VERSION ""

NS_ :

BS_:

BU_: RRSRR_FO LRSRR_FO CIPM_FO _DOFIMU2_FO _DOFIMU1_FO DMS_FO AMM_FO EOCM2B_IMX6_FO EOCM2B_K2_FO EOCM2B_K1_FO EOCM2A_IMX6_FO EOCM2A_K2_FO EOCM2A_K1_FO NVS_FO Dummy_FO TestTool_FO LRR_FO RFSRR_FO LFSRR_FO RSRR_FO VIS_FO EOCM_F_FO VIS2_FO
VAL_TABLE_ vt_BooleanValues 1 "true" 0 "false" ;
VAL_TABLE_ FrntVsnInPthVehBrkNwSt 10 "Active" 5 "Inactive" ;
VAL_TABLE_ FrntVsnClostPedBrkNwSt 10 "Active" 5 "Inactive" ;
VAL_TABLE_ DrvrMonSysEngSt 7 "Unused and Reserved 1" 6 "Recovering" 5 "Tracking" 4 "Searching" 3 "Video test port only" 2 "Idle" 1 "Invalid state" 0 "Does not exist or DME" ;
VAL_TABLE_ DrvrMonEngUnrecvrFltCod 7 "Unused and Reserved 3" 6 "Unused and Reserved 2" 5 "Unused and Reserved 1" 4 "Vehicle power supply Errors" 3 "Problem with LED illuminators" 2 "Vehicle input signals Errors" 1 "Problem with imager" 0 "Ok" ;
VAL_TABLE_ DrvrMonEngRecvrFltCod 3 "Engine is unable to find a face" 2 "Input Images too dark" 1 "Input images too bright" 0 "Ok" ;
VAL_TABLE_ DrvrMntrSysVTP 1 "Video test port active" 0 "Video test port inactive" ;
VAL_TABLE_ DrvrAttnStatCnfdc 3 "High" 2 "Medium" 1 "Low" 0 "Lowest" ;
VAL_TABLE_ DrvrAttnStat 7 "Invalid" 6 "Driver is exhibiting sleep" 5 "Driver is exhibiting microsleep" 4 "Attention is Center Console" 3 "Attention is Drivers Lap" 2 "Attention is Off Road" 1 "Attention is On Road" 0 "Unknown" ;
VAL_TABLE_ PPSMd 7 "GNSS and RTX and DR and MM" 6 "DR ONLY" 5 "GNSS and RTX and DR" 4 "GNSS and SBAS and DR" 3 "GNSS and DR" 2 "GNSS and  RTX" 1 "GNSS and SBAS" 0 "GNSS Standalone" ;
VAL_TABLE_ AdvDrvAstMpPrfShrtAcur 3 "Accuracy Is Unknown" 2 "Lowest Accuracy" 1 "Medium Accuracy" 0 "Highest Accuracy" ;
VAL_TABLE_ AdvDrAstMpStbRtOfWay 3 "Not Applicable" 2 "Unknown" 1 "Sub Path Has Right Of Way Over Path" 0 "Path Has Right Of Way Over Sub Path" ;
VAL_TABLE_ AdvDrAstMpStbPrtCalRut 3 "Not Applicable" 2 "Unknown" 1 "Path From This Point On Is Part Of Calculated Route" 0 "Path From This Point On Is Not Part Of Calculated Route" ;
VAL_TABLE_ AdvDrAstMpStbMsgTyp 7 "Unused and Reserved 2" 6 "Metadata" 5 "Profile Long" 4 "Profile Short" 3 "Stub" 2 "Segment" 1 "Position" 0 "Unused and Reserved 1" ;
VAL_TABLE_ AdvDrAstMpStbFmOfWay 15 "Not Applicable" 14 "Pedestrian Zone" 13 "Entrance To Or Exit To Service" 12 "Entrance To Or Exit Of A Car Park" 11 "Service Road Or Frontage Road" 10 "Slip Road per Ramp" 9 "Slip Road per Ramp On A Freeway Or Controlled Access Road" 8 "Parallel Road" 7 "Unused and Reserved 2" 6 "Unused and Reserved 1" 5 "Traffic Square per Special Traffic Figure" 4 "Roundabout Circle" 3 "Single Carriageway" 2 "Multiple Carriageway Or Multiply Digitized Road" 1 "Freeway Or Controlled Access Road That Is Not A Slip Road Or Ramp" 0 "Unknown" ;
VAL_TABLE_ AdvDrAstMpStbCmplxInsct 3 "Not Applicable" 2 "Unknown" 1 "Stub Is Part Of Complex Intersection" 0 "Stub Is Not Part Of Complex Intersection" ;
VAL_TABLE_ AdvDrAstMpSegTunl 3 "Not Applicable" 2 "Unknown" 1 "Segment Is Part Of Tunnel" 0 "Segment Is Not A Part Of Tunnel" ;
VAL_TABLE_ AdvDrAstMpSegPrtCalRut 3 "Not Applicable" 2 "Unknown" 1 "Segment Is Part Of Calculated Route" 0 "Segment Is Not Part Of Calculated Route" ;
VAL_TABLE_ AdvDrAstMpSegMsgTyp 7 "Unused and Reserved 2" 6 "Metadata" 5 "Profile Long" 4 "Profile Short" 3 "Stub" 2 "Segment" 1 "Position" 0 "Unused and Reserved 1" ;
VAL_TABLE_ AdvDrAstMpSegFrmOfWay 15 "Not Applicable" 14 "Pedestrian Zone" 13 "Entrance To Or Exit To Service" 12 "Entrance To Or Exit Of A Car Park" 11 "Service Road Or Frontage Road" 10 "Slip Road per Ramp" 9 "Slip Road per Ramp On A Freeway Or Controlled Access Road" 8 "Parallel Road" 7 "Unused and Reserved 2" 6 "Unused and Reserved 1" 5 "Traffic Square per Special Traffic Figure" 4 "Roundabout Circle" 3 "Single Carriageway" 2 "Multiple Carriageway Or Multiply Digitized Road" 1 "Freeway Or Controlled Access Road That Is Not A Slip Road or Ramp" 0 "Unknown" ;
VAL_TABLE_ AdvDrAstMpSegEffSdLmtTp 7 "Not Applicable" 6 "Explicit Snow" 5 "Explicit Rain" 4 "Explicit Time Of Day" 3 "Explicit By Day" 2 "Explicit By Night" 1 "Explicit On Traffic Sign" 0 "Implicit" ;
VAL_TABLE_ AdvDrAstMpSegDivdRd 3 "Not Applicable" 2 "Unknown" 1 "Segment Is Part Of Divided Road" 0 "Segment Is Not Part Of Divided Road" ;
VAL_TABLE_ AdvDrAstMpSegCmplxInsct 3 "Not Applicable" 2 "Unknown" 1 "Segment Is Part Of Complex Intersection" 0 "Segment Is Not Part Of Complex Intersection" ;
VAL_TABLE_ AdvDrAstMpSegBrdg 3 "Not Applicable" 2 "Unknown" 1 "Segment Is Part Of Bridge" 0 "Segment Not Part Of Bridge" ;
VAL_TABLE_ AdvDrAstMpSegBldUpAra 3 "Not Applicable" 2 "Unknown" 1 "Segment Is Part Of Built Up Area" 0 "Segment Is Not Part Of Built Up Area" ;
VAL_TABLE_ AdvDrAstMpMtdtSpdUnt 1 "Miles Per Hour" 0 "Kilometers Per Hour" ;
VAL_TABLE_ AdvDrAstMpMtdtDrvSd 1 "Driving Side Right" 0 "Driving Side Left" ;
VAL_TABLE_ WSMR_WiFiAssnReq 3 "Unexpected Undefined Connection Behavior" 2 "Wi Fi association failed with available credentials" 1 "Failed to receive Wi Fi credentials after 255 attempts" 0 "SSID and Passphrase Request" ;
VAL_TABLE_ StrgColCommsFlt 2 "Disabled Communications DTC" 1 "No Communications Fault" 0 "Communications Fault" ;
VAL_TABLE_ CPMAPINFO4 1 "Hardware Or Software Error" 0 "No Hardware Or Software Error" ;
VAL_TABLE_ AdvDrvAstMpPrfShrt2Acur 3 "Accuracy Is Unknown" 2 "Lowest Accuracy" 1 "Medium Accuracy" 0 "Highest Accuracy" ;
VAL_TABLE_ InterLghtStat 1 "Interior Lights On" 0 "Interior Light Off" ;
VAL_TABLE_ VehLnStatConf 2 "High Confidence" 1 "Low Confidence" 0 "No Confidence" 3 "Very High Confidence" ;
VAL_TABLE_ VehLnStat 3 "Lane Change To Right" 2 "Lane Change To Left" 1 "Staying in Lane" 0 "Unknown" ;
VAL_TABLE_ HrznPrvdRstRq 1 "Reset Not Required" 0 "Reset Required" ;
VAL_TABLE_ ExptNxtTrnstnDirConf 3 "Very High Confidence" 2 "High Confidence" 1 "Low Confidence" 0 "No Confidence" ;
VAL_TABLE_ ExptNxtTrnstnDir 7 "Reserved4" 6 "Reserved3" 5 "Reserved2" 4 "Reserved1" 3 "Traversing Middle Transition" 2 "Traversing Next Transition Right" 1 "Traversing Next Transition Left" 0 "Unknown" ;
VAL_TABLE_ ADASISMsgTypRetrans 7 "GM System Specific" 6 "Meta Data" 5 "Profile Long" 4 "Profile Short" 3 "Stub" 2 "Segment" 1 "Position" 0 "Checksum" ;
VAL_TABLE_ NVSysStat 7 "Needs Headlights" 6 "Temporarily Unavailable" 5 "Not Dark" 4 "Needs Service" 3 "Active" 2 "Inactive" 1 "Initializing" 0 "Unknown" ;
VAL_TABLE_ NVSysPedWrnIndReq 3 "Unused & Reserved" 2 "Pedestrian Alert" 1 "Pedestrian Detected" 0 "None" ;
VAL_TABLE_ NVSysPedDetCstReq 2 "On" 1 "Off" 0 "No Value" ;
VAL_TABLE_ NVSysPedDetCsCrStVal 2 "On" 1 "Off" 0 "No Value" ;
VAL_TABLE_ FwVsnCinCoutPotT9Rev 2 "Right" 1 "Left" 0 "None" ;
VAL_TABLE_ FwVsnCinCoutPotT8Rev 2 "Right" 1 "Left" 0 "None" ;
VAL_TABLE_ FwVsnCinCoutPotT7Rev 2 "Right" 1 "Left" 0 "None" ;
VAL_TABLE_ FwVsnCinCoutPotT6Rev 2 "Right" 1 "Left" 0 "None" ;
VAL_TABLE_ FwVsnCinCoutPotT5Rev 2 "Right" 1 "Left" 0 "None" ;
VAL_TABLE_ FwVsnCinCoutPotT4Rev 2 "Right" 1 "Left" 0 "None" ;
VAL_TABLE_ FwVsnCinCoutPotT3Rev 2 "Right" 1 "Left" 0 "None" ;
VAL_TABLE_ FwVsnCinCoutPotT2Rev 2 "Right" 1 "Left" 0 "None" ;
VAL_TABLE_ FwVsnCinCoutPotT1Rev 2 "Right" 1 "Left" 0 "None" ;
VAL_TABLE_ FwVsnCinCoutPotT12Rev 2 "Right" 1 "Left" 0 "None" ;
VAL_TABLE_ FwVsnCinCoutPotT11Rev 2 "Right" 1 "Left" 0 "None" ;
VAL_TABLE_ FwVsnCinCoutPotT10Rev 2 "Right" 1 "Left" 0 "None" ;
VAL_TABLE_ GFHBObjDirTrk8 1 "Ahead Traffic" 0 "Incoming Traffic" ;
VAL_TABLE_ GFHBObjDirTrk7 1 "Ahead Traffic" 0 "Incoming Traffic" ;
VAL_TABLE_ GFHBObjDirTrk6 1 "Ahead Traffic" 0 "Incoming Traffic" ;
VAL_TABLE_ GFHBObjDirTrk5 1 "Ahead Traffic" 0 "Incoming Traffic" ;
VAL_TABLE_ GFHBObjDirTrk4 1 "Ahead Traffic" 0 "Incoming Traffic" ;
VAL_TABLE_ GFHBObjDirTrk3 1 "Ahead Traffic" 0 "Incoming Traffic" ;
VAL_TABLE_ GFHBObjDirTrk2 1 "Ahead Traffic" 0 "Incoming Traffic" ;
VAL_TABLE_ GFHBObjDirTrk1 1 "Ahead Traffic" 0 "Incoming Traffic" ;
VAL_TABLE_ GFHBFwVsnRelLaneTrk8 3 "Left Lane" 2 "Right Lane" 1 "Host Lane" 0 "Unknown" ;
VAL_TABLE_ GFHBFwVsnRelLaneTrk7 3 "Left Lane" 2 "Right Lane" 1 "Host Lane" 0 "Unknown" ;
VAL_TABLE_ GFHBFwVsnRelLaneTrk6 3 "Left Lane" 2 "Right Lane" 1 "Host Lane" 0 "Unknown" ;
VAL_TABLE_ GFHBFwVsnRelLaneTrk5 3 "Left Lane" 2 "Right Lane" 1 "Host Lane" 0 "Unknown" ;
VAL_TABLE_ GFHBFwVsnRelLaneTrk4 3 "Left Lane" 2 "Right Lane" 1 "Host Lane" 0 "Unknown" ;
VAL_TABLE_ GFHBFwVsnRelLaneTrk3 3 "Left Lane" 2 "Right Lane" 1 "Host Lane" 0 "Unknown" ;
VAL_TABLE_ GFHBFwVsnRelLaneTrk2 3 "Left Lane" 2 "Right Lane" 1 "Host Lane" 0 "Unknown" ;
VAL_TABLE_ GFHBFwVsnRelLaneTrk1 3 "Left Lane" 2 "Right Lane" 1 "Host Lane" 0 "Unknown" ;
VAL_TABLE_ GFHBFwVsnMesStatTrk8 3 "Measured this cycle" 2 "Latent track not detected this cycle" 1 "New Object" 0 "No Object" ;
VAL_TABLE_ GFHBFwVsnMesStatTrk7 3 "Measured this cycle" 2 "Latent track not detected this cycle" 1 "New Object" 0 "No Object" ;
VAL_TABLE_ GFHBFwVsnMesStatTrk6 3 "Measured this cycle" 2 "Latent track not detected this cycle" 1 "New Object" 0 "No Object" ;
VAL_TABLE_ GFHBFwVsnMesStatTrk5 3 "Measured this cycle" 2 "Latent track not detected this cycle" 1 "New Object" 0 "No Object" ;
VAL_TABLE_ GFHBFwVsnMesStatTrk4 3 "Measured this cycle" 2 "Latent track not detected this cycle" 1 "New Object" 0 "No Object" ;
VAL_TABLE_ GFHBFwVsnMesStatTrk3 3 "Measured this cycle" 2 "Latent track not detected this cycle" 1 "New Object" 0 "No Object" ;
VAL_TABLE_ GFHBFwVsnMesStatTrk2 3 "Measured this cycle" 2 "Latent track not detected this cycle" 1 "New Object" 0 "No Object" ;
VAL_TABLE_ GFHBFwVsnMesStatTrk1 3 "Measured this cycle" 2 "Latent track not detected this cycle" 1 "New Object" 0 "No Object" ;
VAL_TABLE_ GFHBFwVsnCnfdncTrk8 3 "Confident" 2 "Speculative" 1 "Highly Speculative" 0 "Invalid" ;
VAL_TABLE_ GFHBFwVsnCnfdncTrk7 3 "Confident" 2 "Speculative" 1 "Highly Speculative" 0 "Invalid" ;
VAL_TABLE_ GFHBFwVsnCnfdncTrk6 3 "Confident" 2 "Speculative" 1 "Highly Speculative" 0 "Invalid" ;
VAL_TABLE_ GFHBFwVsnCnfdncTrk5 3 "Confident" 2 "Speculative" 1 "Highly Speculative" 0 "Invalid" ;
VAL_TABLE_ GFHBFwVsnCnfdncTrk4 3 "Confident" 2 "Speculative" 1 "Highly Speculative" 0 "Invalid" ;
VAL_TABLE_ GFHBFwVsnCnfdncTrk3 3 "Confident" 2 "Speculative" 1 "Highly Speculative" 0 "Invalid" ;
VAL_TABLE_ GFHBFwVsnCnfdncTrk2 3 "Confident" 2 "Speculative" 1 "Highly Speculative" 0 "Invalid" ;
VAL_TABLE_ GFHBFwVsnCnfdncTrk1 0 "Invalid" 3 "Confident" 2 "Speculative" 1 "Highly Speculative" ;
VAL_TABLE_ GFHBFVsnObjTypTrkRev8 12 "Cluster Object" 11 "Child Close to Danger Zone" 10 "Pedestrian Moving Out of Danger Zone" 9 "Pedestrian Moving Into Danger Zone" 8 "Pedestrian Standing Outside Danger Zone" 7 "No Object Present" 6 "Fixed Roadside Object" 5 "Fixed Overhead Object" 4 "Pedestrian" 3 "Motorcycle/ Bicycle" 2 "Large Vehicle (Semi)" 1 "4 Wheel Vehicle (Car)" 0 "Unknown" ;
VAL_TABLE_ GFHBFVsnObjTypTrkRev7 12 "Cluster Object" 11 "Child Close to Danger Zone" 10 "Pedestrian Moving Out of Danger Zone" 9 "Pedestrian Moving Into Danger Zone" 8 "Pedestrian Standing Outside Danger Zone" 7 "No Object Present" 6 "Fixed Roadside Object" 5 "Fixed Overhead Object" 4 "Pedestrian" 3 "Motorcycle/ Bicycle" 2 "Large Vehicle (Semi)" 1 "4 Wheel Vehicle (Car)" 0 "Unknown" ;
VAL_TABLE_ GFHBFVsnObjTypTrkRev6 12 "Cluster Object" 11 "Child Close to Danger Zone" 10 "Pedestrian Moving Out of Danger Zone" 9 "Pedestrian Moving Into Danger Zone" 8 "Pedestrian Standing Outside Danger Zone" 7 "No Object Present" 6 "Fixed Roadside Object" 5 "Fixed Overhead Object" 4 "Pedestrian" 3 "Motorcycle/ Bicycle" 2 "Large Vehicle (Semi)" 1 "4 Wheel Vehicle (Car)" 0 "Unknown" ;
VAL_TABLE_ GFHBFVsnObjTypTrkRev5 12 "Cluster Object" 11 "Child Close to Danger Zone" 10 "Pedestrian Moving Out of Danger Zone" 9 "Pedestrian Moving Into Danger Zone" 8 "Pedestrian Standing Outside Danger Zone" 7 "No Object Present" 6 "Fixed Roadside Object" 5 "Fixed Overhead Object" 4 "Pedestrian" 3 "Motorcycle/ Bicycle" 2 "Large Vehicle (Semi)" 1 "4 Wheel Vehicle (Car)" 0 "Unknown" ;
VAL_TABLE_ GFHBFVsnObjTypTrkRev4 12 "Cluster Object" 11 "Child Close to Danger Zone" 10 "Pedestrian Moving Out of Danger Zone" 9 "Pedestrian Moving Into Danger Zone" 8 "Pedestrian Standing Outside Danger Zone" 7 "No Object Present" 6 "Fixed Roadside Object" 5 "Fixed Overhead Object" 4 "Pedestrian" 3 "Motorcycle/ Bicycle" 2 "Large Vehicle (Semi)" 1 "4 Wheel Vehicle (Car)" 0 "Unknown" ;
VAL_TABLE_ GFHBFVsnObjTypTrkRev3 12 "Cluster Object" 11 "Child Close to Danger Zone" 10 "Pedestrian Moving Out of Danger Zone" 9 "Pedestrian Moving Into Danger Zone" 8 "Pedestrian Standing Outside Danger Zone" 7 "No Object Present" 6 "Fixed Roadside Object" 5 "Fixed Overhead Object" 4 "Pedestrian" 3 "Motorcycle/ Bicycle" 2 "Large Vehicle (Semi)" 1 "4 Wheel Vehicle (Car)" 0 "Unknown" ;
VAL_TABLE_ GFHBFVsnObjTypTrkRev2 12 "Cluster Object" 11 "Child Close to Danger Zone" 10 "Pedestrian Moving Out of Danger Zone" 9 "Pedestrian Moving Into Danger Zone" 8 "Pedestrian Standing Outside Danger Zone" 7 "No Object Present" 6 "Fixed Roadside Object" 5 "Fixed Overhead Object" 4 "Pedestrian" 3 "Motorcycle/ Bicycle" 2 "Large Vehicle (Semi)" 1 "4 Wheel Vehicle (Car)" 0 "Unknown" ;
VAL_TABLE_ GFHBFVsnObjTypTrkRev1 12 "Cluster Object" 11 "Child Close to Danger Zone" 10 "Pedestrian Moving Out of Danger Zone" 9 "Pedestrian Moving Into Danger Zone" 8 "Pedestrian Standing Outside Danger Zone" 7 "No Object Present" 6 "Fixed Roadside Object" 5 "Fixed Overhead Object" 4 "Pedestrian" 3 "Motorcycle/ Bicycle" 2 "Large Vehicle (Semi)" 1 "4 Wheel Vehicle (Car" 0 "Unknown" ;
VAL_TABLE_ CRL_Cnfdnc 7 "Reserved4" 6 "Reserved3" 5 "Reserved2" 4 "Reserved1" 3 "Best" 2 "Marking Present" 1 "Weak Marking" 0 "No Lane" ;
VAL_TABLE_ CLL_Cnfdnc 7 "Reserved4" 6 "Reserved3" 5 "Reserved2" 4 "Reserved1" 3 "Best" 2 "Marking Present" 1 "Weak Marking" 0 "No Lane" ;
VAL_TABLE_ VBBrkCtrlSt 4 "Release Control" 3 "Hold Vehicle" 2 "Apply Brake" 1 "Decrease Torque" 0 "No Action" ;
VAL_TABLE_ ObstacleType 6 "NO_OBJECT" 5 "OBJ_GUARDRAIL" 4 "OBJ_TUNNEL " 3 "OBJ_TRAFFIC_SIGN" 2 "OBJ_VEHICLE" 1 "OBJ_BRIDGE " 0 "OBJ_UNKNOWN" ;
VAL_TABLE_ VpathMode 2 "Mid Hi Speed" 1 "Low Speed" 0 "Disabled" ;
VAL_TABLE_ LaneChngStatus 2 "Lane Change Right" 1 "Lane Change Left" 0 "Idle" ;
VAL_TABLE_ TravelDirection 3 "Other (excessive side slip)" 2 "reverse / stopped in rvrs gear" 1 "Forward / stopped in frwd gear" 0 "Unknown" ;
VAL_TABLE_ TrueOrFalse 1 "true" 0 "false" ;
VAL_TABLE_ ModeCommand 5 "Sensing with Reduced Power" 4 "Undefined" 3 "Radio Silent" 2 "Sensing" 1 "Not Sensing" 0 "Undefined" ;
VAL_TABLE_ LaneSnsLLnPosValid 1 "Invalid" 0 "Valid" ;
VAL_TABLE_ LnSnsRLnPosValid 1 "Invalid" 0 "Valid" ;
VAL_TABLE_ Elevation 3 "Low " 2 "mid (reserved)" 1 "high " 0 "Unknown" ;
VAL_TABLE_ ModeCommandFdbk 5 "Sensing with reduced power" 4 "Undefined" 3 "Radio Silent" 2 "Sensing" 1 "Not Sensing" 0 "Undefined" ;
VAL_TABLE_ relativeLane 3 "Left Lane" 2 "Right Lane" 1 "Host Lane" 0 "Unknown" ;
VAL_TABLE_ RoadTypeInfo 5 "Constiction Zone Exit" 4 "Construction Zone Entry" 3 "Highway" 2 "Secondary Road" 1 "City" 0 "Unknown" ;
VAL_TABLE_ ObjectLossInfo 2 "elevation conditions" 1 "tight curve" 0 "not lost" ;
VAL_TABLE_ MeasurementStatus 3 "Measured this cycle" 2 "Latent track not detctd this cyc" 1 "New Object" 0 "No Object" ;
VAL_TABLE_ ObjectType 7 "no object present" 6 "fixed roadside object" 5 "fixed overhead object" 4 "pedestrian" 3 "motocycle  / bicycle" 2 "Large vehicle (semi)" 1 "4 Wheel Vehicle (car, small trk)" 0 "Unknown" ;
VAL_TABLE_ Confidence 3 "confident" 2 "speculative" 1 "highly speculative" 0 "invalid" ;
VAL_TABLE_ DynamicProp 4 "Moving in opposite direction" 3 "Moving in same direction as host" 2 "Has moved but currently stopped" 1 "Has never moved" 0 "Unknown" ;
VAL_TABLE_ DrvWndPosSt 6 "Fully Opened" 5 "Open More Than C" 4 "Position C" 3 "Position B" 2 "Position A" 1 "Open Less Than A" 0 "Fully Closed" ;
VAL_TABLE_ VehMovSta 4 "Invalid" 3 "Reverse" 2 "Forward" 1 "Neutral" 0 "Parked" ;
VAL_TABLE_ OtsdAmbtLtLvlStat 2 "Day" 1 "Night" 0 "Unknown" ;
VAL_TABLE_ RtTrnLmpAtv 2 "On with telltale" 1 "On without telltale" 0 "Off" ;
VAL_TABLE_ LftTrnLmpAtv 2 "On with telltale" 1 "On without telltale" 0 "Off" ;
VAL_TABLE_ HdlmpBmSelectStat 2 "High Beams" 1 "Low Beams" 0 "Unknown" ;
VAL_TABLE_ DTCI_DTCFaultType 3 "Type C" 2 "Type B" 1 "Type A" 0 "Not Supported" ;
VAL_TABLE_ TrnsShftLvrPos 13 "Forward Range J" 12 "Forward Range I" 15 "Lever Position Unknown" 11 "Forward Range H" 10 "Forward Range G" 9 "Forward Range F" 8 "Forward Range E" 7 "Forward Range D" 6 "Forward Range C" 5 "Forward Range B" 4 "Forward Range A" 3 "Neutral Range" 2 "Reverse Range" 1 "Park Range" 0 "Between Ranges" ;
VAL_TABLE_ SysPwrMd 3 "Crank Request" 2 "Run" 1 "Accessory" 0 "Off" ;
VAL_TABLE_ ValidityStates 1 "Invalid" 0 "Valid" ;

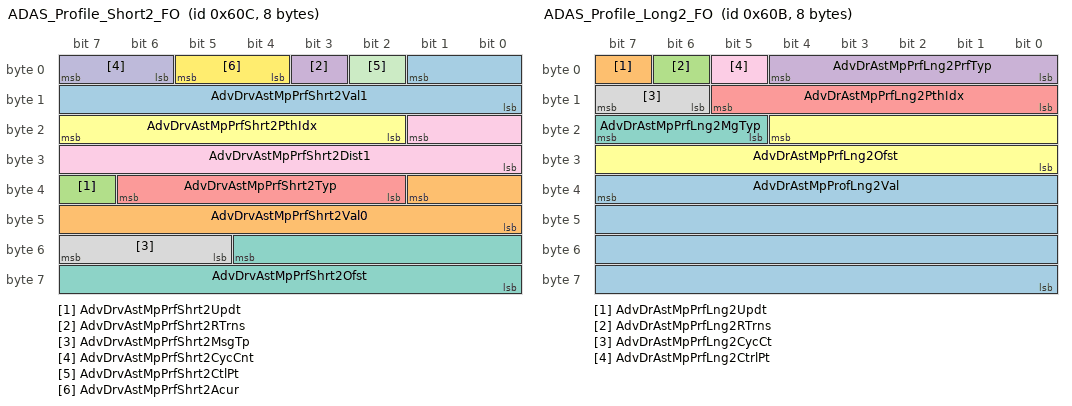
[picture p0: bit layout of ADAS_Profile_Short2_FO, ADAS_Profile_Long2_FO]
BO_ 1548 ADAS_Profile_Short2_FO: 8 AMM_FO
 SG_ AdvDrvAstMpPrfShrt2Val1 : 1|10@0+ (1,0) [0|1023] ""  EOCM2A_IMX6_FO,EOCM2A_K2_FO,EOCM2A_K1_FO,EOCM2B_IMX6_FO,EOCM2B_K2_FO,EOCM2B_K1_FO
 SG_ AdvDrvAstMpPrfShrt2Val0 : 33|10@0+ (1,0) [0|1023] ""  EOCM2A_IMX6_FO,EOCM2A_K2_FO,EOCM2A_K1_FO,EOCM2B_IMX6_FO,EOCM2B_K2_FO,EOCM2B_K1_FO
 SG_ AdvDrvAstMpPrfShrt2Updt : 39|1@0+ (1,0) [0|1] ""  EOCM2A_IMX6_FO,EOCM2A_K2_FO,EOCM2A_K1_FO,EOCM2B_IMX6_FO,EOCM2B_K2_FO,EOCM2B_K1_FO
 SG_ AdvDrvAstMpPrfShrt2RTrns : 3|1@0+ (1,0) [0|1] ""  EOCM2A_IMX6_FO,EOCM2A_K2_FO,EOCM2A_K1_FO,EOCM2B_IMX6_FO,EOCM2B_K2_FO,EOCM2B_K1_FO
 SG_ AdvDrvAstMpPrfShrt2Typ : 38|5@0+ (1,0) [0|31] ""  EOCM2A_IMX6_FO,EOCM2A_K2_FO,EOCM2A_K1_FO,EOCM2B_IMX6_FO,EOCM2B_K2_FO,EOCM2B_K1_FO
 SG_ AdvDrvAstMpPrfShrt2PthIdx : 23|6@0+ (1,0) [0|63] ""  EOCM2A_IMX6_FO,EOCM2A_K2_FO,EOCM2A_K1_FO,EOCM2B_IMX6_FO,EOCM2B_K2_FO,EOCM2B_K1_FO
 SG_ AdvDrvAstMpPrfShrt2Ofst : 52|13@0+ (1,0) [0|8191] "m"  EOCM2A_IMX6_FO,EOCM2A_K2_FO,EOCM2A_K1_FO,EOCM2B_IMX6_FO,EOCM2B_K2_FO,EOCM2B_K1_FO
 SG_ AdvDrvAstMpPrfShrt2MsgTp : 55|3@0+ (1,0) [0|7] ""  EOCM2A_IMX6_FO,EOCM2A_K2_FO,EOCM2A_K1_FO,EOCM2B_IMX6_FO,EOCM2B_K2_FO,EOCM2B_K1_FO
 SG_ AdvDrvAstMpPrfShrt2Dist1 : 17|10@0+ (1,0) [0|1023] "m"  EOCM2A_IMX6_FO,EOCM2A_K2_FO,EOCM2A_K1_FO,EOCM2B_IMX6_FO,EOCM2B_K2_FO,EOCM2B_K1_FO
 SG_ AdvDrvAstMpPrfShrt2CycCnt : 7|2@0+ (1,0) [0|3] ""  EOCM2A_IMX6_FO,EOCM2A_K2_FO,EOCM2A_K1_FO,EOCM2B_IMX6_FO,EOCM2B_K2_FO,EOCM2B_K1_FO
 SG_ AdvDrvAstMpPrfShrt2CtlPt : 2|1@0+ (1,0) [0|1] ""  EOCM2A_IMX6_FO,EOCM2A_K2_FO,EOCM2A_K1_FO,EOCM2B_IMX6_FO,EOCM2B_K2_FO,EOCM2B_K1_FO
 SG_ AdvDrvAstMpPrfShrt2Acur : 5|2@0+ (1,0) [0|3] ""  EOCM2A_IMX6_FO,EOCM2A_K2_FO,EOCM2A_K1_FO,EOCM2B_IMX6_FO,EOCM2B_K2_FO,EOCM2B_K1_FO

BO_ 1547 ADAS_Profile_Long2_FO: 8 AMM_FO
 SG_ AdvDrAstMpProfLng2Val : 39|32@0+ (1,0) [0|4294967295] ""  EOCM2A_IMX6_FO,EOCM2A_K2_FO,EOCM2A_K1_FO,EOCM2B_IMX6_FO,EOCM2B_K2_FO,EOCM2B_K1_FO
 SG_ AdvDrAstMpPrfLng2Updt : 7|1@0+ (1,0) [0|1] ""  EOCM2A_IMX6_FO,EOCM2A_K2_FO,EOCM2A_K1_FO,EOCM2B_IMX6_FO,EOCM2B_K2_FO,EOCM2B_K1_FO
 SG_ AdvDrAstMpPrfLng2RTrns : 6|1@0+ (1,0) [0|1] ""  EOCM2A_IMX6_FO,EOCM2A_K2_FO,EOCM2A_K1_FO,EOCM2B_IMX6_FO,EOCM2B_K2_FO,EOCM2B_K1_FO
 SG_ AdvDrAstMpPrfLng2PrfTyp : 4|5@0+ (1,0) [0|31] ""  EOCM2A_IMX6_FO,EOCM2A_K2_FO,EOCM2A_K1_FO,EOCM2B_IMX6_FO,EOCM2B_K2_FO,EOCM2B_K1_FO
 SG_ AdvDrAstMpPrfLng2PthIdx : 13|6@0+ (1,0) [0|63] ""  EOCM2A_IMX6_FO,EOCM2A_K2_FO,EOCM2A_K1_FO,EOCM2B_IMX6_FO,EOCM2B_K2_FO,EOCM2B_K1_FO
 SG_ AdvDrAstMpPrfLng2Ofst : 20|13@0+ (1,0) [0|8191] "m"  EOCM2A_IMX6_FO,EOCM2A_K2_FO,EOCM2A_K1_FO,EOCM2B_IMX6_FO,EOCM2B_K2_FO,EOCM2B_K1_FO
 SG_ AdvDrAstMpPrfLng2MgTyp : 23|3@0+ (1,0) [0|7] ""  EOCM2A_IMX6_FO,EOCM2A_K2_FO,EOCM2A_K1_FO,EOCM2B_IMX6_FO,EOCM2B_K2_FO,EOCM2B_K1_FO
 SG_ AdvDrAstMpPrfLng2CycCt : 15|2@0+ (1,0) [0|3] ""  EOCM2A_IMX6_FO,EOCM2A_K2_FO,EOCM2A_K1_FO,EOCM2B_IMX6_FO,EOCM2B_K2_FO,EOCM2B_K1_FO
 SG_ AdvDrAstMpPrfLng2CtrlPt : 5|1@0+ (1,0) [0|1] ""  EOCM2A_IMX6_FO,EOCM2A_K2_FO,EOCM2A_K1_FO,EOCM2B_IMX6_FO,EOCM2B_K2_FO,EOCM2B_K1_FO

BO_ 1630 USDT_Resp_From_EOCM2B_K2_FO: 8 EOCM2B_K2_FO
 SG_ DgnInf : 7|64@0+ (1,0) [0|1.84467440737096E+019] ""  TestTool_FO

BO_ 1374 UUDT_Resp_From_EOCM2B_K2_FO: 8 EOCM2B_K2_FO
 SG_ DgnInf : 7|64@0+ (1,0) [0|1.84467440737096E+019] ""  TestTool_FO

BO_ 606 USDT_Req_to_EOCM2B_K2_FO: 8 TestTool_FO
 SG_ DgnInf : 7|64@0+ (1,0) [0|1.84467440737096E+019] ""  EOCM2B_K2_FO

BO_ 328 Vehicle_Info_FO: 5 EOCM2A_K1_FO
 SG_ StrWhAngGrd : 27|12@0- (1,0) [-2048|2047] "deg/sec"  DMS_FO
 SG_ TrnsShftLvrPos : 31|4@0+ (1,0) [0|15] ""  DMS_FO
 SG_ StrWhAng_148 : 15|16@0- (0.0625,0) [-2048|2047.9375] "deg"  DMS_FO
 SG_ TrnsShftLvrPosV : 3|1@0+ (1,0) [0|1] ""  DMS_FO
 SG_ StrWhAngV_148 : 4|1@0+ (1,0) [0|1] ""  DMS_FO
 SG_ StrWhAngMsk_148 : 5|1@0+ (1,0) [0|1] ""  DMS_FO
 SG_ StrWhAngGrdV : 6|1@0+ (1,0) [0|1] ""  DMS_FO
 SG_ StrWhAngGrdMsk : 7|1@0+ (1,0) [0|1] ""  DMS_FO

BO_ 1930 DTC_Triggered_78A_FO: 7 LRSRR_FO
 SG_ DTCI_CodeSupported_78A : 40|1@0+ (1,0) [0|1] ""  TestTool_FO
 SG_ DTCI_CurrentStatus_78A : 41|1@0+ (1,0) [0|1] ""  TestTool_FO
 SG_ DTCI_DTCFailType_78A : 39|8@0+ (1,0) [0|255] ""  TestTool_FO
 SG_ DTCI_DTCFaultType_78A : 55|8@0+ (1,0) [0|255] ""  TestTool_FO
 SG_ DTCI_DTCNumber_78A : 23|16@0+ (1,0) [0|65535] ""  TestTool_FO
 SG_ DTCI_DTCSource_78A : 15|8@0+ (1,0) [0|255] ""  TestTool_FO
 SG_ DTCI_DTCTriggered_78A : 0|1@0+ (1,0) [0|1] ""  TestTool_FO
 SG_ DTCI_HistStat_78A : 44|1@0+ (1,0) [0|1] ""  TestTool_FO
 SG_ DTCI_TstFldCdClrdStat_78A : 43|1@0+ (1,0) [0|1] ""  TestTool_FO
 SG_ DTCI_TstFldPwrUpSt_78A : 46|1@0+ (1,0) [0|1] ""  TestTool_FO
 SG_ DTCI_TstNPsdCdClrdSt_78A : 42|1@0+ (1,0) [0|1] ""  TestTool_FO
 SG_ DTCI_TstNPsdPwrUpSt_78A : 45|1@0+ (1,0) [0|1] ""  TestTool_FO
 SG_ DTCIUnused1_78A : 7|1@0+ (1,0) [0|1] ""  TestTool_FO
 SG_ DTCIUnused2_78A : 6|1@0+ (1,0) [0|1] ""  TestTool_FO
 SG_ DTCIUnused3_78A : 5|1@0+ (1,0) [0|1] ""  TestTool_FO
 SG_ DTCIUnused4_78A : 4|1@0+ (1,0) [0|1] ""  TestTool_FO
 SG_ DTCIUnused5_78A : 3|1@0+ (1,0) [0|1] ""  TestTool_FO
 SG_ DTCIUnused6_78A : 2|1@0+ (1,0) [0|1] ""  TestTool_FO
 SG_ DTCIUnused7_78A : 1|1@0+ (1,0) [0|1] ""  TestTool_FO
 SG_ DTCI_WrnIndRqdSt_78A : 47|1@0+ (1,0) [0|1] ""  TestTool_FO

BO_ 1624 USDT_Resp_From_LRSRR: 8 LRSRR_FO
 SG_ DgnInf : 7|64@0+ (1,0) [0|1.84467440737096E+019] ""  TestTool_FO

BO_ 1368 UUDT_Resp_From_LRSRR: 8 LRSRR_FO
 SG_ DgnInf : 7|64@0+ (1,0) [0|1.84467440737096E+019] ""  TestTool_FO

BO_ 600 USDT_Req_to_LRSRR: 8 TestTool_FO
 SG_ DgnInf : 7|64@0+ (1,0) [0|1.84467440737096E+019] ""  LRSRR_FO

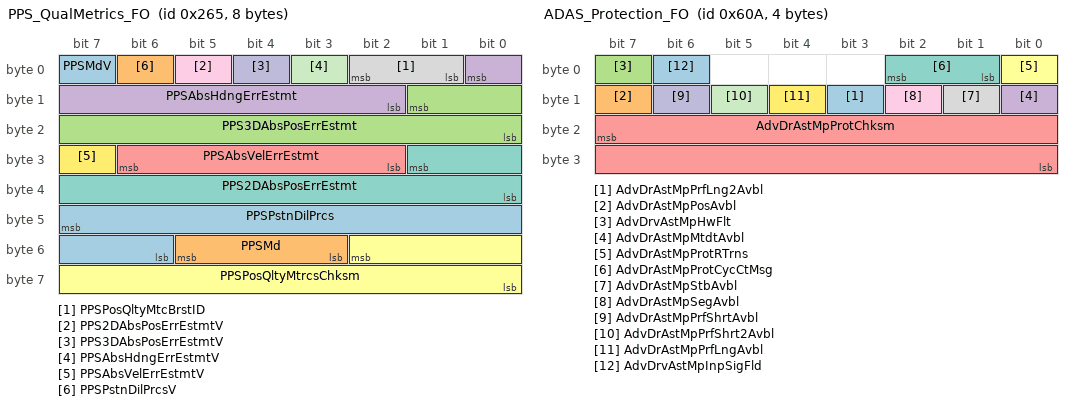
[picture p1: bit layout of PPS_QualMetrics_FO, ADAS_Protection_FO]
BO_ 613 PPS_QualMetrics_FO: 8 EOCM2A_K1_FO
 SG_ PPSPstnDilPrcs : 47|10@0+ (0.1,0) [0|102.3] ""  EOCM2B_IMX6_FO,EOCM2B_K2_FO,EOCM2B_K1_FO,AMM_FO
 SG_ PPSMd : 53|3@0+ (1,0) [0|7] ""  EOCM2B_IMX6_FO,EOCM2B_K2_FO,EOCM2B_K1_FO,AMM_FO
 SG_ PPS3DAbsPosErrEstmt : 9|10@0+ (0.1,0) [0|102.3] ""  EOCM2B_IMX6_FO,EOCM2B_K2_FO,EOCM2B_K1_FO,AMM_FO
 SG_ PPSAbsHdngErrEstmt : 0|7@0+ (0.5,0) [0|63.5] ""  EOCM2B_IMX6_FO,EOCM2B_K2_FO,EOCM2B_K1_FO,AMM_FO
 SG_ PPSAbsVelErrEstmt : 30|5@0+ (1,0) [0|31] ""  EOCM2B_IMX6_FO,EOCM2B_K2_FO,EOCM2B_K1_FO,AMM_FO
 SG_ PPSPosQltyMtrcsChksm : 50|11@0+ (1,0) [0|2047] ""  EOCM2B_IMX6_FO,EOCM2B_K2_FO,EOCM2B_K1_FO,AMM_FO
 SG_ PPS2DAbsPosErrEstmt : 25|10@0+ (0.1,0) [0|102.3] ""  EOCM2B_IMX6_FO,EOCM2B_K2_FO,EOCM2B_K1_FO,AMM_FO
 SG_ PPSPosQltyMtcBrstID : 2|2@0+ (1,0) [0|3] ""  EOCM2B_IMX6_FO,EOCM2B_K2_FO,EOCM2B_K1_FO,AMM_FO
 SG_ PPS2DAbsPosErrEstmtV : 5|1@0+ (1,0) [0|1] ""  EOCM2B_IMX6_FO,EOCM2B_K2_FO,EOCM2B_K1_FO,AMM_FO
 SG_ PPS3DAbsPosErrEstmtV : 4|1@0+ (1,0) [0|1] ""  EOCM2B_IMX6_FO,EOCM2B_K2_FO,EOCM2B_K1_FO,AMM_FO
 SG_ PPSAbsHdngErrEstmtV : 3|1@0+ (1,0) [0|1] ""  EOCM2B_IMX6_FO,EOCM2B_K2_FO,EOCM2B_K1_FO,AMM_FO
 SG_ PPSAbsVelErrEstmtV : 31|1@0+ (1,0) [0|1] ""  EOCM2B_IMX6_FO,EOCM2B_K2_FO,EOCM2B_K1_FO,AMM_FO
 SG_ PPSMdV : 7|1@0+ (1,0) [0|1] ""  EOCM2B_IMX6_FO,EOCM2B_K2_FO,EOCM2B_K1_FO,AMM_FO
 SG_ PPSPstnDilPrcsV : 6|1@0+ (1,0) [0|1] ""  EOCM2B_IMX6_FO,EOCM2B_K2_FO,EOCM2B_K1_FO,AMM_FO

BO_ 612 PPS_Time_FO: 8 EOCM2A_K1_FO
 SG_ PPSTmdayV : 2|1@0+ (1,0) [0|1] ""  EOCM2B_IMX6_FO,EOCM2B_K2_FO,EOCM2B_K1_FO,AMM_FO
 SG_ PPSCldrDayV : 0|1@0+ (1,0) [0|1] ""  EOCM2B_IMX6_FO,EOCM2B_K2_FO,EOCM2B_K1_FO,AMM_FO
 SG_ PPSCldrDay : 8|9@0+ (1,0) [0|511] ""  EOCM2B_IMX6_FO,EOCM2B_K2_FO,EOCM2B_K1_FO,AMM_FO
 SG_ PPSTmBrstID : 52|2@0+ (1,0) [0|3] ""  EOCM2B_IMX6_FO,EOCM2B_K2_FO,EOCM2B_K1_FO,AMM_FO
 SG_ PPSTmday : 31|27@0+ (1,0) [0|134217727] "ms"  EOCM2B_IMX6_FO,EOCM2B_K2_FO,EOCM2B_K1_FO,AMM_FO
 SG_ PPSTmChksm : 50|11@0+ (1,0) [0|2047] ""  EOCM2B_IMX6_FO,EOCM2B_K2_FO,EOCM2B_K1_FO,AMM_FO
 SG_ PPSCldrYrV : 1|1@0+ (1,0) [0|1] ""  EOCM2B_IMX6_FO,EOCM2B_K2_FO,EOCM2B_K1_FO,AMM_FO
 SG_ PPSCldrYr : 15|7@0+ (1,2014) [2014|2141] ""  EOCM2B_IMX6_FO,EOCM2B_K2_FO,EOCM2B_K1_FO,AMM_FO

BO_ 611 PPS_SigAcqTime_FO: 6 EOCM2A_K1_FO
 SG_ PPSSigAqTmBrstID : 38|2@0+ (1,0) [0|3] ""  EOCM2B_IMX6_FO,EOCM2B_K2_FO,EOCM2B_K1_FO,AMM_FO
 SG_ PPSSigAcqTmV : 39|1@0+ (1,0) [0|1] ""  EOCM2B_IMX6_FO,EOCM2B_K2_FO,EOCM2B_K1_FO,AMM_FO
 SG_ PPSSigAcqTm : 7|32@0+ (1,0) [0|4294967295] ""  EOCM2B_IMX6_FO,EOCM2B_K2_FO,EOCM2B_K1_FO,AMM_FO
 SG_ PPSSigAqTmChksm : 34|11@0+ (1,0) [0|2047] ""  EOCM2B_IMX6_FO,EOCM2B_K2_FO,EOCM2B_K1_FO,AMM_FO

BO_ 610 PPS_PosLong_FO: 6 EOCM2A_K1_FO
 SG_ PPSLongBrstID : 39|2@0+ (1,0) [0|3] ""  EOCM2B_IMX6_FO,EOCM2B_K2_FO,EOCM2B_K1_FO,AMM_FO
 SG_ PPSLong : 6|31@0- (1,0) [-1073741824|1073741823] ""  EOCM2B_IMX6_FO,EOCM2B_K2_FO,EOCM2B_K1_FO,AMM_FO
 SG_ PPSLongV : 7|1@0+ (1,0) [0|1] ""  EOCM2B_IMX6_FO,EOCM2B_K2_FO,EOCM2B_K1_FO,AMM_FO
 SG_ PPSLongChksm : 34|11@0+ (1,0) [0|2047] ""  EOCM2B_IMX6_FO,EOCM2B_K2_FO,EOCM2B_K1_FO,AMM_FO

BO_ 609 PPS_PosLat_FO: 6 EOCM2A_K1_FO
 SG_ PPSLatV : 7|1@0+ (1,0) [0|1] ""  EOCM2B_IMX6_FO,EOCM2B_K2_FO,EOCM2B_K1_FO,AMM_FO
 SG_ PPSLatChksm : 34|11@0+ (1,0) [0|2047] ""  EOCM2B_IMX6_FO,EOCM2B_K2_FO,EOCM2B_K1_FO,AMM_FO
 SG_ PPSLatBrstID : 36|2@0+ (1,0) [0|3] ""  EOCM2B_IMX6_FO,EOCM2B_K2_FO,EOCM2B_K1_FO,AMM_FO
 SG_ PPSLat : 5|30@0- (1,0) [-536870912|536870911] ""  EOCM2B_IMX6_FO,EOCM2B_K2_FO,EOCM2B_K1_FO,AMM_FO

BO_ 1160 PassPhrase_3_AMM_FO: 8 EOCM2A_K1_FO
 SG_ WiFiPssPhrsDgts17to24_Mp : 7|64@0+ (1,0) [0|0] ""  EOCM2B_K1_FO,AMM_FO

BO_ 1159 PassPhrase_2_AMM_FO: 8 EOCM2A_K1_FO
 SG_ WiFiPssPhrsDgts9to16_Mp : 7|64@0+ (1,0) [0|0] ""  EOCM2B_K1_FO,AMM_FO

BO_ 1158 PassPhrase_1_AMM_FO: 8 EOCM2A_K1_FO
 SG_ WiFiPssPhrsDgts1to8_Mp : 7|64@0+ (1,0) [0|0] ""  EOCM2B_K1_FO,AMM_FO

BO_ 1546 ADAS_Protection_FO: 4 AMM_FO
 SG_ AdvDrAstMpPrfLng2Avbl : 11|1@0+ (1,0) [0|1] ""  EOCM2A_IMX6_FO,EOCM2A_K2_FO,EOCM2A_K1_FO,EOCM2B_IMX6_FO,EOCM2B_K2_FO,EOCM2B_K1_FO
 SG_ AdvDrAstMpPosAvbl : 15|1@0+ (1,0) [0|1] ""  EOCM2A_IMX6_FO,EOCM2A_K2_FO,EOCM2A_K1_FO,EOCM2B_IMX6_FO,EOCM2B_K2_FO,EOCM2B_K1_FO
 SG_ AdvDrvAstMpHwFlt : 7|1@0+ (1,0) [0|1] ""  EOCM2B_IMX6_FO,EOCM2B_K2_FO,EOCM2B_K1_FO,EOCM2A_IMX6_FO,EOCM2A_K2_FO,EOCM2A_K1_FO
 SG_ AdvDrAstMpMtdtAvbl : 8|1@0+ (1,0) [0|1] ""  EOCM2A_IMX6_FO,EOCM2A_K2_FO,EOCM2A_K1_FO,EOCM2B_IMX6_FO,EOCM2B_K2_FO,EOCM2B_K1_FO
 SG_ AdvDrAstMpProtChksm : 23|16@0+ (1,0) [0|65535] ""  EOCM2A_IMX6_FO,EOCM2A_K2_FO,EOCM2A_K1_FO,EOCM2B_IMX6_FO,EOCM2B_K2_FO,EOCM2B_K1_FO
 SG_ AdvDrAstMpProtRTrns : 0|1@0+ (1,0) [0|1] ""  EOCM2B_IMX6_FO,EOCM2B_K2_FO,EOCM2B_K1_FO,EOCM2A_IMX6_FO,EOCM2A_K2_FO,EOCM2A_K1_FO
 SG_ AdvDrAstMpProtCycCtMsg : 2|2@0+ (1,0) [0|3] ""  EOCM2B_IMX6_FO,EOCM2B_K2_FO,EOCM2B_K1_FO,EOCM2A_IMX6_FO,EOCM2A_K2_FO,EOCM2A_K1_FO
 SG_ AdvDrAstMpStbAvbl : 9|1@0+ (1,0) [0|1] ""  EOCM2A_IMX6_FO,EOCM2A_K2_FO,EOCM2A_K1_FO,EOCM2B_IMX6_FO,EOCM2B_K2_FO,EOCM2B_K1_FO
 SG_ AdvDrAstMpSegAvbl : 10|1@0+ (1,0) [0|1] ""  EOCM2A_IMX6_FO,EOCM2A_K2_FO,EOCM2A_K1_FO,EOCM2B_IMX6_FO,EOCM2B_K2_FO,EOCM2B_K1_FO
 SG_ AdvDrAstMpPrfShrtAvbl : 14|1@0+ (1,0) [0|1] ""  EOCM2A_IMX6_FO,EOCM2A_K2_FO,EOCM2A_K1_FO,EOCM2B_IMX6_FO,EOCM2B_K2_FO,EOCM2B_K1_FO
 SG_ AdvDrAstMpPrfShrt2Avbl : 13|1@0+ (1,0) [0|1] ""  EOCM2A_IMX6_FO,EOCM2A_K2_FO,EOCM2A_K1_FO,EOCM2B_IMX6_FO,EOCM2B_K2_FO,EOCM2B_K1_FO
 SG_ AdvDrAstMpPrfLngAvbl : 12|1@0+ (1,0) [0|1] ""  EOCM2A_IMX6_FO,EOCM2A_K2_FO,EOCM2A_K1_FO,EOCM2B_IMX6_FO,EOCM2B_K2_FO,EOCM2B_K1_FO
 SG_ AdvDrvAstMpInpSigFld : 6|1@0+ (1,0) [0|1] ""  EOCM2B_IMX6_FO,EOCM2B_K2_FO,EOCM2B_K1_FO,EOCM2A_IMX6_FO,EOCM2A_K2_FO,EOCM2A_K1_FO

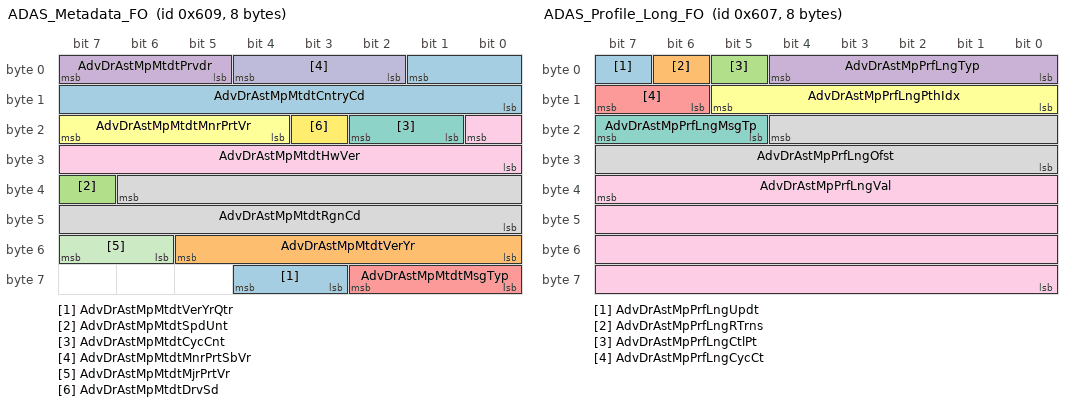
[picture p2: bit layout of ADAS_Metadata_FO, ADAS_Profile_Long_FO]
BO_ 1545 ADAS_Metadata_FO: 8 AMM_FO
 SG_ AdvDrAstMpMtdtVerYrQtr : 60|2@0+ (1,1) [1|4] "Qtr"  EOCM2B_IMX6_FO,EOCM2B_K2_FO,EOCM2B_K1_FO,EOCM2A_IMX6_FO,EOCM2A_K2_FO,EOCM2A_K1_FO
 SG_ AdvDrAstMpMtdtVerYr : 53|6@0+ (1,2000) [2000|2063] "Year"  EOCM2B_IMX6_FO,EOCM2B_K2_FO,EOCM2B_K1_FO,EOCM2A_IMX6_FO,EOCM2A_K2_FO,EOCM2A_K1_FO
 SG_ AdvDrAstMpMtdtSpdUnt : 39|1@0+ (1,0) [0|1] ""  EOCM2B_IMX6_FO,EOCM2B_K2_FO,EOCM2B_K1_FO,EOCM2A_IMX6_FO,EOCM2A_K2_FO,EOCM2A_K1_FO
 SG_ AdvDrAstMpMtdtPrvdr : 7|3@0+ (1,0) [0|7] ""  EOCM2B_IMX6_FO,EOCM2B_K2_FO,EOCM2B_K1_FO,EOCM2A_IMX6_FO,EOCM2A_K2_FO,EOCM2A_K1_FO
 SG_ AdvDrAstMpMtdtMsgTyp : 58|3@0+ (1,0) [0|7] ""  EOCM2B_IMX6_FO,EOCM2B_K2_FO,EOCM2B_K1_FO,EOCM2A_IMX6_FO,EOCM2A_K2_FO,EOCM2A_K1_FO
 SG_ AdvDrAstMpMtdtMnrPrtVr : 23|4@0+ (1,0) [0|15] ""  EOCM2B_IMX6_FO,EOCM2B_K2_FO,EOCM2B_K1_FO,EOCM2A_IMX6_FO,EOCM2A_K2_FO,EOCM2A_K1_FO
 SG_ AdvDrAstMpMtdtCycCnt : 18|2@0+ (1,0) [0|3] ""  EOCM2B_IMX6_FO,EOCM2B_K2_FO,EOCM2B_K1_FO,EOCM2A_IMX6_FO,EOCM2A_K2_FO,EOCM2A_K1_FO
 SG_ AdvDrAstMpMtdtRgnCd : 38|15@0+ (1,0) [0|32767] ""  EOCM2B_IMX6_FO,EOCM2B_K2_FO,EOCM2B_K1_FO,EOCM2A_IMX6_FO,EOCM2A_K2_FO,EOCM2A_K1_FO
 SG_ AdvDrAstMpMtdtHwVer : 16|9@0+ (1,0) [0|511] ""  EOCM2B_IMX6_FO,EOCM2B_K2_FO,EOCM2B_K1_FO,EOCM2A_IMX6_FO,EOCM2A_K2_FO,EOCM2A_K1_FO
 SG_ AdvDrAstMpMtdtMnrPrtSbVr : 4|3@0+ (1,0) [0|7] ""  EOCM2B_IMX6_FO,EOCM2B_K2_FO,EOCM2B_K1_FO,EOCM2A_IMX6_FO,EOCM2A_K2_FO,EOCM2A_K1_FO
 SG_ AdvDrAstMpMtdtMjrPrtVr : 55|2@0+ (1,0) [0|3] ""  EOCM2B_IMX6_FO,EOCM2B_K2_FO,EOCM2B_K1_FO,EOCM2A_IMX6_FO,EOCM2A_K2_FO,EOCM2A_K1_FO
 SG_ AdvDrAstMpMtdtDrvSd : 19|1@0+ (1,0) [0|1] ""  EOCM2B_IMX6_FO,EOCM2B_K2_FO,EOCM2B_K1_FO,EOCM2A_IMX6_FO,EOCM2A_K2_FO,EOCM2A_K1_FO
 SG_ AdvDrAstMpMtdtCntryCd : 1|10@0+ (1,0) [0|1023] ""  EOCM2B_IMX6_FO,EOCM2B_K2_FO,EOCM2B_K1_FO,EOCM2A_IMX6_FO,EOCM2A_K2_FO,EOCM2A_K1_FO

BO_ 1543 ADAS_Profile_Long_FO: 8 AMM_FO
 SG_ AdvDrAstMpPrfLngUpdt : 7|1@0+ (1,0) [0|1] ""  EOCM2B_IMX6_FO,EOCM2B_K2_FO,EOCM2B_K1_FO,EOCM2A_IMX6_FO,EOCM2A_K2_FO,EOCM2A_K1_FO
 SG_ AdvDrAstMpPrfLngRTrns : 6|1@0+ (1,0) [0|1] ""  EOCM2B_IMX6_FO,EOCM2B_K2_FO,EOCM2B_K1_FO,EOCM2A_IMX6_FO,EOCM2A_K2_FO,EOCM2A_K1_FO
 SG_ AdvDrAstMpPrfLngCtlPt : 5|1@0+ (1,0) [0|1] ""  EOCM2B_IMX6_FO,EOCM2B_K2_FO,EOCM2B_K1_FO,EOCM2A_IMX6_FO,EOCM2A_K2_FO,EOCM2A_K1_FO
 SG_ AdvDrAstMpPrfLngTyp : 4|5@0+ (1,0) [0|31] ""  EOCM2B_IMX6_FO,EOCM2B_K2_FO,EOCM2B_K1_FO,EOCM2A_IMX6_FO,EOCM2A_K2_FO,EOCM2A_K1_FO
 SG_ AdvDrAstMpPrfLngCycCt : 15|2@0+ (1,0) [0|3] ""  EOCM2B_IMX6_FO,EOCM2B_K2_FO,EOCM2B_K1_FO,EOCM2A_IMX6_FO,EOCM2A_K2_FO,EOCM2A_K1_FO
 SG_ AdvDrAstMpPrfLngPthIdx : 13|6@0+ (1,0) [0|63] ""  EOCM2B_IMX6_FO,EOCM2B_K2_FO,EOCM2B_K1_FO,EOCM2A_IMX6_FO,EOCM2A_K2_FO,EOCM2A_K1_FO
 SG_ AdvDrAstMpPrfLngMsgTp : 23|3@0+ (1,0) [0|7] ""  EOCM2B_IMX6_FO,EOCM2B_K2_FO,EOCM2B_K1_FO,EOCM2A_IMX6_FO,EOCM2A_K2_FO,EOCM2A_K1_FO
 SG_ AdvDrAstMpPrfLngOfst : 20|13@0+ (1,0) [0|8191] "m"  EOCM2B_IMX6_FO,EOCM2B_K2_FO,EOCM2B_K1_FO,EOCM2A_IMX6_FO,EOCM2A_K2_FO,EOCM2A_K1_FO
 SG_ AdvDrAstMpPrfLngVal : 39|32@0+ (1,0) [0|4294967295] ""  EOCM2B_IMX6_FO,EOCM2B_K2_FO,EOCM2B_K1_FO,EOCM2A_IMX6_FO,EOCM2A_K2_FO,EOCM2A_K1_FO

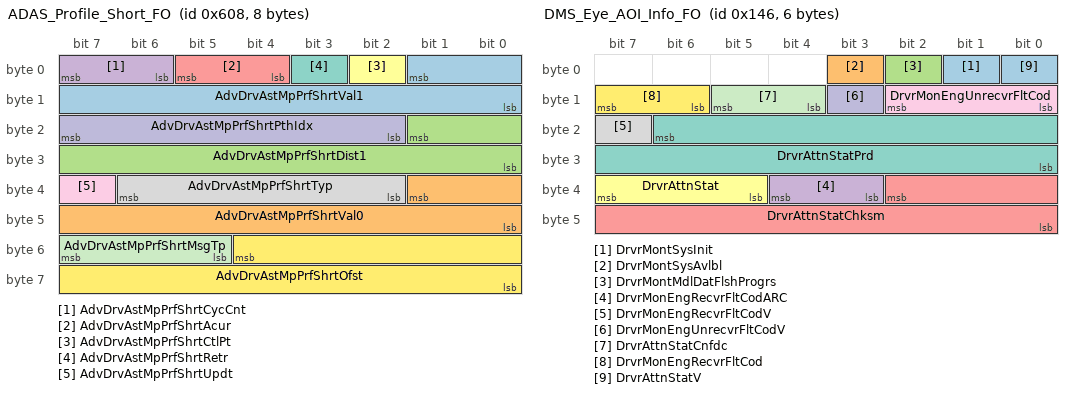
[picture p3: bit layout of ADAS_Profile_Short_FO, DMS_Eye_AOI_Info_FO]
BO_ 1544 ADAS_Profile_Short_FO: 8 AMM_FO
 SG_ AdvDrvAstMpPrfShrtVal1 : 1|10@0+ (1,0) [0|1023] ""  EOCM2B_IMX6_FO,EOCM2B_K2_FO,EOCM2B_K1_FO,EOCM2A_IMX6_FO,EOCM2A_K2_FO,EOCM2A_K1_FO
 SG_ AdvDrvAstMpPrfShrtVal0 : 33|10@0+ (1,0) [0|1023] ""  EOCM2B_IMX6_FO,EOCM2B_K2_FO,EOCM2B_K1_FO,EOCM2A_IMX6_FO,EOCM2A_K2_FO,EOCM2A_K1_FO
 SG_ AdvDrvAstMpPrfShrtDist1 : 17|10@0+ (1,0) [0|1023] "m"  EOCM2B_IMX6_FO,EOCM2B_K2_FO,EOCM2B_K1_FO,EOCM2A_IMX6_FO,EOCM2A_K2_FO,EOCM2A_K1_FO
 SG_ AdvDrvAstMpPrfShrtCycCnt : 7|2@0+ (1,0) [0|3] ""  EOCM2B_IMX6_FO,EOCM2B_K2_FO,EOCM2B_K1_FO,EOCM2A_IMX6_FO,EOCM2A_K2_FO,EOCM2A_K1_FO
 SG_ AdvDrvAstMpPrfShrtAcur : 5|2@0+ (1,0) [0|3] ""  EOCM2B_IMX6_FO,EOCM2B_K2_FO,EOCM2B_K1_FO,EOCM2A_IMX6_FO,EOCM2A_K2_FO,EOCM2A_K1_FO
 SG_ AdvDrvAstMpPrfShrtCtlPt : 2|1@0+ (1,0) [0|1] ""  EOCM2B_IMX6_FO,EOCM2B_K2_FO,EOCM2B_K1_FO,EOCM2A_IMX6_FO,EOCM2A_K2_FO,EOCM2A_K1_FO
 SG_ AdvDrvAstMpPrfShrtRetr : 3|1@0+ (1,0) [0|1] ""  EOCM2B_IMX6_FO,EOCM2B_K2_FO,EOCM2B_K1_FO,EOCM2A_IMX6_FO,EOCM2A_K2_FO,EOCM2A_K1_FO
 SG_ AdvDrvAstMpPrfShrtTyp : 38|5@0+ (1,0) [0|31] ""  EOCM2B_IMX6_FO,EOCM2B_K2_FO,EOCM2B_K1_FO,EOCM2A_IMX6_FO,EOCM2A_K2_FO,EOCM2A_K1_FO
 SG_ AdvDrvAstMpPrfShrtUpdt : 39|1@0+ (1,0) [0|1] ""  EOCM2B_IMX6_FO,EOCM2B_K2_FO,EOCM2B_K1_FO,EOCM2A_IMX6_FO,EOCM2A_K2_FO,EOCM2A_K1_FO
 SG_ AdvDrvAstMpPrfShrtPthIdx : 23|6@0+ (1,0) [0|63] ""  EOCM2B_IMX6_FO,EOCM2B_K2_FO,EOCM2B_K1_FO,EOCM2A_IMX6_FO,EOCM2A_K2_FO,EOCM2A_K1_FO
 SG_ AdvDrvAstMpPrfShrtMsgTp : 55|3@0+ (1,0) [0|7] ""  EOCM2B_IMX6_FO,EOCM2B_K2_FO,EOCM2B_K1_FO,EOCM2A_IMX6_FO,EOCM2A_K2_FO,EOCM2A_K1_FO
 SG_ AdvDrvAstMpPrfShrtOfst : 52|13@0+ (1,0) [0|8191] "m"  EOCM2B_IMX6_FO,EOCM2B_K2_FO,EOCM2B_K1_FO,EOCM2A_IMX6_FO,EOCM2A_K2_FO,EOCM2A_K1_FO

BO_ 1542 ADAS_Stub_FO: 8 AMM_FO
 SG_ AdvDrAstMpStbSubPthIdx : 63|6@0+ (1,0) [0|63] ""  EOCM2B_IMX6_FO,EOCM2B_K2_FO,EOCM2B_K1_FO,EOCM2A_IMX6_FO,EOCM2A_K2_FO,EOCM2A_K1_FO
 SG_ AdvDrAstMpStbUpdt : 55|1@0+ (1,0) [0|1] ""  EOCM2B_IMX6_FO,EOCM2B_K2_FO,EOCM2B_K1_FO,EOCM2A_IMX6_FO,EOCM2A_K2_FO,EOCM2A_K1_FO
 SG_ AdvDrAstMpStbPrtCalRut : 57|2@0+ (1,0) [0|3] ""  EOCM2B_IMX6_FO,EOCM2B_K2_FO,EOCM2B_K1_FO,EOCM2A_IMX6_FO,EOCM2A_K2_FO,EOCM2A_K1_FO
 SG_ AdvDrAstMpStbNmLnDrvDir : 54|3@0+ (1,0) [0|7] ""  EOCM2B_IMX6_FO,EOCM2B_K2_FO,EOCM2B_K1_FO,EOCM2A_IMX6_FO,EOCM2A_K2_FO,EOCM2A_K1_FO
 SG_ AdvDrAstMpStbCycCnt : 51|2@0+ (1,0) [0|3] ""  EOCM2B_IMX6_FO,EOCM2B_K2_FO,EOCM2B_K1_FO,EOCM2A_IMX6_FO,EOCM2A_K2_FO,EOCM2A_K1_FO
 SG_ AdvDrAstMpStbCmplxInsct : 49|2@0+ (1,0) [0|3] ""  EOCM2B_IMX6_FO,EOCM2B_K2_FO,EOCM2B_K1_FO,EOCM2A_IMX6_FO,EOCM2A_K2_FO,EOCM2A_K1_FO
 SG_ AdvDrAstMpStbTrnAngl : 47|8@0+ (1.417,0) [0|361.335] "deg"  EOCM2B_IMX6_FO,EOCM2B_K2_FO,EOCM2B_K1_FO,EOCM2A_IMX6_FO,EOCM2A_K2_FO,EOCM2A_K1_FO
 SG_ AdvDrAstMpStbRtOfWay : 38|2@0+ (1,0) [0|3] ""  EOCM2B_IMX6_FO,EOCM2B_K2_FO,EOCM2B_K1_FO,EOCM2A_IMX6_FO,EOCM2A_K2_FO,EOCM2A_K1_FO
 SG_ AdvDrAstMpStbRelProb : 36|5@0+ (3.333,0) [0|103.323] "%"  EOCM2B_IMX6_FO,EOCM2B_K2_FO,EOCM2B_K1_FO,EOCM2A_IMX6_FO,EOCM2A_K2_FO,EOCM2A_K1_FO
 SG_ AdvDrAstMpStbRetr : 39|1@0+ (1,0) [0|1] ""  EOCM2B_IMX6_FO,EOCM2B_K2_FO,EOCM2B_K1_FO,EOCM2A_IMX6_FO,EOCM2A_K2_FO,EOCM2A_K1_FO
 SG_ AdvDrAstMpStbNmLnOppDir : 31|2@0+ (1,0) [0|3] ""  EOCM2B_IMX6_FO,EOCM2B_K2_FO,EOCM2B_K1_FO,EOCM2A_IMX6_FO,EOCM2A_K2_FO,EOCM2A_K1_FO
 SG_ AdvDrAstMpStbPathIdx : 29|6@0+ (1,0) [0|63] ""  EOCM2B_IMX6_FO,EOCM2B_K2_FO,EOCM2B_K1_FO,EOCM2A_IMX6_FO,EOCM2A_K2_FO,EOCM2A_K1_FO
 SG_ AdvDrAstMpStbLstStbOfst : 23|1@0+ (1,0) [0|1] ""  EOCM2B_IMX6_FO,EOCM2B_K2_FO,EOCM2B_K1_FO,EOCM2A_IMX6_FO,EOCM2A_K2_FO,EOCM2A_K1_FO
 SG_ AdvDrAstMpStbMsgTyp : 22|3@0+ (1,0) [0|7] ""  EOCM2B_IMX6_FO,EOCM2B_K2_FO,EOCM2B_K1_FO,EOCM2A_IMX6_FO,EOCM2A_K2_FO,EOCM2A_K1_FO
 SG_ AdvDrAstMpStbFmOfWay : 19|4@0+ (1,0) [0|15] ""  EOCM2B_IMX6_FO,EOCM2B_K2_FO,EOCM2B_K1_FO,EOCM2A_IMX6_FO,EOCM2A_K2_FO,EOCM2A_K1_FO
 SG_ AdvDrAstMpStbFuncRdCls : 7|3@0+ (1,0) [0|7] ""  EOCM2B_IMX6_FO,EOCM2B_K2_FO,EOCM2B_K1_FO,EOCM2A_IMX6_FO,EOCM2A_K2_FO,EOCM2A_K1_FO
 SG_ AdvDrAstMpStbOfst : 4|13@0+ (1,0) [0|8191] "m"  EOCM2B_IMX6_FO,EOCM2B_K2_FO,EOCM2B_K1_FO,EOCM2A_IMX6_FO,EOCM2A_K2_FO,EOCM2A_K1_FO

BO_ 1541 ADAS_Segment_FO: 8 AMM_FO
 SG_ AdvDrAstMpSegRelProb : 12|5@0+ (3.333,0) [0|103.323] "%"  EOCM2B_IMX6_FO,EOCM2B_K2_FO,EOCM2B_K1_FO,EOCM2A_IMX6_FO,EOCM2A_K2_FO,EOCM2A_K1_FO
 SG_ AdvDrAstMpSegUpdt : 0|1@0+ (1,0) [0|1] ""  EOCM2B_IMX6_FO,EOCM2B_K2_FO,EOCM2B_K1_FO,EOCM2A_IMX6_FO,EOCM2A_K2_FO,EOCM2A_K1_FO
 SG_ AdvDrAstMpSegTunl : 25|2@0+ (1,0) [0|3] ""  EOCM2B_IMX6_FO,EOCM2B_K2_FO,EOCM2B_K1_FO,EOCM2A_IMX6_FO,EOCM2A_K2_FO,EOCM2A_K1_FO
 SG_ AdvDrAstMpSegCycCnt : 39|2@0+ (1,0) [0|3] ""  EOCM2B_IMX6_FO,EOCM2B_K2_FO,EOCM2B_K1_FO,EOCM2A_IMX6_FO,EOCM2A_K2_FO,EOCM2A_K1_FO
 SG_ AdvDrAstMpSegCmplxInsct : 37|2@0+ (1,0) [0|3] ""  EOCM2B_IMX6_FO,EOCM2B_K2_FO,EOCM2B_K1_FO,EOCM2A_IMX6_FO,EOCM2A_K2_FO,EOCM2A_K1_FO
 SG_ AdvDrAstMpSegBldUpAra : 43|2@0+ (1,0) [0|3] ""  EOCM2B_IMX6_FO,EOCM2B_K2_FO,EOCM2B_K1_FO,EOCM2A_IMX6_FO,EOCM2A_K2_FO,EOCM2A_K1_FO
 SG_ AdvDrAstMpSegBrdg : 41|2@0+ (1,0) [0|3] ""  EOCM2B_IMX6_FO,EOCM2B_K2_FO,EOCM2B_K1_FO,EOCM2A_IMX6_FO,EOCM2A_K2_FO,EOCM2A_K1_FO
 SG_ AdvDrAstMpSegRTrns : 1|1@0+ (1,0) [0|1] ""  EOCM2B_IMX6_FO,EOCM2B_K2_FO,EOCM2B_K1_FO,EOCM2A_IMX6_FO,EOCM2A_K2_FO,EOCM2A_K1_FO
 SG_ AdvDrAstMpSegDivdRd : 31|2@0+ (1,0) [0|3] ""  EOCM2B_IMX6_FO,EOCM2B_K2_FO,EOCM2B_K1_FO,EOCM2A_IMX6_FO,EOCM2A_K2_FO,EOCM2A_K1_FO
 SG_ AdvDrAstMpSegPthIdx : 7|6@0+ (1,0) [0|63] ""  EOCM2B_IMX6_FO,EOCM2B_K2_FO,EOCM2B_K1_FO,EOCM2A_IMX6_FO,EOCM2A_K2_FO,EOCM2A_K1_FO
 SG_ AdvDrAstMpSegPrtCalRut : 27|2@0+ (1,0) [0|3] ""  EOCM2B_IMX6_FO,EOCM2B_K2_FO,EOCM2B_K1_FO,EOCM2A_IMX6_FO,EOCM2A_K2_FO,EOCM2A_K1_FO
 SG_ AdvDrAstMpSegNmLnOppDir : 29|2@0+ (1,0) [0|3] ""  EOCM2B_IMX6_FO,EOCM2B_K2_FO,EOCM2B_K1_FO,EOCM2A_IMX6_FO,EOCM2A_K2_FO,EOCM2A_K1_FO
 SG_ AdvDrAstMpSegNmLnDrvDir : 55|3@0+ (1,0) [0|7] ""  EOCM2B_IMX6_FO,EOCM2B_K2_FO,EOCM2B_K1_FO,EOCM2A_IMX6_FO,EOCM2A_K2_FO,EOCM2A_K1_FO
 SG_ AdvDrAstMpSegMsgTyp : 46|3@0+ (1,0) [0|7] ""  EOCM2B_IMX6_FO,EOCM2B_K2_FO,EOCM2B_K1_FO,EOCM2A_IMX6_FO,EOCM2A_K2_FO,EOCM2A_K1_FO
 SG_ AdvDrAstMpSegFunRdCls : 23|3@0+ (1,0) [0|7] ""  EOCM2B_IMX6_FO,EOCM2B_K2_FO,EOCM2B_K1_FO,EOCM2A_IMX6_FO,EOCM2A_K2_FO,EOCM2A_K1_FO
 SG_ AdvDrAstMpSegFrmOfWay : 35|4@0+ (1,0) [0|15] ""  EOCM2B_IMX6_FO,EOCM2B_K2_FO,EOCM2B_K1_FO,EOCM2A_IMX6_FO,EOCM2A_K2_FO,EOCM2A_K1_FO
 SG_ AdvDrAstMpSegEffSpdLmt : 20|5@0+ (1,0) [0|31] ""  EOCM2B_IMX6_FO,EOCM2B_K2_FO,EOCM2B_K1_FO,EOCM2A_IMX6_FO,EOCM2A_K2_FO,EOCM2A_K1_FO
 SG_ AdvDrAstMpSegEffSdLmtTp : 15|3@0+ (1,0) [0|7] ""  EOCM2B_IMX6_FO,EOCM2B_K2_FO,EOCM2B_K1_FO,EOCM2A_IMX6_FO,EOCM2A_K2_FO,EOCM2A_K1_FO
 SG_ AdvDrAstMpSegOffset : 52|13@0+ (1,0) [0|8191] "m"  EOCM2B_IMX6_FO,EOCM2B_K2_FO,EOCM2B_K1_FO,EOCM2A_IMX6_FO,EOCM2A_K2_FO,EOCM2A_K1_FO

BO_ 608 PPS_ElevHdSpd_FO: 8 EOCM2A_K1_FO
 SG_ PPSVel : 31|8@0+ (1,0) [0|255] "km / h"  EOCM2B_IMX6_FO,EOCM2B_K2_FO,EOCM2B_K1_FO,AMM_FO
 SG_ PPSVelV : 3|1@0+ (1,0) [0|1] ""  EOCM2B_IMX6_FO,EOCM2B_K2_FO,EOCM2B_K1_FO,AMM_FO
 SG_ PPSElvHedngSpdBrstID : 5|2@0+ (1,0) [0|3] ""  EOCM2B_IMX6_FO,EOCM2B_K2_FO,EOCM2B_K1_FO,AMM_FO
 SG_ PPSElvHdengSpdChksm : 50|11@0+ (1,0) [0|2047] ""  EOCM2B_IMX6_FO,EOCM2B_K2_FO,EOCM2B_K1_FO,AMM_FO
 SG_ PPSHedngV : 6|1@0+ (1,0) [0|1] ""  EOCM2B_IMX6_FO,EOCM2B_K2_FO,EOCM2B_K1_FO,AMM_FO
 SG_ PPSHedng : 2|19@0+ (0.001,0) [0|524.287] "deg"  EOCM2B_IMX6_FO,EOCM2B_K2_FO,EOCM2B_K1_FO,AMM_FO
 SG_ PPSElvtnV : 7|1@0+ (1,0) [0|1] ""  EOCM2B_IMX6_FO,EOCM2B_K2_FO,EOCM2B_K1_FO,AMM_FO
 SG_ PPSElvtn : 39|21@0+ (1,-100000) [-100000|1997151] "cm"  EOCM2B_IMX6_FO,EOCM2B_K2_FO,EOCM2B_K1_FO,AMM_FO

BO_ 1168 WiFi_Station_AMM_FO: 5 AMM_FO
 SG_ WSMR_WiFiStnMpMACAddr : 15|32@0+ (1,0) [0|4294967295] ""  EOCM2B_K1_FO,EOCM2A_K1_FO
 SG_ WSMR_WiFiAssnReq : 1|2@0+ (1,0) [0|3] ""  EOCM2B_K1_FO,EOCM2A_K1_FO

BO_ 1161 WiFi_AP_Data_AMM_FO: 2 EOCM2A_K1_FO
 SG_ WAPDM_SecurityType : 15|4@0+ (1,0) [0|15] ""  EOCM2B_K1_FO,AMM_FO
 SG_ WAPDM_WiFiEnStat : 0|1@0+ (1,0) [0|1] ""  EOCM2B_K1_FO,AMM_FO
 SG_ WAPDM_EncrptnType : 11|4@0+ (1,0) [0|15] ""  EOCM2B_K1_FO,AMM_FO

BO_ 1157 SSID_AMM_3_FO: 8 EOCM2A_K1_FO
 SG_ WiFiSSIDDgts17to24_Mp : 7|64@0+ (1,0) [0|0] ""  EOCM2B_K1_FO,AMM_FO

BO_ 326 DMS_Eye_AOI_Info_FO: 6 DMS_FO
 SG_ DrvrMontSysInit : 1|1@0+ (1,0) [0|1] ""  EOCM2B_IMX6_FO,EOCM2B_K2_FO,EOCM2B_K1_FO,EOCM2A_IMX6_FO,EOCM2A_K2_FO,EOCM2A_K1_FO
 SG_ DrvrMontSysAvlbl : 3|1@0+ (1,0) [0|1] ""  EOCM2B_IMX6_FO,EOCM2B_K2_FO,EOCM2B_K1_FO,EOCM2A_IMX6_FO,EOCM2A_K2_FO,EOCM2A_K1_FO
 SG_ DrvrMontMdlDatFlshProgrs : 2|1@0+ (1,0) [0|1] ""  EOCM2B_IMX6_FO,EOCM2B_K2_FO,EOCM2B_K1_FO,EOCM2A_IMX6_FO,EOCM2A_K2_FO,EOCM2A_K1_FO
 SG_ DrvrMonEngRecvrFltCodARC : 36|2@0+ (1,0) [0|3] ""  EOCM2B_IMX6_FO,EOCM2B_K2_FO,EOCM2B_K1_FO,EOCM2A_IMX6_FO,EOCM2A_K2_FO,EOCM2A_K1_FO
 SG_ DrvrAttnStatChksm : 34|11@0+ (1,0) [0|2047] ""  EOCM2B_IMX6_FO,EOCM2B_K2_FO,EOCM2B_K1_FO,EOCM2A_IMX6_FO,EOCM2A_K2_FO,EOCM2A_K1_FO
 SG_ DrvrAttnStat : 39|3@0+ (1,0) [0|7] ""  EOCM2B_IMX6_FO,EOCM2B_K2_FO,EOCM2B_K1_FO,EOCM2A_IMX6_FO,EOCM2A_K2_FO,EOCM2A_K1_FO
 SG_ DrvrAttnStatPrd : 22|15@0+ (0.025,0) [0|819.175] ""  EOCM2B_IMX6_FO,EOCM2B_K2_FO,EOCM2B_K1_FO,EOCM2A_IMX6_FO,EOCM2A_K2_FO,EOCM2A_K1_FO
 SG_ DrvrMonEngRecvrFltCodV : 23|1@0+ (1,0) [0|1] ""  EOCM2B_IMX6_FO,EOCM2B_K2_FO,EOCM2B_K1_FO,EOCM2A_IMX6_FO,EOCM2A_K2_FO,EOCM2A_K1_FO
 SG_ DrvrMonEngUnrecvrFltCod : 10|3@0+ (1,0) [0|7] ""  EOCM2B_IMX6_FO,EOCM2B_K2_FO,EOCM2B_K1_FO,EOCM2A_IMX6_FO,EOCM2A_K2_FO,EOCM2A_K1_FO
 SG_ DrvrMonEngUnrecvrFltCodV : 11|1@0+ (1,0) [0|1] ""  EOCM2B_IMX6_FO,EOCM2B_K2_FO,EOCM2B_K1_FO,EOCM2A_IMX6_FO,EOCM2A_K2_FO,EOCM2A_K1_FO
 SG_ DrvrAttnStatCnfdc : 13|2@0+ (1,0) [0|3] ""  EOCM2B_IMX6_FO,EOCM2B_K2_FO,EOCM2B_K1_FO,EOCM2A_IMX6_FO,EOCM2A_K2_FO,EOCM2A_K1_FO
 SG_ DrvrMonEngRecvrFltCod : 15|2@0+ (1,0) [0|3] ""  EOCM2B_IMX6_FO,EOCM2B_K2_FO,EOCM2B_K1_FO,EOCM2A_IMX6_FO,EOCM2A_K2_FO,EOCM2A_K1_FO
 SG_ DrvrAttnStatV : 0|1@0+ (1,0) [0|1] ""  EOCM2B_IMX6_FO,EOCM2B_K2_FO,EOCM2B_K1_FO,EOCM2A_IMX6_FO,EOCM2A_K2_FO,EOCM2A_K1_FO

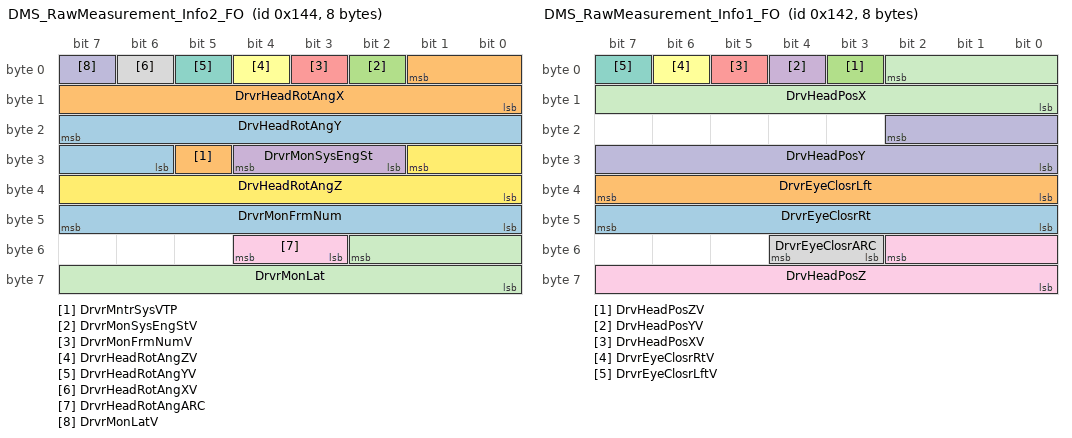
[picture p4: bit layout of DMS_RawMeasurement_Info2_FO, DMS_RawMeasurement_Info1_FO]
BO_ 324 DMS_RawMeasurement_Info2_FO: 8 DMS_FO
 SG_ DrvrMonFrmNum : 47|8@0+ (1,0) [0|255] ""  EOCM2B_IMX6_FO,EOCM2B_K2_FO,EOCM2B_K1_FO,EOCM2A_IMX6_FO,EOCM2A_K2_FO,EOCM2A_K1_FO
 SG_ DrvrMntrSysVTP : 29|1@0+ (1,0) [0|1] ""  EOCM2B_IMX6_FO,EOCM2B_K2_FO,EOCM2B_K1_FO,EOCM2A_IMX6_FO,EOCM2A_K2_FO,EOCM2A_K1_FO
 SG_ DrvrMonSysEngStV : 2|1@0+ (1,0) [0|1] ""  EOCM2B_IMX6_FO,EOCM2B_K2_FO,EOCM2B_K1_FO,EOCM2A_IMX6_FO,EOCM2A_K2_FO,EOCM2A_K1_FO
 SG_ DrvrMonSysEngSt : 28|3@0+ (1,0) [0|7] ""  EOCM2B_IMX6_FO,EOCM2B_K2_FO,EOCM2B_K1_FO,EOCM2A_IMX6_FO,EOCM2A_K2_FO,EOCM2A_K1_FO
 SG_ DrvrMonFrmNumV : 3|1@0+ (1,0) [0|1] ""  EOCM2B_IMX6_FO,EOCM2B_K2_FO,EOCM2B_K1_FO,EOCM2A_IMX6_FO,EOCM2A_K2_FO,EOCM2A_K1_FO
 SG_ DrvrHeadRotAngZV : 4|1@0+ (1,0) [0|1] ""  EOCM2B_IMX6_FO,EOCM2B_K2_FO,EOCM2B_K1_FO,EOCM2A_IMX6_FO,EOCM2A_K2_FO,EOCM2A_K1_FO
 SG_ DrvrHeadRotAngYV : 5|1@0+ (1,0) [0|1] ""  EOCM2B_IMX6_FO,EOCM2B_K2_FO,EOCM2B_K1_FO,EOCM2A_IMX6_FO,EOCM2A_K2_FO,EOCM2A_K1_FO
 SG_ DrvrHeadRotAngXV : 6|1@0+ (1,0) [0|1] ""  EOCM2B_IMX6_FO,EOCM2B_K2_FO,EOCM2B_K1_FO,EOCM2A_IMX6_FO,EOCM2A_K2_FO,EOCM2A_K1_FO
 SG_ DrvrHeadRotAngARC : 52|2@0+ (1,0) [0|3] ""  EOCM2B_IMX6_FO,EOCM2B_K2_FO,EOCM2B_K1_FO,EOCM2A_IMX6_FO,EOCM2A_K2_FO,EOCM2A_K1_FO
 SG_ DrvrMonLatV : 7|1@0+ (1,0) [0|1] ""  EOCM2B_IMX6_FO,EOCM2B_K2_FO,EOCM2B_K1_FO,EOCM2A_IMX6_FO,EOCM2A_K2_FO,EOCM2A_K1_FO
 SG_ DrvrMonLat : 50|11@0+ (0.001,0) [0|2.047] ""  EOCM2B_IMX6_FO,EOCM2B_K2_FO,EOCM2B_K1_FO,EOCM2A_IMX6_FO,EOCM2A_K2_FO,EOCM2A_K1_FO
 SG_ DrvHeadRotAngZ : 25|10@0- (0.00625,0) [-3.2|3.19375] "rad"  EOCM2A_IMX6_FO,EOCM2A_K2_FO,EOCM2A_K1_FO,EOCM2B_IMX6_FO,EOCM2B_K2_FO,EOCM2B_K1_FO
 SG_ DrvHeadRotAngY : 23|10@0- (0.00625,0) [-3.2|3.19375] "rad"  EOCM2A_IMX6_FO,EOCM2A_K2_FO,EOCM2A_K1_FO,EOCM2B_IMX6_FO,EOCM2B_K2_FO,EOCM2B_K1_FO
 SG_ DrvrHeadRotAngX : 1|10@0- (0.00625,0) [-3.2|3.19375] "rad"  EOCM2A_IMX6_FO,EOCM2A_K2_FO,EOCM2A_K1_FO,EOCM2B_IMX6_FO,EOCM2B_K2_FO,EOCM2B_K1_FO

BO_ 322 DMS_RawMeasurement_Info1_FO: 8 DMS_FO
 SG_ DrvrEyeClosrRt : 47|8@0+ (0.005,0) [0|1.275] ""  EOCM2B_IMX6_FO,EOCM2B_K2_FO,EOCM2B_K1_FO,EOCM2A_IMX6_FO,EOCM2A_K2_FO,EOCM2A_K1_FO
 SG_ DrvrEyeClosrLft : 39|8@0+ (0.005,0) [0|1.275] ""  EOCM2B_IMX6_FO,EOCM2B_K2_FO,EOCM2B_K1_FO,EOCM2A_IMX6_FO,EOCM2A_K2_FO,EOCM2A_K1_FO
 SG_ DrvHeadPosZV : 3|1@0+ (1,0) [0|1] ""  EOCM2B_IMX6_FO,EOCM2B_K2_FO,EOCM2B_K1_FO,EOCM2A_IMX6_FO,EOCM2A_K2_FO,EOCM2A_K1_FO
 SG_ DrvHeadPosYV : 4|1@0+ (1,0) [0|1] ""  EOCM2B_IMX6_FO,EOCM2B_K2_FO,EOCM2B_K1_FO,EOCM2A_IMX6_FO,EOCM2A_K2_FO,EOCM2A_K1_FO
 SG_ DrvHeadPosXV : 5|1@0+ (1,0) [0|1] ""  EOCM2B_IMX6_FO,EOCM2B_K2_FO,EOCM2B_K1_FO,EOCM2A_IMX6_FO,EOCM2A_K2_FO,EOCM2A_K1_FO
 SG_ DrvrEyeClosrRtV : 6|1@0+ (1,0) [0|1] ""  EOCM2B_IMX6_FO,EOCM2B_K2_FO,EOCM2B_K1_FO,EOCM2A_IMX6_FO,EOCM2A_K2_FO,EOCM2A_K1_FO
 SG_ DrvrEyeClosrLftV : 7|1@0+ (1,0) [0|1] ""  EOCM2B_IMX6_FO,EOCM2B_K2_FO,EOCM2B_K1_FO,EOCM2A_IMX6_FO,EOCM2A_K2_FO,EOCM2A_K1_FO
 SG_ DrvrEyeClosrARC : 52|2@0+ (1,0) [0|3] ""  EOCM2B_IMX6_FO,EOCM2B_K2_FO,EOCM2B_K1_FO,EOCM2A_IMX6_FO,EOCM2A_K2_FO,EOCM2A_K1_FO
 SG_ DrvHeadPosZ : 50|11@0- (0.005,0) [-5.12|5.115] "m"  EOCM2A_IMX6_FO,EOCM2A_K2_FO,EOCM2A_K1_FO,EOCM2B_IMX6_FO,EOCM2B_K2_FO,EOCM2B_K1_FO
 SG_ DrvHeadPosY : 18|11@0- (0.005,0) [-5.12|5.115] "m"  EOCM2A_IMX6_FO,EOCM2A_K2_FO,EOCM2A_K1_FO,EOCM2B_IMX6_FO,EOCM2B_K2_FO,EOCM2B_K1_FO
 SG_ DrvHeadPosX : 2|11@0- (0.005,0) [-5.12|5.115] "m"  EOCM2A_IMX6_FO,EOCM2A_K2_FO,EOCM2A_K1_FO,EOCM2B_IMX6_FO,EOCM2B_K2_FO,EOCM2B_K1_FO

BO_ 320 Inertial2_Rates_FO: 8 _DOFIMU2_FO
 SG_ MstrTgrSyncInrtl2Rte : 55|5@0+ (1,0) [0|31] ""  EOCM2A_IMX6_FO,EOCM2A_K2_FO,EOCM2A_K1_FO,EOCM2B_IMX6_FO,EOCM2B_K2_FO,EOCM2B_K1_FO
 SG_ Inertial2YawRteV : 5|1@0+ (1,0) [0|1] ""  EOCM2A_IMX6_FO,EOCM2A_K2_FO,EOCM2A_K1_FO,EOCM2B_IMX6_FO,EOCM2B_K2_FO,EOCM2B_K1_FO
 SG_ Inertial2YawRte : 36|13@0- (0.024,0) [-98.304|98.28] "deg/s"  EOCM2A_IMX6_FO,EOCM2A_K2_FO,EOCM2A_K1_FO,EOCM2B_IMX6_FO,EOCM2B_K2_FO,EOCM2B_K1_FO
 SG_ Inertial2RollRteV : 6|1@0+ (1,0) [0|1] ""  EOCM2A_IMX6_FO,EOCM2A_K2_FO,EOCM2A_K1_FO,EOCM2B_IMX6_FO,EOCM2B_K2_FO,EOCM2B_K1_FO
 SG_ Inertial2RollRte : 20|13@0- (0.024,0) [-98.304|98.28] "deg/s"  EOCM2A_IMX6_FO,EOCM2A_K2_FO,EOCM2A_K1_FO,EOCM2B_IMX6_FO,EOCM2B_K2_FO,EOCM2B_K1_FO
 SG_ Inertial2RteChksum : 50|11@0+ (1,0) [0|2047] ""  EOCM2A_IMX6_FO,EOCM2A_K2_FO,EOCM2A_K1_FO,EOCM2B_IMX6_FO,EOCM2B_K2_FO,EOCM2B_K1_FO
 SG_ Inertial2PitchRteV : 7|1@0+ (1,0) [0|1] ""  EOCM2A_IMX6_FO,EOCM2A_K2_FO,EOCM2A_K1_FO,EOCM2B_IMX6_FO,EOCM2B_K2_FO,EOCM2B_K1_FO
 SG_ Inertial2PitchRte : 4|13@0- (0.024,0) [-98.304|98.28] "deg/s"  EOCM2A_IMX6_FO,EOCM2A_K2_FO,EOCM2A_K1_FO,EOCM2B_IMX6_FO,EOCM2B_K2_FO,EOCM2B_K1_FO

BO_ 308 Inertial1_Rates_FO: 8 _DOFIMU1_FO
 SG_ MstrTrgrSyncInrtl1Rte : 55|5@0+ (1,0) [0|31] ""  EOCM2A_IMX6_FO,EOCM2A_K2_FO,EOCM2A_K1_FO,EOCM2B_IMX6_FO,EOCM2B_K2_FO,EOCM2B_K1_FO
 SG_ Inertial1YawRteV : 5|1@0+ (1,0) [0|1] ""  EOCM2A_IMX6_FO,EOCM2A_K2_FO,EOCM2A_K1_FO,EOCM2B_IMX6_FO,EOCM2B_K2_FO,EOCM2B_K1_FO
 SG_ Inertial1YawRte : 36|13@0- (0.024,0) [-98.304|98.28] "deg/s"  EOCM2A_IMX6_FO,EOCM2A_K2_FO,EOCM2A_K1_FO,EOCM2B_IMX6_FO,EOCM2B_K2_FO,EOCM2B_K1_FO
 SG_ Inertial1RollRteV : 6|1@0+ (1,0) [0|1] ""  EOCM2A_IMX6_FO,EOCM2A_K2_FO,EOCM2A_K1_FO,EOCM2B_IMX6_FO,EOCM2B_K2_FO,EOCM2B_K1_FO
 SG_ Inertial1RollRte : 20|13@0- (0.024,0) [-98.304|98.28] "deg/s"  EOCM2A_IMX6_FO,EOCM2A_K2_FO,EOCM2A_K1_FO,EOCM2B_IMX6_FO,EOCM2B_K2_FO,EOCM2B_K1_FO
 SG_ Inertial1RteChksum : 50|11@0+ (1,0) [0|2047] ""  EOCM2A_IMX6_FO,EOCM2A_K2_FO,EOCM2A_K1_FO,EOCM2B_IMX6_FO,EOCM2B_K2_FO,EOCM2B_K1_FO
 SG_ Inertial1PitchRteV : 7|1@0+ (1,0) [0|1] ""  EOCM2A_IMX6_FO,EOCM2A_K2_FO,EOCM2A_K1_FO,EOCM2B_IMX6_FO,EOCM2B_K2_FO,EOCM2B_K1_FO
 SG_ Inertial1PitchRte : 4|13@0- (0.024,0) [-98.304|98.28] "deg/s"  EOCM2A_IMX6_FO,EOCM2A_K2_FO,EOCM2A_K1_FO,EOCM2B_IMX6_FO,EOCM2B_K2_FO,EOCM2B_K1_FO

BO_ 312 Inertial2_Accel2_FO: 8 _DOFIMU2_FO
 SG_ MstrTrigSyncInrtl22 : 55|5@0+ (1,0) [0|31] ""  EOCM2A_IMX6_FO,EOCM2A_K2_FO,EOCM2A_K1_FO,EOCM2B_IMX6_FO,EOCM2B_K2_FO,EOCM2B_K1_FO
 SG_ InrtlSns2AccFrm2Chksm : 50|11@0+ (1,0) [0|2047] ""  EOCM2A_IMX6_FO,EOCM2A_K2_FO,EOCM2A_K1_FO,EOCM2B_IMX6_FO,EOCM2B_K2_FO,EOCM2B_K1_FO
 SG_ InrtlSnsr2YawAccV : 5|1@0+ (1,0) [0|1] ""  EOCM2A_IMX6_FO,EOCM2A_K2_FO,EOCM2A_K1_FO,EOCM2B_IMX6_FO,EOCM2B_K2_FO,EOCM2B_K1_FO
 SG_ InrtlSnsr2YawAcc : 36|13@0- (0.024,0) [-98.304|98.28] "deg/s^2"  EOCM2A_IMX6_FO,EOCM2A_K2_FO,EOCM2A_K1_FO,EOCM2B_IMX6_FO,EOCM2B_K2_FO,EOCM2B_K1_FO
 SG_ InrtlSnsr2RollAccV : 6|1@0+ (1,0) [0|1] ""  EOCM2A_IMX6_FO,EOCM2A_K2_FO,EOCM2A_K1_FO,EOCM2B_IMX6_FO,EOCM2B_K2_FO,EOCM2B_K1_FO
 SG_ InrtlSnsr2RollAcc : 20|13@0- (0.024,0) [-98.304|98.28] "deg/s^2"  EOCM2A_IMX6_FO,EOCM2A_K2_FO,EOCM2A_K1_FO,EOCM2B_IMX6_FO,EOCM2B_K2_FO,EOCM2B_K1_FO
 SG_ InrtlSnsr2PtchAccV : 7|1@0+ (1,0) [0|1] ""  EOCM2A_IMX6_FO,EOCM2A_K2_FO,EOCM2A_K1_FO,EOCM2B_IMX6_FO,EOCM2B_K2_FO,EOCM2B_K1_FO
 SG_ InrtlSnsr2PtchAcc : 4|13@0- (0.024,0) [-98.304|98.28] "deg/s^2"  EOCM2A_IMX6_FO,EOCM2A_K2_FO,EOCM2A_K1_FO,EOCM2B_IMX6_FO,EOCM2B_K2_FO,EOCM2B_K1_FO

BO_ 306 Inertial1_Accel2_FO: 8 _DOFIMU1_FO
 SG_ MstrTrigSyncInrtl12 : 55|5@0+ (1,0) [0|31] ""  EOCM2A_IMX6_FO,EOCM2A_K2_FO,EOCM2A_K1_FO,EOCM2B_IMX6_FO,EOCM2B_K2_FO,EOCM2B_K1_FO
 SG_ InrtlSnsr1AccelFrm2Chksm : 50|11@0+ (1,0) [0|2047] ""  EOCM2A_IMX6_FO,EOCM2A_K2_FO,EOCM2A_K1_FO,EOCM2B_IMX6_FO,EOCM2B_K2_FO,EOCM2B_K1_FO
 SG_ InrtlSnsr1YawAccV : 5|1@0+ (1,0) [0|1] ""  EOCM2A_IMX6_FO,EOCM2A_K2_FO,EOCM2A_K1_FO,EOCM2B_IMX6_FO,EOCM2B_K2_FO,EOCM2B_K1_FO
 SG_ InrtlSnsr1YawAcc : 36|13@0- (0.024,0) [-98.304|98.28] "deg/s^2"  EOCM2A_IMX6_FO,EOCM2A_K2_FO,EOCM2A_K1_FO,EOCM2B_IMX6_FO,EOCM2B_K2_FO,EOCM2B_K1_FO
 SG_ InrtlSnsr1RollAccV : 6|1@0+ (1,0) [0|1] ""  EOCM2A_IMX6_FO,EOCM2A_K2_FO,EOCM2A_K1_FO,EOCM2B_IMX6_FO,EOCM2B_K2_FO,EOCM2B_K1_FO
 SG_ InrtlSnsr1RollAcc : 20|13@0- (0.024,0) [-98.304|98.28] "deg/s^2"  EOCM2A_IMX6_FO,EOCM2A_K2_FO,EOCM2A_K1_FO,EOCM2B_IMX6_FO,EOCM2B_K2_FO,EOCM2B_K1_FO
 SG_ InrtlSnsr1PtchAccV : 7|1@0+ (1,0) [0|1] ""  EOCM2A_IMX6_FO,EOCM2A_K2_FO,EOCM2A_K1_FO,EOCM2B_IMX6_FO,EOCM2B_K2_FO,EOCM2B_K1_FO
 SG_ InrtlSnsr1PtchAcc : 4|13@0- (0.024,0) [-98.304|98.28] "deg/s^2"  EOCM2A_IMX6_FO,EOCM2A_K2_FO,EOCM2A_K1_FO,EOCM2B_IMX6_FO,EOCM2B_K2_FO,EOCM2B_K1_FO

BO_ 310 Inertial2_Accel1_FO: 8 _DOFIMU2_FO
 SG_ MstrTrigSyncInrtl21 : 7|5@0+ (1,0) [0|31] ""  EOCM2A_IMX6_FO,EOCM2A_K2_FO,EOCM2A_K1_FO,EOCM2B_IMX6_FO,EOCM2B_K2_FO,EOCM2B_K1_FO
 SG_ Inertial2VertAccV : 34|1@0+ (1,0) [0|1] ""  EOCM2A_IMX6_FO,EOCM2A_K2_FO,EOCM2A_K1_FO,EOCM2B_IMX6_FO,EOCM2B_K2_FO,EOCM2B_K1_FO
 SG_ Inertial2VertAcc : 33|10@0- (0.0625,0) [-32|31.9375] "m/s^2"  EOCM2A_IMX6_FO,EOCM2A_K2_FO,EOCM2A_K1_FO,EOCM2B_IMX6_FO,EOCM2B_K2_FO,EOCM2B_K1_FO
 SG_ Inertial2LonAccV : 2|1@0+ (1,0) [0|1] ""  EOCM2A_IMX6_FO,EOCM2A_K2_FO,EOCM2A_K1_FO,EOCM2B_IMX6_FO,EOCM2B_K2_FO,EOCM2B_K1_FO
 SG_ Inertial2LonAcc : 1|10@0- (0.0625,0) [-32|31.9375] "m/s^2"  EOCM2A_IMX6_FO,EOCM2A_K2_FO,EOCM2A_K1_FO,EOCM2B_IMX6_FO,EOCM2B_K2_FO,EOCM2B_K1_FO
 SG_ Inertial2LatAccV : 18|1@0+ (1,0) [0|1] ""  EOCM2A_IMX6_FO,EOCM2A_K2_FO,EOCM2A_K1_FO,EOCM2B_IMX6_FO,EOCM2B_K2_FO,EOCM2B_K1_FO
 SG_ Inertial2LatAcc : 17|10@0- (0.0625,0) [-32|31.9375] "m/s^2"  EOCM2A_IMX6_FO,EOCM2A_K2_FO,EOCM2A_K1_FO,EOCM2B_IMX6_FO,EOCM2B_K2_FO,EOCM2B_K1_FO
 SG_ IntlSnsr2AcelFm1Chksm : 50|11@0+ (1,0) [0|2047] ""  EOCM2A_IMX6_FO,EOCM2A_K2_FO,EOCM2A_K1_FO,EOCM2B_IMX6_FO,EOCM2B_K2_FO,EOCM2B_K1_FO

BO_ 304 Inertial1_Accel1_FO: 8 _DOFIMU1_FO
 SG_ MstrTrigSyncInrtl11 : 7|5@0+ (1,0) [0|31] ""  EOCM2A_IMX6_FO,EOCM2A_K2_FO,EOCM2A_K1_FO,EOCM2B_IMX6_FO,EOCM2B_K2_FO,EOCM2B_K1_FO
 SG_ InrtlSnsr1VertAccV : 34|1@0+ (1,0) [0|1] ""  EOCM2A_IMX6_FO,EOCM2A_K2_FO,EOCM2A_K1_FO,EOCM2B_IMX6_FO,EOCM2B_K2_FO,EOCM2B_K1_FO
 SG_ InrtlSnsr1VertAcc : 33|10@0- (0.0625,0) [-32|31.9375] "m/s^2"  EOCM2A_IMX6_FO,EOCM2A_K2_FO,EOCM2A_K1_FO,EOCM2B_IMX6_FO,EOCM2B_K2_FO,EOCM2B_K1_FO
 SG_ InrtlSnsr1LonAccV : 2|1@0+ (1,0) [0|1] ""  EOCM2A_IMX6_FO,EOCM2A_K2_FO,EOCM2A_K1_FO,EOCM2B_IMX6_FO,EOCM2B_K2_FO,EOCM2B_K1_FO
 SG_ InrtlSnsr1LonAcc : 1|10@0- (0.0625,0) [-32|31.9375] "m/s^2"  EOCM2A_IMX6_FO,EOCM2A_K2_FO,EOCM2A_K1_FO,EOCM2B_IMX6_FO,EOCM2B_K2_FO,EOCM2B_K1_FO
 SG_ InrtlSnsr1LatAccV : 18|1@0+ (1,0) [0|1] ""  EOCM2A_IMX6_FO,EOCM2A_K2_FO,EOCM2A_K1_FO,EOCM2B_IMX6_FO,EOCM2B_K2_FO,EOCM2B_K1_FO
 SG_ InrtlSnsr1LatAcc : 17|10@0- (0.0625,0) [-32|31.9375] "m/s^2"  EOCM2A_IMX6_FO,EOCM2A_K2_FO,EOCM2A_K1_FO,EOCM2B_IMX6_FO,EOCM2B_K2_FO,EOCM2B_K1_FO
 SG_ IntlSnsr1AcelFm1Chksm : 50|11@0+ (1,0) [0|2047] ""  EOCM2A_IMX6_FO,EOCM2A_K2_FO,EOCM2A_K1_FO,EOCM2B_IMX6_FO,EOCM2B_K2_FO,EOCM2B_K1_FO

BO_ 356 Map_Pos_Correction_FO: 4 EOCM2A_K1_FO
 SG_ LongErrPstn : 7|8@0- (0.5,0) [-64|63.5] "m"  AMM_FO,EOCM2B_IMX6_FO,EOCM2B_K2_FO,EOCM2B_K1_FO
 SG_ LatErrPstn : 15|8@0- (0.5,0) [-64|63.5] "m"  AMM_FO,EOCM2B_IMX6_FO,EOCM2B_K2_FO,EOCM2B_K1_FO
 SG_ PstnErrChcksm : 18|11@0+ (1,0) [0|2047] ""  AMM_FO,EOCM2B_IMX6_FO,EOCM2B_K2_FO,EOCM2B_K1_FO
 SG_ PstnErrARC : 20|2@0+ (1,0) [0|3] ""  AMM_FO,EOCM2B_IMX6_FO,EOCM2B_K2_FO,EOCM2B_K1_FO

BO_ 354 Map_Retrans_Request_FO: 1 EOCM2A_K1_FO
 SG_ HrznPrvdRstRq : 2|1@0+ (1,0) [0|1] ""  AMM_FO,EOCM2B_IMX6_FO,EOCM2B_K2_FO,EOCM2B_K1_FO
 SG_ ADASISRwDtMplxdCycCnt : 7|2@0+ (1,0) [0|3] ""  AMM_FO,EOCM2B_IMX6_FO,EOCM2B_K2_FO,EOCM2B_K1_FO
 SG_ ADASISMsgTypRetrans : 5|3@0+ (1,0) [0|7] ""  AMM_FO,EOCM2B_IMX6_FO,EOCM2B_K2_FO,EOCM2B_K1_FO

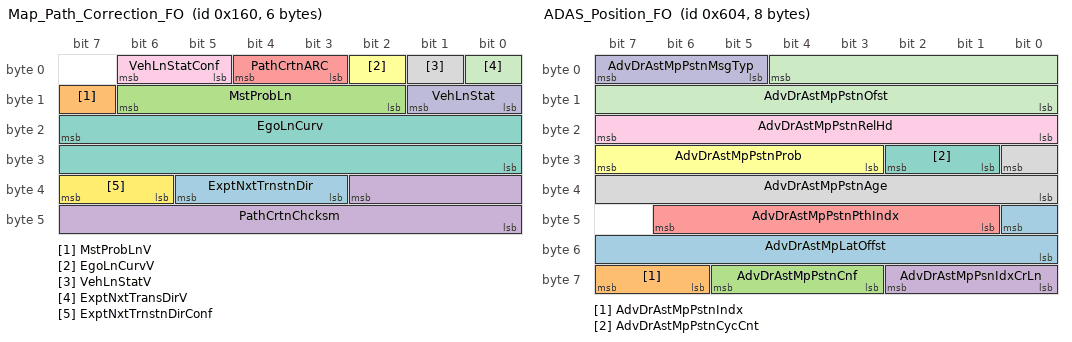
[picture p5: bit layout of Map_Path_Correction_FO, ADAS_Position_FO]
BO_ 352 Map_Path_Correction_FO: 6 EOCM2A_K1_FO
 SG_ ExptNxtTrnstnDir : 37|3@0+ (1,0) [0|7] ""  AMM_FO,EOCM2B_IMX6_FO,EOCM2B_K2_FO,EOCM2B_K1_FO
 SG_ MstProbLnV : 15|1@0+ (1,0) [0|1] ""  AMM_FO
 SG_ MstProbLn : 14|5@0+ (1,0) [0|31] ""  AMM_FO
 SG_ PathCrtnChcksm : 34|11@0+ (1,0) [0|2047] ""  AMM_FO,EOCM2B_IMX6_FO,EOCM2B_K2_FO,EOCM2B_K1_FO
 SG_ PathCrtnARC : 4|2@0+ (1,0) [0|3] ""  AMM_FO,EOCM2B_IMX6_FO,EOCM2B_K2_FO,EOCM2B_K1_FO
 SG_ EgoLnCurvV : 2|1@0+ (1,0) [0|1] ""  AMM_FO,EOCM2B_IMX6_FO,EOCM2B_K2_FO,EOCM2B_K1_FO
 SG_ EgoLnCurv : 23|16@0- (9.53E-007,0) [-0.031227904|0.031226951] "1/m^2"  AMM_FO,EOCM2B_IMX6_FO,EOCM2B_K2_FO,EOCM2B_K1_FO
 SG_ VehLnStatV : 1|1@0+ (1,0) [0|1] ""  AMM_FO,EOCM2B_IMX6_FO,EOCM2B_K2_FO,EOCM2B_K1_FO
 SG_ VehLnStatConf : 6|2@0+ (1,0) [0|3] ""  AMM_FO,EOCM2B_IMX6_FO,EOCM2B_K2_FO,EOCM2B_K1_FO
 SG_ VehLnStat : 9|2@0+ (1,0) [0|3] ""  AMM_FO,EOCM2B_IMX6_FO,EOCM2B_K2_FO,EOCM2B_K1_FO
 SG_ ExptNxtTransDirV : 0|1@0+ (1,0) [0|1] ""  AMM_FO,EOCM2B_IMX6_FO,EOCM2B_K2_FO,EOCM2B_K1_FO
 SG_ ExptNxtTrnstnDirConf : 39|2@0+ (1,0) [0|3] ""  AMM_FO,EOCM2B_IMX6_FO,EOCM2B_K2_FO,EOCM2B_K1_FO

BO_ 264 Inertial_Trigger_FO: 1 EOCM2A_K1_FO
 SG_ InrtlSnsrMstrTrgrSync : 7|5@0+ (1,0) [0|31] ""  EOCM2B_IMX6_FO,EOCM2B_K2_FO,EOCM2B_K1_FO,_DOFIMU2_FO,_DOFIMU1_FO

BO_ 1156 SSID_AMM_2_FO: 8 EOCM2A_K1_FO
 SG_ WiFiSSIDDgts9to16_Mp : 7|64@0+ (1,0) [0|0] ""  EOCM2B_K1_FO,AMM_FO

BO_ 1155 SSID_AMM_1_FO: 8 EOCM2A_K1_FO
 SG_ WiFiSSIDDgts1to8_Mp : 7|64@0+ (1,0) [0|0] ""  EOCM2B_K1_FO,AMM_FO

BO_ 1927 DTC_Triggered_787_FO: 7 DMS_FO
 SG_ DTCI_CodeSupported_787 : 40|1@0+ (1,0) [0|1] ""  TestTool_FO
 SG_ DTCI_CurrentStatus_787 : 41|1@0+ (1,0) [0|1] ""  TestTool_FO
 SG_ DTCI_DTCFailType_787 : 39|8@0+ (1,0) [0|255] ""  TestTool_FO
 SG_ DTCI_DTCFaultType_787 : 55|8@0+ (1,0) [0|255] ""  TestTool_FO
 SG_ DTCI_DTCNumber_787 : 23|16@0+ (1,0) [0|65535] ""  TestTool_FO
 SG_ DTCI_DTCSource_787 : 15|8@0+ (1,0) [0|255] ""  TestTool_FO
 SG_ DTCI_DTCTriggered_787 : 0|1@0+ (1,0) [0|1] ""  TestTool_FO
 SG_ DTCI_HistStat_787 : 44|1@0+ (1,0) [0|1] ""  TestTool_FO
 SG_ DTCI_TstFldCdClrdStat_787 : 43|1@0+ (1,0) [0|1] ""  TestTool_FO
 SG_ DTCI_TstFldPwrUpSt_787 : 46|1@0+ (1,0) [0|1] ""  TestTool_FO
 SG_ DTCI_TstNPsdCdClrdSt_787 : 42|1@0+ (1,0) [0|1] ""  TestTool_FO
 SG_ DTCI_TstNPsdPwrUpSt_787 : 45|1@0+ (1,0) [0|1] ""  TestTool_FO
 SG_ DTCIUnused1_787 : 7|1@0+ (1,0) [0|1] ""  TestTool_FO
 SG_ DTCIUnused2_787 : 6|1@0+ (1,0) [0|1] ""  TestTool_FO
 SG_ DTCIUnused3_787 : 5|1@0+ (1,0) [0|1] ""  TestTool_FO
 SG_ DTCIUnused4_787 : 4|1@0+ (1,0) [0|1] ""  TestTool_FO
 SG_ DTCIUnused5_787 : 3|1@0+ (1,0) [0|1] ""  TestTool_FO
 SG_ DTCIUnused6_787 : 2|1@0+ (1,0) [0|1] ""  TestTool_FO
 SG_ DTCIUnused7_787 : 1|1@0+ (1,0) [0|1] ""  TestTool_FO
 SG_ DTCI_WrnIndRqdSt_787 : 47|1@0+ (1,0) [0|1] ""  TestTool_FO

BO_ 1926 DTC_Triggered_786_FO: 7 AMM_FO
 SG_ DTCI_CodeSupported_786 : 40|1@0+ (1,0) [0|1] ""  TestTool_FO
 SG_ DTCI_CurrentStatus_786 : 41|1@0+ (1,0) [0|1] ""  TestTool_FO
 SG_ DTCI_DTCFailType_786 : 39|8@0+ (1,0) [0|255] ""  TestTool_FO
 SG_ DTCI_DTCFaultType_786 : 55|8@0+ (1,0) [0|255] ""  TestTool_FO
 SG_ DTCI_DTCNumber_786 : 23|16@0+ (1,0) [0|65535] ""  TestTool_FO
 SG_ DTCI_DTCSource_786 : 15|8@0+ (1,0) [0|255] ""  TestTool_FO
 SG_ DTCI_DTCTriggered_786 : 0|1@0+ (1,0) [0|1] ""  TestTool_FO
 SG_ DTCI_HistStat_786 : 44|1@0+ (1,0) [0|1] ""  TestTool_FO
 SG_ DTCI_TstFldCdClrdStat_786 : 43|1@0+ (1,0) [0|1] ""  TestTool_FO
 SG_ DTCI_TstFldPwrUpSt_786 : 46|1@0+ (1,0) [0|1] ""  TestTool_FO
 SG_ DTCI_TstNPsdCdClrdSt_786 : 42|1@0+ (1,0) [0|1] ""  TestTool_FO
 SG_ DTCI_TstNPsdPwrUpSt_786 : 45|1@0+ (1,0) [0|1] ""  TestTool_FO
 SG_ DTCIUnused1_786 : 7|1@0+ (1,0) [0|1] ""  TestTool_FO
 SG_ DTCIUnused2_786 : 6|1@0+ (1,0) [0|1] ""  TestTool_FO
 SG_ DTCIUnused3_786 : 5|1@0+ (1,0) [0|1] ""  TestTool_FO
 SG_ DTCIUnused4_786 : 4|1@0+ (1,0) [0|1] ""  TestTool_FO
 SG_ DTCIUnused5_786 : 3|1@0+ (1,0) [0|1] ""  TestTool_FO
 SG_ DTCIUnused6_786 : 2|1@0+ (1,0) [0|1] ""  TestTool_FO
 SG_ DTCIUnused7_786 : 1|1@0+ (1,0) [0|1] ""  TestTool_FO
 SG_ DTCI_WrnIndRqdSt_786 : 47|1@0+ (1,0) [0|1] ""  TestTool_FO

BO_ 1928 DTC_Triggered_788_FO: 7 _DOFIMU1_FO
 SG_ DTCI_CodeSupported_788 : 40|1@0+ (1,0) [0|1] ""  TestTool_FO
 SG_ DTCI_CurrentStatus_788 : 41|1@0+ (1,0) [0|1] ""  TestTool_FO
 SG_ DTCI_DTCFailType_788 : 39|8@0+ (1,0) [0|255] ""  TestTool_FO
 SG_ DTCI_DTCFaultType_788 : 55|8@0+ (1,0) [0|255] ""  TestTool_FO
 SG_ DTCI_DTCNumber_788 : 23|16@0+ (1,0) [0|65535] ""  TestTool_FO
 SG_ DTCI_DTCSource_788 : 15|8@0+ (1,0) [0|255] ""  TestTool_FO
 SG_ DTCI_DTCTriggered_788 : 0|1@0+ (1,0) [0|1] ""  TestTool_FO
 SG_ DTCI_HistStat_788 : 44|1@0+ (1,0) [0|1] ""  TestTool_FO
 SG_ DTCI_TstFldCdClrdStat_788 : 42|1@0+ (1,0) [0|1] ""  TestTool_FO
 SG_ DTCI_TstFldPwrUpSt_788 : 46|1@0+ (1,0) [0|1] ""  TestTool_FO
 SG_ DTCI_TstNPsdCdClrdSt_788 : 43|1@0+ (1,0) [0|1] ""  TestTool_FO
 SG_ DTCI_TstNPsdPwrUpSt_788 : 45|1@0+ (1,0) [0|1] ""  TestTool_FO
 SG_ DTCIUnused1_788 : 7|1@0+ (1,0) [0|1] ""  TestTool_FO
 SG_ DTCIUnused2_788 : 6|1@0+ (1,0) [0|1] ""  TestTool_FO
 SG_ DTCIUnused3_788 : 5|1@0+ (1,0) [0|1] ""  TestTool_FO
 SG_ DTCIUnused4_788 : 4|1@0+ (1,0) [0|1] ""  TestTool_FO
 SG_ DTCIUnused5_788 : 3|1@0+ (1,0) [0|1] ""  TestTool_FO
 SG_ DTCIUnused6_788 : 2|1@0+ (1,0) [0|1] ""  TestTool_FO
 SG_ DTCIUnused7_788 : 1|1@0+ (1,0) [0|1] ""  TestTool_FO
 SG_ DTCI_WrnIndRqdSt_788 : 47|1@0+ (1,0) [0|1] ""  TestTool_FO

BO_ 1929 DTC_Triggered_789_FO: 7 _DOFIMU2_FO
 SG_ DTCI_CodeSupported_789 : 40|1@0+ (1,0) [0|1] ""  TestTool_FO
 SG_ DTCI_CurrentStatus_789 : 41|1@0+ (1,0) [0|1] ""  TestTool_FO
 SG_ DTCI_DTCFailType_789 : 39|8@0+ (1,0) [0|255] ""  TestTool_FO
 SG_ DTCI_DTCFaultType_789 : 55|8@0+ (1,0) [0|255] ""  TestTool_FO
 SG_ DTCI_DTCNumber_789 : 23|16@0+ (1,0) [0|65535] ""  TestTool_FO
 SG_ DTCI_DTCSource_789 : 15|8@0+ (1,0) [0|255] ""  TestTool_FO
 SG_ DTCI_DTCTriggered_789 : 0|1@0+ (1,0) [0|1] ""  TestTool_FO
 SG_ DTCI_HistStat_789 : 44|1@0+ (1,0) [0|1] ""  TestTool_FO
 SG_ DTCI_TstFldCdClrdStat_789 : 43|1@0+ (1,0) [0|1] ""  TestTool_FO
 SG_ DTCI_TstFldPwrUpSt_789 : 46|1@0+ (1,0) [0|1] ""  TestTool_FO
 SG_ DTCI_TstNPsdCdClrdSt_789 : 42|1@0+ (1,0) [0|1] ""  TestTool_FO
 SG_ DTCI_TstNPsdPwrUpSt_789 : 45|1@0+ (1,0) [0|1] ""  TestTool_FO
 SG_ DTCIUnused1_789 : 7|1@0+ (1,0) [0|1] ""  TestTool_FO
 SG_ DTCIUnused2_789 : 6|1@0+ (1,0) [0|1] ""  TestTool_FO
 SG_ DTCIUnused3_789 : 5|1@0+ (1,0) [0|1] ""  TestTool_FO
 SG_ DTCIUnused4_789 : 4|1@0+ (1,0) [0|1] ""  TestTool_FO
 SG_ DTCIUnused5_789 : 3|1@0+ (1,0) [0|1] ""  TestTool_FO
 SG_ DTCIUnused6_789 : 2|1@0+ (1,0) [0|1] ""  TestTool_FO
 SG_ DTCIUnused7_789 : 1|1@0+ (1,0) [0|1] ""  TestTool_FO
 SG_ DTCI_WrnIndRqdSt_789 : 47|1@0+ (1,0) [0|1] ""  TestTool_FO

BO_ 1352 UUDT_Resp_From_6DOFIMU2_FO: 8 _DOFIMU2_FO
 SG_ DgnInf : 7|64@0+ (1,0) [0|1.84467440737096E+019] ""  TestTool_FO

BO_ 588 USDT_Req_to_EOCM2B_K1_FO: 8 TestTool_FO
 SG_ DgnInf : 7|64@0+ (1,0) [0|1.84467440737096E+019] ""  EOCM2B_K1_FO

BO_ 1356 UUDT_Resp_From_EOCM2B_K1_FO: 8 EOCM2B_K1_FO
 SG_ DgnInf : 7|64@0+ (1,0) [0|1.84467440737096E+019] ""  TestTool_FO

BO_ 1612 USDT_Resp_From_EOCM2B_K1_FO: 8 EOCM2B_K1_FO
 SG_ DgnInf : 7|64@0+ (1,0) [0|1.84467440737096E+019] ""  TestTool_FO

BO_ 1616 USDT_Resp_From_EOCM2A_IMX6_FO: 8 EOCM2A_IMX6_FO
 SG_ DgnInf : 7|64@0+ (1,0) [0|1.84467440737096E+019] ""  TestTool_FO

BO_ 1360 UUDT_Resp_From_EOCM2A_IMX6_FO: 8 EOCM2A_IMX6_FO
 SG_ DgnInf : 7|64@0+ (1,0) [0|1.84467440737096E+019] ""  TestTool_FO

BO_ 592 USDT_Req_to_EOCM2A_IMX6_FO: 8 TestTool_FO
 SG_ DgnInf : 7|64@0+ (1,0) [0|1.84467440737096E+019] ""  EOCM2A_IMX6_FO

BO_ 1610 USDT_Resp_From_EOCM2A_K1_FO: 8 EOCM2A_K1_FO
 SG_ DgnInf : 7|64@0+ (1,0) [0|1.84467440737096E+019] ""  TestTool_FO

BO_ 1354 UUDT_Resp_From_EOCM2A_K1_FO: 8 EOCM2A_K1_FO
 SG_ DgnInf : 7|64@0+ (1,0) [0|1.84467440737096E+019] ""  TestTool_FO

BO_ 586 USDT_Req_to_EOCM2A_K1_FO: 8 TestTool_FO
 SG_ DgnInf : 7|64@0+ (1,0) [0|1.84467440737096E+019] ""  EOCM2A_K1_FO

BO_ 1925 DTC_Triggered_785_FO: 7 NVS_FO
 SG_ DTCI_CodeSupported_785 : 40|1@0+ (1,0) [0|1] ""  TestTool_FO
 SG_ DTCI_CurrentStatus_785 : 41|1@0+ (1,0) [0|1] ""  TestTool_FO
 SG_ DTCI_DTCFailType_785 : 39|8@0+ (1,0) [0|255] ""  TestTool_FO
 SG_ DTCI_DTCFaultType_785 : 55|8@0+ (1,0) [0|255] ""  TestTool_FO
 SG_ DTCI_DTCNumber_785 : 23|16@0+ (1,0) [0|65535] ""  TestTool_FO
 SG_ DTCI_DTCSource_785 : 15|8@0+ (1,0) [0|255] ""  TestTool_FO
 SG_ DTCI_DTCTriggered_785 : 0|1@0+ (1,0) [0|1] ""  TestTool_FO
 SG_ DTCI_HistStat_785 : 44|1@0+ (1,0) [0|1] ""  TestTool_FO
 SG_ DTCI_TstFldCdClrdStat_785 : 43|1@0+ (1,0) [0|1] ""  TestTool_FO
 SG_ DTCI_TstFldPwrUpSt_785 : 46|1@0+ (1,0) [0|1] ""  TestTool_FO
 SG_ DTCI_TstNPsdCdClrdSt_785 : 42|1@0+ (1,0) [0|1] ""  TestTool_FO
 SG_ DTCI_TstNPsdPwrUpSt_785 : 45|1@0+ (1,0) [0|1] ""  TestTool_FO
 SG_ DTCIUnused1_785 : 7|1@0+ (1,0) [0|1] ""  TestTool_FO
 SG_ DTCIUnused2_785 : 6|1@0+ (1,0) [0|1] ""  TestTool_FO
 SG_ DTCIUnused3_785 : 5|1@0+ (1,0) [0|1] ""  TestTool_FO
 SG_ DTCIUnused4_785 : 4|1@0+ (1,0) [0|1] ""  TestTool_FO
 SG_ DTCIUnused5_785 : 3|1@0+ (1,0) [0|1] ""  TestTool_FO
 SG_ DTCIUnused6_785 : 2|1@0+ (1,0) [0|1] ""  TestTool_FO
 SG_ DTCIUnused7_785 : 1|1@0+ (1,0) [0|1] ""  TestTool_FO
 SG_ DTCI_WrnIndRqdSt_785 : 47|1@0+ (1,0) [0|1] ""  TestTool_FO

BO_ 1859 VIN_Digits_10_to_17_FO: 8 EOCM_F_FO
 SG_ VehIdNmDig10_17 : 7|64@0+ (1,0) [0|1] ""  EOCM2B_IMX6_FO,EOCM2B_K2_FO,EOCM2B_K1_FO,NVS_FO

BO_ 1857 VIN_Digits_2_to_9_FO: 8 EOCM_F_FO
 SG_ VehIdNmDig2_9 : 7|64@0+ (1,0) [0|1] ""  EOCM2B_IMX6_FO,EOCM2B_K2_FO,EOCM2B_K1_FO,NVS_FO

BO_ 771 Outside_Air_Temperature_FO: 2 EOCM_F_FO
 SG_ OtsAirTmpCrValV : 0|1@0+ (1,0) [0|1] ""  NVS_FO
 SG_ OtsAirTmpCrVal : 15|8@0+ (0.5,-40) [-40|87.5] "deg C"  NVS_FO

BO_ 777 Night_Vision_System_Ped_FO: 1 NVS_FO
 SG_ NVSysStat : 3|3@0+ (1,0) [0|7] ""  EOCM2A_IMX6_FO,EOCM2A_K2_FO,EOCM2A_K1_FO,EOCM2B_IMX6_FO,EOCM2B_K2_FO,EOCM2B_K1_FO,EOCM_F_FO
 SG_ NVSysPedWrnIndReq : 7|2@0+ (1,0) [0|3] ""  EOCM2A_IMX6_FO,EOCM2A_K2_FO,EOCM2A_K1_FO,EOCM2B_IMX6_FO,EOCM2B_K2_FO,EOCM2B_K1_FO,EOCM_F_FO
 SG_ NVSysPedDetCsCrStVal : 5|2@0+ (1,0) [0|3] ""  EOCM2A_IMX6_FO,EOCM2A_K2_FO,EOCM2A_K1_FO,EOCM2B_IMX6_FO,EOCM2B_K2_FO,EOCM2B_K1_FO,EOCM_F_FO
 SG_ NVSysPedDetCstStAvl : 0|1@0+ (1,0) [0|1] ""  EOCM2A_IMX6_FO,EOCM2A_K2_FO,EOCM2A_K1_FO,EOCM2B_IMX6_FO,EOCM2B_K2_FO,EOCM2B_K1_FO,EOCM_F_FO

BO_ 607 USDT_Req_to_NVS_FO: 8 TestTool_FO
 SG_ DgnInf : 7|64@0+ (1,0) [0|1.84467440737096E+019] ""  NVS_FO

BO_ 1631 USDT_Resp_From_NVS_FO: 8 NVS_FO
 SG_ DgnInf : 7|64@0+ (1,0) [0|1.84467440737096E+019] ""  TestTool_FO

BO_ 1375 UUDT_Resp_From_NVS_FO: 8 NVS_FO
 SG_ DgnInf : 7|64@0+ (1,0) [0|1.84467440737096E+019] ""  TestTool_FO

BO_ 1540 ADAS_Position_FO: 8 AMM_FO
 SG_ AdvDrAstMpLatOffst : 40|9@0+ (1,-256) [-256|255] "m"  EOCM2B_IMX6_FO,EOCM2B_K2_FO,EOCM2B_K1_FO,EOCM2A_IMX6_FO,EOCM2A_K2_FO,EOCM2A_K1_FO
 SG_ AdvDrAstMpPstnIndx : 63|2@0+ (1,0) [0|3] ""  EOCM2B_IMX6_FO,EOCM2B_K2_FO,EOCM2B_K1_FO,EOCM2A_IMX6_FO,EOCM2A_K2_FO,EOCM2A_K1_FO
 SG_ AdvDrAstMpPstnCnf : 61|3@0+ (1,0) [0|7] ""  EOCM2B_IMX6_FO,EOCM2B_K2_FO,EOCM2B_K1_FO,EOCM2A_IMX6_FO,EOCM2A_K2_FO,EOCM2A_K1_FO
 SG_ AdvDrAstMpPsnIdxCrLn : 58|3@0+ (1,0) [0|7] ""  EOCM2B_IMX6_FO,EOCM2B_K2_FO,EOCM2B_K1_FO,EOCM2A_IMX6_FO,EOCM2A_K2_FO,EOCM2A_K1_FO
 SG_ AdvDrAstMpPstnPthIndx : 46|6@0+ (1,0) [0|63] ""  EOCM2B_IMX6_FO,EOCM2B_K2_FO,EOCM2B_K1_FO,EOCM2A_IMX6_FO,EOCM2A_K2_FO,EOCM2A_K1_FO
 SG_ AdvDrAstMpPstnProb : 31|5@0+ (3.333,0) [0|103.323] "%"  EOCM2B_IMX6_FO,EOCM2B_K2_FO,EOCM2B_K1_FO,EOCM2A_IMX6_FO,EOCM2A_K2_FO,EOCM2A_K1_FO
 SG_ AdvDrAstMpPstnCycCnt : 26|2@0+ (1,0) [0|3] ""  EOCM2B_IMX6_FO,EOCM2B_K2_FO,EOCM2B_K1_FO,EOCM2A_IMX6_FO,EOCM2A_K2_FO,EOCM2A_K1_FO
 SG_ AdvDrAstMpPstnAge : 24|9@0+ (5,0) [0|2555] "ms"  EOCM2B_IMX6_FO,EOCM2B_K2_FO,EOCM2B_K1_FO,EOCM2A_IMX6_FO,EOCM2A_K2_FO,EOCM2A_K1_FO
 SG_ AdvDrAstMpPstnRelHd : 23|8@0+ (1.417,0) [0|361.335] "deg"  EOCM2B_IMX6_FO,EOCM2B_K2_FO,EOCM2B_K1_FO,EOCM2A_IMX6_FO,EOCM2A_K2_FO,EOCM2A_K1_FO
 SG_ AdvDrAstMpPstnMsgTyp : 7|3@0+ (1,0) [0|7] ""  EOCM2B_IMX6_FO,EOCM2B_K2_FO,EOCM2B_K1_FO,EOCM2A_IMX6_FO,EOCM2A_K2_FO,EOCM2A_K1_FO
 SG_ AdvDrAstMpPstnOfst : 4|13@0+ (1,0) [0|8191] "m"  EOCM2B_IMX6_FO,EOCM2B_K2_FO,EOCM2B_K1_FO,EOCM2A_IMX6_FO,EOCM2A_K2_FO,EOCM2A_K1_FO

BO_ 1608 USDT_Resp_From_6DOFIMU2_FO: 8 _DOFIMU2_FO
 SG_ DgnInf : 7|64@0+ (1,0) [0|1.84467440737096E+019] ""  TestTool_FO

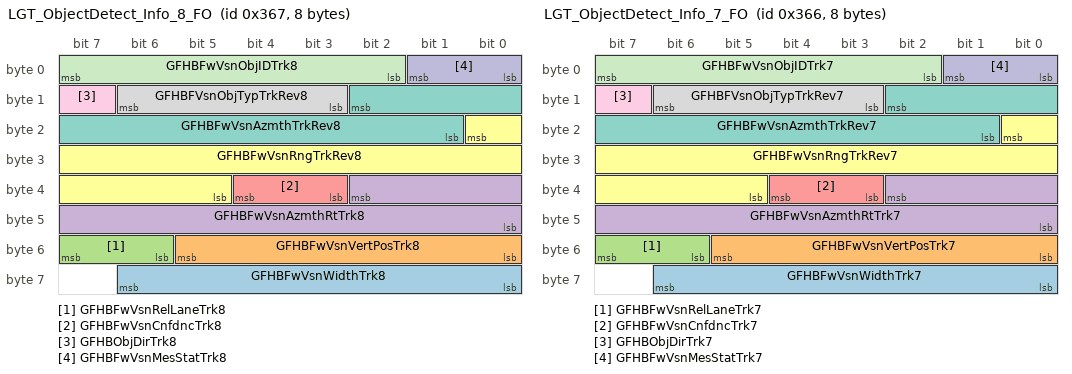
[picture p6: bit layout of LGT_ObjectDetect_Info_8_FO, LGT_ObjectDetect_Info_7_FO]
BO_ 871 LGT_ObjectDetect_Info_8_FO: 8 VIS2_FO
 SG_ GFHBFwVsnWidthTrk8 : 62|7@0+ (0.1,0) [0|12.7] "deg"  EOCM_F_FO
 SG_ GFHBFwVsnVertPosTrk8 : 53|6@0+ (0.25,-3) [-3|12.75] "deg"  EOCM_F_FO
 SG_ GFHBFwVsnRelLaneTrk8 : 55|2@0+ (1,0) [0|3] ""  EOCM_F_FO
 SG_ GFHBFwVsnAzmthRtTrk8 : 34|11@0- (0.125,0) [-128|127.875] "deg/s"  EOCM_F_FO
 SG_ GFHBFwVsnCnfdncTrk8 : 36|2@0+ (1,0) [0|3] ""  EOCM_F_FO
 SG_ GFHBFwVsnRngTrkRev8 : 16|12@0+ (0.2,0) [0|819] "m"  EOCM_F_FO
 SG_ GFHBFwVsnAzmthTrkRev8 : 10|10@0- (0.05,0) [-25.6|25.55] "deg"  EOCM_F_FO
 SG_ GFHBFVsnObjTypTrkRev8 : 14|4@0+ (1,0) [0|15] ""  EOCM_F_FO
 SG_ GFHBObjDirTrk8 : 15|1@0+ (1,0) [0|1] ""  EOCM_F_FO
 SG_ GFHBFwVsnMesStatTrk8 : 1|2@0+ (1,0) [0|3] ""  EOCM_F_FO
 SG_ GFHBFwVsnObjIDTrk8 : 7|6@0+ (1,0) [0|63] ""  EOCM_F_FO

BO_ 870 LGT_ObjectDetect_Info_7_FO: 8 VIS2_FO
 SG_ GFHBFwVsnWidthTrk7 : 62|7@0+ (0.1,0) [0|12.7] "deg"  EOCM_F_FO
 SG_ GFHBFwVsnVertPosTrk7 : 53|6@0+ (0.25,-3) [-3|12.75] "deg"  EOCM_F_FO
 SG_ GFHBFwVsnRelLaneTrk7 : 55|2@0+ (1,0) [0|3] ""  EOCM_F_FO
 SG_ GFHBFwVsnAzmthRtTrk7 : 34|11@0- (0.125,0) [-128|127.875] "deg/s"  EOCM_F_FO
 SG_ GFHBFwVsnCnfdncTrk7 : 36|2@0+ (1,0) [0|3] ""  EOCM_F_FO
 SG_ GFHBFwVsnRngTrkRev7 : 16|12@0+ (0.2,0) [0|819] "m"  EOCM_F_FO
 SG_ GFHBFwVsnAzmthTrkRev7 : 10|10@0- (0.05,0) [-25.6|25.55] "deg"  EOCM_F_FO
 SG_ GFHBFVsnObjTypTrkRev7 : 14|4@0+ (1,0) [0|15] ""  EOCM_F_FO
 SG_ GFHBObjDirTrk7 : 15|1@0+ (1,0) [0|1] ""  EOCM_F_FO
 SG_ GFHBFwVsnMesStatTrk7 : 1|2@0+ (1,0) [0|3] ""  EOCM_F_FO
 SG_ GFHBFwVsnObjIDTrk7 : 7|6@0+ (1,0) [0|63] ""  EOCM_F_FO

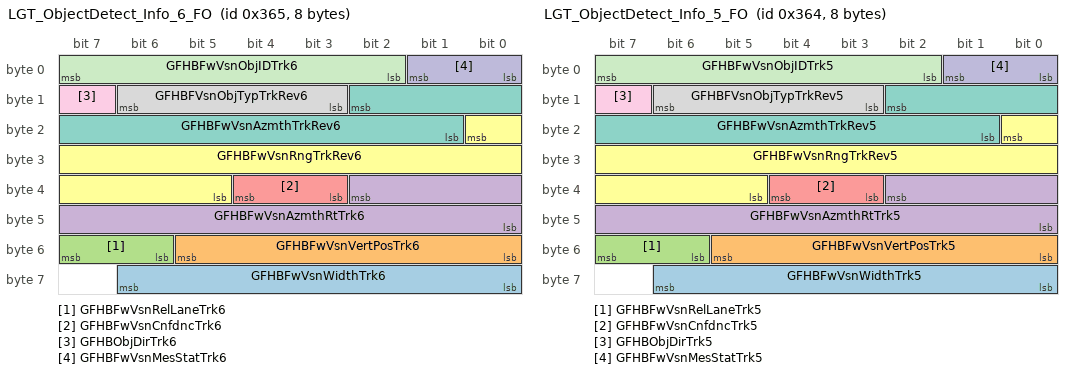
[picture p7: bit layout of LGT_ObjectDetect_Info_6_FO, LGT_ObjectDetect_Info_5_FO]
BO_ 869 LGT_ObjectDetect_Info_6_FO: 8 VIS2_FO
 SG_ GFHBFwVsnWidthTrk6 : 62|7@0+ (0.1,0) [0|12.7] "deg"  EOCM_F_FO
 SG_ GFHBFwVsnVertPosTrk6 : 53|6@0+ (0.25,-3) [-3|12.75] "deg"  EOCM_F_FO
 SG_ GFHBFwVsnRelLaneTrk6 : 55|2@0+ (1,0) [0|3] ""  EOCM_F_FO
 SG_ GFHBFwVsnAzmthRtTrk6 : 34|11@0- (0.125,0) [-128|127.875] "deg/s"  EOCM_F_FO
 SG_ GFHBFwVsnCnfdncTrk6 : 36|2@0+ (1,0) [0|3] ""  EOCM_F_FO
 SG_ GFHBFwVsnRngTrkRev6 : 16|12@0+ (0.2,0) [0|819] "m"  EOCM_F_FO
 SG_ GFHBFwVsnAzmthTrkRev6 : 10|10@0- (0.05,0) [-25.6|25.55] "deg"  EOCM_F_FO
 SG_ GFHBFVsnObjTypTrkRev6 : 14|4@0+ (1,0) [0|15] ""  EOCM_F_FO
 SG_ GFHBObjDirTrk6 : 15|1@0+ (1,0) [0|1] ""  EOCM_F_FO
 SG_ GFHBFwVsnMesStatTrk6 : 1|2@0+ (1,0) [0|3] ""  EOCM_F_FO
 SG_ GFHBFwVsnObjIDTrk6 : 7|6@0+ (1,0) [0|63] ""  EOCM_F_FO

BO_ 868 LGT_ObjectDetect_Info_5_FO: 8 VIS2_FO
 SG_ GFHBFwVsnWidthTrk5 : 62|7@0+ (0.1,0) [0|12.7] "deg"  EOCM_F_FO
 SG_ GFHBFwVsnVertPosTrk5 : 53|6@0+ (0.25,-3) [-3|12.75] "deg"  EOCM_F_FO
 SG_ GFHBFwVsnRelLaneTrk5 : 55|2@0+ (1,0) [0|3] ""  EOCM_F_FO
 SG_ GFHBFwVsnAzmthRtTrk5 : 34|11@0- (0.125,0) [-128|127.875] "deg/s"  EOCM_F_FO
 SG_ GFHBFwVsnCnfdncTrk5 : 36|2@0+ (1,0) [0|3] ""  EOCM_F_FO
 SG_ GFHBFwVsnRngTrkRev5 : 16|12@0+ (0.2,0) [0|819] "m"  EOCM_F_FO
 SG_ GFHBFwVsnAzmthTrkRev5 : 10|10@0- (0.05,0) [-25.6|25.55] "deg"  EOCM_F_FO
 SG_ GFHBFVsnObjTypTrkRev5 : 14|4@0+ (1,0) [0|15] ""  EOCM_F_FO
 SG_ GFHBObjDirTrk5 : 15|1@0+ (1,0) [0|1] ""  EOCM_F_FO
 SG_ GFHBFwVsnMesStatTrk5 : 1|2@0+ (1,0) [0|3] ""  EOCM_F_FO
 SG_ GFHBFwVsnObjIDTrk5 : 7|6@0+ (1,0) [0|63] ""  EOCM_F_FO

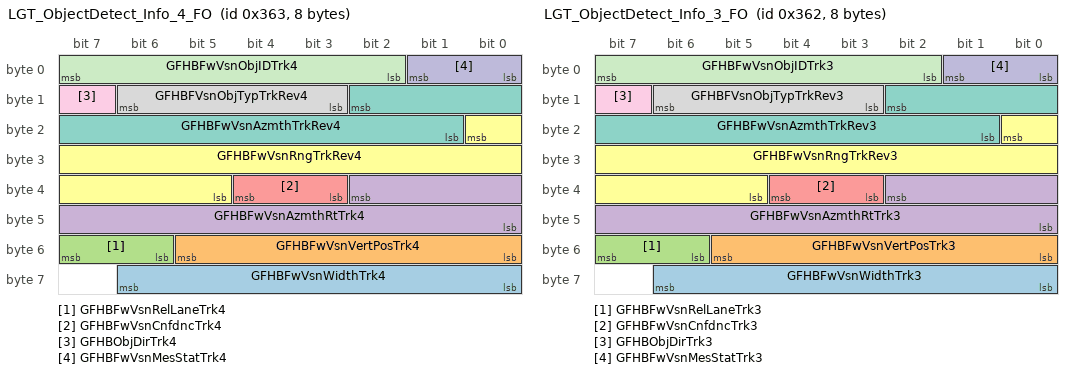
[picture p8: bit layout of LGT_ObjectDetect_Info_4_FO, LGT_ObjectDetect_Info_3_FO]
BO_ 867 LGT_ObjectDetect_Info_4_FO: 8 VIS2_FO
 SG_ GFHBFwVsnWidthTrk4 : 62|7@0+ (0.1,0) [0|12.7] "deg"  EOCM_F_FO
 SG_ GFHBFwVsnVertPosTrk4 : 53|6@0+ (0.25,-3) [-3|12.75] "deg"  EOCM_F_FO
 SG_ GFHBFwVsnRelLaneTrk4 : 55|2@0+ (1,0) [0|3] ""  EOCM_F_FO
 SG_ GFHBFwVsnAzmthRtTrk4 : 34|11@0- (0.125,0) [-128|127.875] "deg/s"  EOCM_F_FO
 SG_ GFHBFwVsnCnfdncTrk4 : 36|2@0+ (1,0) [0|3] ""  EOCM_F_FO
 SG_ GFHBFwVsnRngTrkRev4 : 16|12@0+ (0.2,0) [0|819] "m"  EOCM_F_FO
 SG_ GFHBFwVsnAzmthTrkRev4 : 10|10@0- (0.05,0) [-25.6|25.55] "deg"  EOCM_F_FO
 SG_ GFHBFVsnObjTypTrkRev4 : 14|4@0+ (1,0) [0|15] ""  EOCM_F_FO
 SG_ GFHBObjDirTrk4 : 15|1@0+ (1,0) [0|1] ""  EOCM_F_FO
 SG_ GFHBFwVsnMesStatTrk4 : 1|2@0+ (1,0) [0|3] ""  EOCM_F_FO
 SG_ GFHBFwVsnObjIDTrk4 : 7|6@0+ (1,0) [0|63] ""  EOCM_F_FO

BO_ 866 LGT_ObjectDetect_Info_3_FO: 8 VIS2_FO
 SG_ GFHBFwVsnWidthTrk3 : 62|7@0+ (0.1,0) [0|12.7] "deg"  EOCM_F_FO
 SG_ GFHBFwVsnVertPosTrk3 : 53|6@0+ (0.25,-3) [-3|12.75] "deg"  EOCM_F_FO
 SG_ GFHBFwVsnRelLaneTrk3 : 55|2@0+ (1,0) [0|3] ""  EOCM_F_FO
 SG_ GFHBFwVsnAzmthRtTrk3 : 34|11@0- (0.125,0) [-128|127.875] "deg/s"  EOCM_F_FO
 SG_ GFHBFwVsnCnfdncTrk3 : 36|2@0+ (1,0) [0|3] ""  EOCM_F_FO
 SG_ GFHBFwVsnRngTrkRev3 : 16|12@0+ (0.2,0) [0|819] "m"  EOCM_F_FO
 SG_ GFHBFwVsnAzmthTrkRev3 : 10|10@0- (0.05,0) [-25.6|25.55] "deg"  EOCM_F_FO
 SG_ GFHBFVsnObjTypTrkRev3 : 14|4@0+ (1,0) [0|15] ""  EOCM_F_FO
 SG_ GFHBObjDirTrk3 : 15|1@0+ (1,0) [0|1] ""  EOCM_F_FO
 SG_ GFHBFwVsnMesStatTrk3 : 1|2@0+ (1,0) [0|3] ""  EOCM_F_FO
 SG_ GFHBFwVsnObjIDTrk3 : 7|6@0+ (1,0) [0|63] ""  EOCM_F_FO

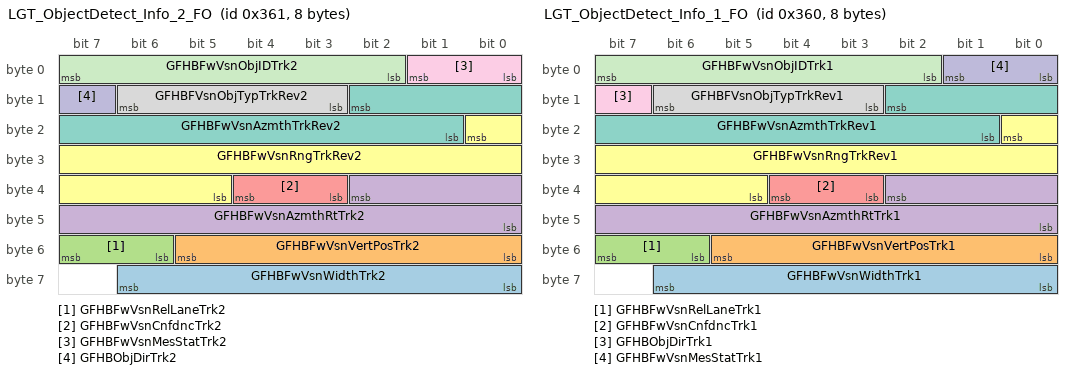
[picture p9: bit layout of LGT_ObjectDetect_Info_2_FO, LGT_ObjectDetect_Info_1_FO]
BO_ 865 LGT_ObjectDetect_Info_2_FO: 8 VIS2_FO
 SG_ GFHBFwVsnWidthTrk2 : 62|7@0+ (0.1,0) [0|12.7] "deg"  EOCM_F_FO
 SG_ GFHBFwVsnVertPosTrk2 : 53|6@0+ (0.25,-3) [-3|12.75] "deg"  EOCM_F_FO
 SG_ GFHBFwVsnRelLaneTrk2 : 55|2@0+ (1,0) [0|3] ""  EOCM_F_FO
 SG_ GFHBFwVsnAzmthRtTrk2 : 34|11@0- (0.125,0) [-128|127.875] "deg/s"  EOCM_F_FO
 SG_ GFHBFwVsnCnfdncTrk2 : 36|2@0+ (1,0) [0|3] ""  EOCM_F_FO
 SG_ GFHBFwVsnRngTrkRev2 : 16|12@0+ (0.2,0) [0|819] "m"  EOCM_F_FO
 SG_ GFHBFwVsnAzmthTrkRev2 : 10|10@0- (0.05,0) [-25.6|25.55] "deg"  EOCM_F_FO
 SG_ GFHBFVsnObjTypTrkRev2 : 14|4@0+ (1,0) [0|15] ""  EOCM_F_FO
 SG_ GFHBFwVsnMesStatTrk2 : 1|2@0+ (1,0) [0|3] ""  EOCM_F_FO
 SG_ GFHBObjDirTrk2 : 15|1@0+ (1,0) [0|1] ""  EOCM_F_FO
 SG_ GFHBFwVsnObjIDTrk2 : 7|6@0+ (1,0) [0|63] ""  EOCM_F_FO

BO_ 864 LGT_ObjectDetect_Info_1_FO: 8 VIS2_FO
 SG_ GFHBFwVsnWidthTrk1 : 62|7@0+ (0.1,0) [0|12.7] "deg"  EOCM_F_FO
 SG_ GFHBFwVsnVertPosTrk1 : 53|6@0+ (0.25,-3) [-3|12.75] "deg"  EOCM_F_FO
 SG_ GFHBFwVsnRelLaneTrk1 : 55|2@0+ (1,0) [0|3] ""  EOCM_F_FO
 SG_ GFHBFwVsnAzmthRtTrk1 : 34|11@0- (0.125,0) [-128|127.875] "deg/s"  EOCM_F_FO
 SG_ GFHBFwVsnCnfdncTrk1 : 36|2@0+ (1,0) [0|3] ""  EOCM_F_FO
 SG_ GFHBFwVsnRngTrkRev1 : 16|12@0+ (0.2,0) [0|819] "m"  EOCM_F_FO
 SG_ GFHBFwVsnAzmthTrkRev1 : 10|10@0- (0.05,0) [-25.6|25.55] "deg"  EOCM_F_FO
 SG_ GFHBFVsnObjTypTrkRev1 : 14|4@0+ (1,0) [0|15] ""  EOCM_F_FO
 SG_ GFHBObjDirTrk1 : 15|1@0+ (1,0) [0|1] ""  EOCM_F_FO
 SG_ GFHBFwVsnMesStatTrk1 : 1|2@0+ (1,0) [0|3] ""  EOCM_F_FO
 SG_ GFHBFwVsnObjIDTrk1 : 7|6@0+ (1,0) [0|63] ""  EOCM_F_FO

BO_ 1915 DTC_Triggered_77B_FO: 7 VIS_FO
 SG_ DTCI_DTCFaultType_77B : 55|8@0+ (1,0) [0|255] ""  TestTool_FO
 SG_ DTCI_CodeSupported_77B : 40|1@0+ (1,0) [0|1] ""  TestTool_FO
 SG_ DTCI_CurrentStatus_77B : 41|1@0+ (1,0) [0|1] ""  TestTool_FO
 SG_ DTCI_TstNPsdCdClrdSt_77B : 42|1@0+ (1,0) [0|1] ""  TestTool_FO
 SG_ DTCI_TstFldCdClrdStat_77B : 43|1@0+ (1,0) [0|1] ""  TestTool_FO
 SG_ DTCI_HistStat_77B : 44|1@0+ (1,0) [0|1] ""  TestTool_FO
 SG_ DTCI_TstNPsdPwrUpSt_77B : 45|1@0+ (1,0) [0|1] ""  TestTool_FO
 SG_ DTCI_TstFldPwrUpSt_77B : 46|1@0+ (1,0) [0|1] ""  TestTool_FO
 SG_ DTCI_WrnIndRqdSt_77B : 47|1@0+ (1,0) [0|1] ""  TestTool_FO
 SG_ DTCI_DTCFailType_77B : 39|8@0+ (1,0) [0|255] ""  TestTool_FO
 SG_ DTCI_DTCNumber_77B : 23|16@0+ (1,0) [0|65535] ""  TestTool_FO
 SG_ DTCI_DTCSource_77B : 15|8@0+ (1,0) [0|255] ""  TestTool_FO
 SG_ DTCI_DTCTriggered_77B : 0|1@0+ (1,0) [0|1] ""  TestTool_FO
 SG_ DTCIUnused7_77B : 1|1@0+ (1,0) [0|1] ""  TestTool_FO
 SG_ DTCIUnused6_77B : 2|1@0+ (1,0) [0|1] ""  TestTool_FO
 SG_ DTCIUnused5_77B : 3|1@0+ (1,0) [0|1] ""  TestTool_FO
 SG_ DTCIUnused4_77B : 4|1@0+ (1,0) [0|1] ""  TestTool_FO
 SG_ DTCIUnused3_77B : 5|1@0+ (1,0) [0|1] ""  TestTool_FO
 SG_ DTCIUnused2_77B : 6|1@0+ (1,0) [0|1] ""  TestTool_FO
 SG_ DTCIUnused1_77B : 7|1@0+ (1,0) [0|1] ""  TestTool_FO

BO_ 1923 DTC_Triggered_783_FO: 7 RSRR_FO
 SG_ DTCI_WrnIndRqdSt_783 : 47|1@0+ (1,0) [0|1] ""  TestTool_FO
 SG_ DTCI_TstNPsdPwrUpSt_783 : 45|1@0+ (1,0) [0|1] ""  TestTool_FO
 SG_ DTCI_TstNPsdCdClrdSt_783 : 42|1@0+ (1,0) [0|1] ""  TestTool_FO
 SG_ DTCI_TstFldPwrUpSt_783 : 46|1@0+ (1,0) [0|1] ""  TestTool_FO
 SG_ DTCI_TstFldCdClrdStat_783 : 43|1@0+ (1,0) [0|1] ""  TestTool_FO
 SG_ DTCI_HistStat_783 : 44|1@0+ (1,0) [0|1] ""  TestTool_FO
 SG_ DTCI_DTCTriggered_783 : 0|1@0+ (1,0) [0|1] ""  TestTool_FO
 SG_ DTCI_DTCSource_783 : 15|8@0+ (1,0) [0|255] ""  TestTool_FO
 SG_ DTCI_DTCNumber_783 : 23|16@0+ (1,0) [0|65535] ""  TestTool_FO
 SG_ DTCI_DTCFaultType_783 : 55|8@0+ (1,0) [0|255] ""  TestTool_FO
 SG_ DTCI_DTCFailType_783 : 39|8@0+ (1,0) [0|255] ""  TestTool_FO
 SG_ DTCI_CurrentStatus_783 : 41|1@0+ (1,0) [0|1] ""  TestTool_FO
 SG_ DTCI_CodeSupported_783 : 40|1@0+ (1,0) [0|1] ""  TestTool_FO
 SG_ DTCIUnused7_783 : 1|1@0+ (1,0) [0|1] ""  TestTool_FO
 SG_ DTCIUnused6_783 : 2|1@0+ (1,0) [0|1] ""  TestTool_FO
 SG_ DTCIUnused5_783 : 3|1@0+ (1,0) [0|1] ""  TestTool_FO
 SG_ DTCIUnused4_783 : 4|1@0+ (1,0) [0|1] ""  TestTool_FO
 SG_ DTCIUnused3_783 : 5|1@0+ (1,0) [0|1] ""  TestTool_FO
 SG_ DTCIUnused2_783 : 6|1@0+ (1,0) [0|1] ""  TestTool_FO
 SG_ DTCIUnused1_783 : 7|1@0+ (1,0) [0|1] ""  TestTool_FO

BO_ 1924 DTC_Triggered_784_FO: 7 RRSRR_FO
 SG_ DTCI_HistStat_784 : 44|1@0+ (1,0) [0|1] ""  TestTool_FO
 SG_ DTCI_TstFldCdClrdStat_784 : 43|1@0+ (1,0) [0|1] ""  TestTool_FO
 SG_ DTCI_TstFldPwrUpSt_784 : 46|1@0+ (1,0) [0|1] ""  TestTool_FO
 SG_ DTCI_TstNPsdCdClrdSt_784 : 42|1@0+ (1,0) [0|1] ""  TestTool_FO
 SG_ DTCI_TstNPsdPwrUpSt_784 : 45|1@0+ (1,0) [0|1] ""  TestTool_FO
 SG_ DTCIUnused1_784 : 7|1@0+ (1,0) [0|1] ""  TestTool_FO
 SG_ DTCIUnused2_784 : 6|1@0+ (1,0) [0|1] ""  TestTool_FO
 SG_ DTCIUnused3_784 : 5|1@0+ (1,0) [0|1] ""  TestTool_FO
 SG_ DTCIUnused4_784 : 4|1@0+ (1,0) [0|1] ""  TestTool_FO
 SG_ DTCIUnused5_784 : 3|1@0+ (1,0) [0|1] ""  TestTool_FO
 SG_ DTCIUnused6_784 : 2|1@0+ (1,0) [0|1] ""  TestTool_FO
 SG_ DTCIUnused7_784 : 1|1@0+ (1,0) [0|1] ""  TestTool_FO
 SG_ DTCI_WrnIndRqdSt_784 : 47|1@0+ (1,0) [0|1] ""  TestTool_FO
 SG_ DTCI_CodeSupported_784 : 40|1@0+ (1,0) [0|1] ""  TestTool_FO
 SG_ DTCI_CurrentStatus_784 : 41|1@0+ (1,0) [0|1] ""  TestTool_FO
 SG_ DTCI_DTCFailType_784 : 39|8@0+ (1,0) [0|255] ""  TestTool_FO
 SG_ DTCI_DTCFaultType_784 : 55|8@0+ (1,0) [0|255] ""  TestTool_FO
 SG_ DTCI_DTCNumber_784 : 23|16@0+ (1,0) [0|65535] ""  TestTool_FO
 SG_ DTCI_DTCSource_784 : 15|8@0+ (1,0) [0|255] ""  TestTool_FO
 SG_ DTCI_DTCTriggered_784 : 0|1@0+ (1,0) [0|1] ""  TestTool_FO

BO_ 1922 DTC_Triggered_782_FO: 7 RFSRR_FO
 SG_ DTCI_WrnIndRqdSt_782 : 47|1@0+ (1,0) [0|1] ""  TestTool_FO
 SG_ DTCIUnused7_782 : 1|1@0+ (1,0) [0|1] ""  TestTool_FO
 SG_ DTCIUnused6_782 : 2|1@0+ (1,0) [0|1] ""  TestTool_FO
 SG_ DTCIUnused5_782 : 3|1@0+ (1,0) [0|1] ""  TestTool_FO
 SG_ DTCIUnused4_782 : 4|1@0+ (1,0) [0|1] ""  TestTool_FO
 SG_ DTCIUnused3_782 : 5|1@0+ (1,0) [0|1] ""  TestTool_FO
 SG_ DTCIUnused2_782 : 6|1@0+ (1,0) [0|1] ""  TestTool_FO
 SG_ DTCIUnused1_782 : 7|1@0+ (1,0) [0|1] ""  TestTool_FO
 SG_ DTCI_TstNPsdPwrUpSt_782 : 45|1@0+ (1,0) [0|1] ""  TestTool_FO
 SG_ DTCI_TstNPsdCdClrdSt_782 : 42|1@0+ (1,0) [0|1] ""  TestTool_FO
 SG_ DTCI_TstFldPwrUpSt_782 : 46|1@0+ (1,0) [0|1] ""  TestTool_FO
 SG_ DTCI_TstFldCdClrdStat_782 : 43|1@0+ (1,0) [0|1] ""  TestTool_FO
 SG_ DTCI_HistStat_782 : 44|1@0+ (1,0) [0|1] ""  TestTool_FO
 SG_ DTCI_DTCTriggered_782 : 0|1@0+ (1,0) [0|1] ""  TestTool_FO
 SG_ DTCI_DTCSource_782 : 15|8@0+ (1,0) [0|255] ""  TestTool_FO
 SG_ DTCI_DTCNumber_782 : 23|16@0+ (1,0) [0|65535] ""  TestTool_FO
 SG_ DTCI_DTCFaultType_782 : 55|8@0+ (1,0) [0|255] ""  TestTool_FO
 SG_ DTCI_DTCFailType_782 : 39|8@0+ (1,0) [0|255] ""  TestTool_FO
 SG_ DTCI_CurrentStatus_782 : 41|1@0+ (1,0) [0|1] ""  TestTool_FO
 SG_ DTCI_CodeSupported_782 : 40|1@0+ (1,0) [0|1] ""  TestTool_FO

BO_ 1920 DTC_Triggered_780_FO: 7 LRR_FO
 SG_ DTCI_CurrentStatus_780 : 41|1@0+ (1,0) [0|1] ""  TestTool_FO
 SG_ DTCI_WrnIndRqdSt_780 : 47|1@0+ (1,0) [0|1] ""  TestTool_FO
 SG_ DTCIUnused7_780 : 1|1@0+ (1,0) [0|1] ""  TestTool_FO
 SG_ DTCIUnused6_780 : 2|1@0+ (1,0) [0|1] ""  TestTool_FO
 SG_ DTCIUnused5_780 : 3|1@0+ (1,0) [0|1] ""  TestTool_FO
 SG_ DTCIUnused4_780 : 4|1@0+ (1,0) [0|1] ""  TestTool_FO
 SG_ DTCIUnused3_780 : 5|1@0+ (1,0) [0|1] ""  TestTool_FO
 SG_ DTCIUnused2_780 : 6|1@0+ (1,0) [0|1] ""  TestTool_FO
 SG_ DTCIUnused1_780 : 7|1@0+ (1,0) [0|1] ""  TestTool_FO
 SG_ DTCI_TstNPsdPwrUpSt_780 : 45|1@0+ (1,0) [0|1] ""  TestTool_FO
 SG_ DTCI_TstNPsdCdClrdSt_780 : 42|1@0+ (1,0) [0|1] ""  TestTool_FO
 SG_ DTCI_TstFldPwrUpSt_780 : 46|1@0+ (1,0) [0|1] ""  TestTool_FO
 SG_ DTCI_TstFldCdClrdStat_780 : 43|1@0+ (1,0) [0|1] ""  TestTool_FO
 SG_ DTCI_HistStat_780 : 44|1@0+ (1,0) [0|1] ""  TestTool_FO
 SG_ DTCI_DTCTriggered_780 : 0|1@0+ (1,0) [0|1] ""  TestTool_FO
 SG_ DTCI_DTCSource_780 : 15|8@0+ (1,0) [0|255] ""  TestTool_FO
 SG_ DTCI_DTCNumber_780 : 23|16@0+ (1,0) [0|65535] ""  TestTool_FO
 SG_ DTCI_DTCFaultType_780 : 55|8@0+ (1,0) [0|255] ""  TestTool_FO
 SG_ DTCI_DTCFailType_780 : 39|8@0+ (1,0) [0|255] ""  TestTool_FO
 SG_ DTCI_CodeSupported_780 : 40|1@0+ (1,0) [0|1] ""  TestTool_FO

BO_ 1921 DTC_Triggered_781_FO: 7 LFSRR_FO
 SG_ DTCI_CurrentStatus_781 : 41|1@0+ (1,0) [0|1] ""  TestTool_FO
 SG_ DTCI_WrnIndRqdSt_781 : 47|1@0+ (1,0) [0|1] ""  TestTool_FO
 SG_ DTCIUnused7_781 : 1|1@0+ (1,0) [0|1] ""  TestTool_FO
 SG_ DTCIUnused6_781 : 2|1@0+ (1,0) [0|1] ""  TestTool_FO
 SG_ DTCIUnused5_781 : 3|1@0+ (1,0) [0|1] ""  TestTool_FO
 SG_ DTCIUnused4_781 : 4|1@0+ (1,0) [0|1] ""  TestTool_FO
 SG_ DTCIUnused3_781 : 5|1@0+ (1,0) [0|1] ""  TestTool_FO
 SG_ DTCIUnused2_781 : 6|1@0+ (1,0) [0|1] ""  TestTool_FO
 SG_ DTCIUnused1_781 : 7|1@0+ (1,0) [0|1] ""  TestTool_FO
 SG_ DTCI_TstNPsdPwrUpSt_781 : 45|1@0+ (1,0) [0|1] ""  TestTool_FO
 SG_ DTCI_TstNPsdCdClrdSt_781 : 42|1@0+ (1,0) [0|1] ""  TestTool_FO
 SG_ DTCI_TstFldPwrUpSt_781 : 46|1@0+ (1,0) [0|1] ""  TestTool_FO
 SG_ DTCI_TstFldCdClrdStat_781 : 43|1@0+ (1,0) [0|1] ""  TestTool_FO
 SG_ DTCI_HistStat_781 : 44|1@0+ (1,0) [0|1] ""  TestTool_FO
 SG_ DTCI_DTCTriggered_781 : 0|1@0+ (1,0) [0|1] ""  TestTool_FO
 SG_ DTCI_DTCSource_781 : 15|8@0+ (1,0) [0|255] ""  TestTool_FO
 SG_ DTCI_DTCNumber_781 : 23|16@0+ (1,0) [0|65535] ""  TestTool_FO
 SG_ DTCI_DTCFaultType_781 : 55|8@0+ (1,0) [0|255] ""  TestTool_FO
 SG_ DTCI_DTCFailType_781 : 39|8@0+ (1,0) [0|255] ""  TestTool_FO
 SG_ DTCI_CodeSupported_781 : 40|1@0+ (1,0) [0|1] ""  TestTool_FO

BO_ 1034 Curvature_Right_Line_FO: 7 VIS2_FO
 SG_ CRL_Cnfdnc : 50|3@0+ (1,0) [0|7] ""  EOCM2A_IMX6_FO,EOCM2A_K2_FO,EOCM2A_K1_FO,EOCM_F_FO,EOCM2B_IMX6_FO,EOCM2B_K2_FO,EOCM2B_K1_FO
 SG_ CRL_ViewRng : 33|15@0+ (0.0039064,0) [0|128.0010088] "m"  EOCM2A_IMX6_FO,EOCM2A_K2_FO,EOCM2A_K1_FO,EOCM_F_FO,EOCM2B_IMX6_FO,EOCM2B_K2_FO,EOCM2B_K1_FO
 SG_ CRL_CoefdA : 17|16@0- (3.6622E-009,0) [-0.0001200029696|0.0001199993074] "1/m^2"  EOCM2A_IMX6_FO,EOCM2A_K2_FO,EOCM2A_K1_FO,EOCM_F_FO,EOCM2B_IMX6_FO,EOCM2B_K2_FO,EOCM2B_K1_FO
 SG_ CRL_CoefA : 1|16@0- (6.1036E-007,0) [-0.02000027648|0.01999966612] "1/m"  EOCM2A_IMX6_FO,EOCM2A_K2_FO,EOCM2A_K1_FO,EOCM_F_FO,EOCM2B_IMX6_FO,EOCM2B_K2_FO,EOCM2B_K1_FO

BO_ 1033 Curvature_Left_Line_FO: 7 VIS2_FO
 SG_ CLL_Cnfdnc : 50|3@0+ (1,0) [0|7] ""  EOCM2A_IMX6_FO,EOCM2A_K2_FO,EOCM2A_K1_FO,EOCM_F_FO,EOCM2B_IMX6_FO,EOCM2B_K2_FO,EOCM2B_K1_FO
 SG_ CLL_ViewRng : 33|15@0+ (0.0039064,0) [0|128.0010088] "m"  EOCM2A_IMX6_FO,EOCM2A_K2_FO,EOCM2A_K1_FO,EOCM_F_FO,EOCM2B_IMX6_FO,EOCM2B_K2_FO,EOCM2B_K1_FO
 SG_ CLL_CoefdA : 17|16@0- (3.6622E-009,0) [-0.0001200029696|0.0001199993074] "1/m^2"  EOCM2A_IMX6_FO,EOCM2A_K2_FO,EOCM2A_K1_FO,EOCM_F_FO,EOCM2B_IMX6_FO,EOCM2B_K2_FO,EOCM2B_K1_FO
 SG_ CLL_CoefA : 1|16@0- (6.1036E-007,0) [-0.02000027648|0.01999966612] "1/m"  EOCM2A_IMX6_FO,EOCM2A_K2_FO,EOCM2A_K1_FO,EOCM_F_FO,EOCM2B_IMX6_FO,EOCM2B_K2_FO,EOCM2B_K1_FO

BO_ 1365 UUDT_Resp_From_VIS2_FO: 8 VIS2_FO
 SG_ DgnInf_OBJ555 : 7|64@0+ (1,0) [0|1.84467440737096E+019] ""  TestTool_FO

BO_ 1621 USDT_Resp_From_VIS2_FO: 8 VIS2_FO
 SG_ DgnInf_OBJ655 : 7|64@0+ (1,0) [0|1.84467440737096E+019] ""  TestTool_FO

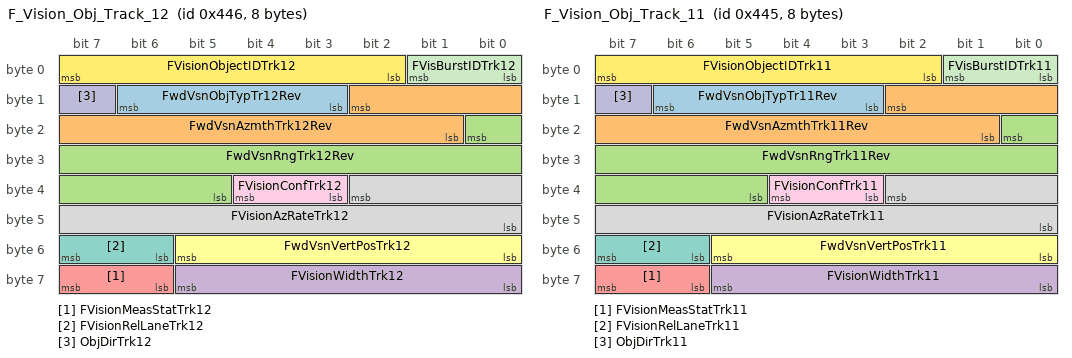
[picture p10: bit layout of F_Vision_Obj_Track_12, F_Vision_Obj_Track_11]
BO_ 1094 F_Vision_Obj_Track_12: 8 VIS2_FO
 SG_ FwdVsnObjTypTr12Rev : 14|4@0+ (1,0) [0|15] ""  EOCM_F_FO
 SG_ FwdVsnAzmthTrk12Rev : 10|10@0- (0.1,0) [-51.2|51.1] "deg"  EOCM_F_FO
 SG_ FwdVsnRngTrk12Rev : 16|12@0+ (0.1,0) [0|409.5] "m"  EOCM_F_FO
 SG_ FVisionWidthTrk12 : 61|6@0+ (0.25,0) [0|15.75] "m"  EOCM_F_FO
 SG_ FVisionMeasStatTrk12 : 63|2@0+ (1,0) [0|3] ""  EOCM_F_FO
 SG_ FwdVsnVertPosTrk12 : 53|6@0+ (0.25,-2) [-2|13.75] "deg"  EOCM_F_FO
 SG_ FVisionRelLaneTrk12 : 55|2@0+ (1,0) [0|3] ""  EOCM_F_FO
 SG_ FVisionAzRateTrk12 : 34|11@0- (0.125,0) [-128|127.875] "deg/sec"  EOCM_F_FO
 SG_ FVisionConfTrk12 : 36|2@0+ (1,0) [0|3] ""  EOCM_F_FO
 SG_ ObjDirTrk12 : 15|1@0+ (1,0) [0|1] ""  EOCM_F_FO
 SG_ FVisBurstIDTrk12 : 1|2@0+ (1,0) [0|3] ""  EOCM_F_FO
 SG_ FVisionObjectIDTrk12 : 7|6@0+ (1,0) [0|63] ""  EOCM_F_FO

BO_ 1093 F_Vision_Obj_Track_11: 8 VIS2_FO
 SG_ FwdVsnObjTypTr11Rev : 14|4@0+ (1,0) [0|15] ""  EOCM_F_FO
 SG_ FwdVsnAzmthTrk11Rev : 10|10@0- (0.1,0) [-51.2|51.1] "deg"  EOCM_F_FO
 SG_ FwdVsnRngTrk11Rev : 16|12@0+ (0.1,0) [0|409.5] "m"  EOCM_F_FO
 SG_ FVisionWidthTrk11 : 61|6@0+ (0.25,0) [0|15.75] "m"  EOCM_F_FO
 SG_ FVisionMeasStatTrk11 : 63|2@0+ (1,0) [0|3] ""  EOCM_F_FO
 SG_ FwdVsnVertPosTrk11 : 53|6@0+ (0.25,-2) [-2|13.75] "deg"  EOCM_F_FO
 SG_ FVisionRelLaneTrk11 : 55|2@0+ (1,0) [0|3] ""  EOCM_F_FO
 SG_ FVisionAzRateTrk11 : 34|11@0- (0.125,0) [-128|127.875] "deg/sec"  EOCM_F_FO
 SG_ FVisionConfTrk11 : 36|2@0+ (1,0) [0|3] ""  EOCM_F_FO
 SG_ ObjDirTrk11 : 15|1@0+ (1,0) [0|1] ""  EOCM_F_FO
 SG_ FVisBurstIDTrk11 : 1|2@0+ (1,0) [0|3] ""  EOCM_F_FO
 SG_ FVisionObjectIDTrk11 : 7|6@0+ (1,0) [0|63] ""  EOCM_F_FO

BO_ 1100 F_Vision_Obj_Track_12_B: 8 VIS2_FO
 SG_ FwVsnCinCoutPotT12Rev : 5|2@0+ (1,0) [0|3] ""  EOCM_F_FO
 SG_ FwdVsnObjAgeTrk12 : 62|7@0+ (1,0) [0|127] ""  EOCM_F_FO
 SG_ FwdVsnLongVlctyTrk12 : 42|12@0- (0.0625,0) [-128|127.9375] "m/sec"  EOCM_F_FO
 SG_ FwdVsnLatOfstTrk12 : 36|10@0- (0.125,0) [-64|63.875] "m"  EOCM_F_FO
 SG_ FwdVsnBrkLtStatTrk12 : 38|2@0+ (1,0) [0|3] ""  EOCM_F_FO
 SG_ FwdVsnTrnSigStatTr12 : 25|3@0+ (1,0) [0|7] ""  EOCM_F_FO
 SG_ FwdVsnObjSclChgTrk12 : 15|16@0- (0.0002,0) [-6.5536|6.5534] "pix/sec"  EOCM_F_FO
 SG_ FrtVsnBrstIDAddInfo12 : 7|2@0+ (1,0) [0|3] ""  EOCM_F_FO

BO_ 1099 F_Vision_Obj_Track_11_B: 8 VIS2_FO
 SG_ FwVsnCinCoutPotT11Rev : 5|2@0+ (1,0) [0|3] ""  EOCM_F_FO
 SG_ FwdVsnObjAgeTrk11 : 62|7@0+ (1,0) [0|127] ""  EOCM_F_FO
 SG_ FwdVsnLongVlctyTrk11 : 42|12@0- (0.0625,0) [-128|127.9375] "m/sec"  EOCM_F_FO
 SG_ FwdVsnLatOfstTrk11 : 36|10@0- (0.125,0) [-64|63.875] "m"  EOCM_F_FO
 SG_ FwdVsnBrkLtStatTrk11 : 38|2@0+ (1,0) [0|3] ""  EOCM_F_FO
 SG_ FwdVsnTrnSigStatTr11 : 25|3@0+ (1,0) [0|7] ""  EOCM_F_FO
 SG_ FwdVsnObjSclChgTrk11 : 15|16@0- (0.0002,0) [-6.5536|6.5534] "pix/sec"  EOCM_F_FO
 SG_ FrtVsnBrstIDAddInfo11 : 7|2@0+ (1,0) [0|3] ""  EOCM_F_FO

BO_ 1098 F_Vision_Obj_Track_10_B: 8 VIS2_FO
 SG_ FwVsnCinCoutPotT10Rev : 5|2@0+ (1,0) [0|3] ""  EOCM_F_FO
 SG_ FwdVsnObjAgeTrk10 : 62|7@0+ (1,0) [0|127] ""  EOCM_F_FO
 SG_ FwdVsnLongVlctyTrk10 : 42|12@0- (0.0625,0) [-128|127.9375] "m/sec"  EOCM_F_FO
 SG_ FwdVsnLatOfstTrk10 : 36|10@0- (0.125,0) [-64|63.875] "m"  EOCM_F_FO
 SG_ FwdVsnBrkLtStatTrk10 : 38|2@0+ (1,0) [0|3] ""  EOCM_F_FO
 SG_ FwdVsnTrnSigStatTr10 : 25|3@0+ (1,0) [0|7] ""  EOCM_F_FO
 SG_ FwdVsnObjSclChgTrk10 : 15|16@0- (0.0002,0) [-6.5536|6.5534] "pix/sec"  EOCM_F_FO
 SG_ FrtVsnBrstIDAddInfo10 : 7|2@0+ (1,0) [0|3] ""  EOCM_F_FO

BO_ 1097 F_Vision_Obj_Track_9_B: 8 VIS2_FO
 SG_ FwVsnCinCoutPotT9Rev : 5|2@0+ (1,0) [0|3] ""  EOCM_F_FO
 SG_ FwdVsnObjAgeTrk9 : 62|7@0+ (1,0) [0|127] ""  EOCM_F_FO
 SG_ FwdVsnLongVlctyTrk9 : 42|12@0- (0.0625,0) [-128|127.9375] "m/sec"  EOCM_F_FO
 SG_ FwdVsnLatOfstTrk9 : 36|10@0- (0.125,0) [-64|63.875] "m"  EOCM_F_FO
 SG_ FwdVsnBrkLtStatTrk9 : 38|2@0+ (1,0) [0|3] ""  EOCM_F_FO
 SG_ FwdVsnTrnSigStatTr9 : 25|3@0+ (1,0) [0|7] ""  EOCM_F_FO
 SG_ FwdVsnObjSclChgTrk9 : 15|16@0- (0.0002,0) [-6.5536|6.5534] "pix/sec"  EOCM_F_FO
 SG_ FrtVsnBrstIDAddInfo9 : 7|2@0+ (1,0) [0|3] ""  EOCM_F_FO

BO_ 1096 F_Vision_Obj_Track_8_B: 8 VIS2_FO
 SG_ FwVsnCinCoutPotT8Rev : 5|2@0+ (1,0) [0|3] ""  EOCM_F_FO
 SG_ FwdVsnObjAgeTrk8 : 62|7@0+ (1,0) [0|127] ""  EOCM_F_FO
 SG_ FwdVsnLongVlctyTrk8 : 42|12@0- (0.0625,0) [-128|127.9375] "m/sec"  EOCM_F_FO
 SG_ FwdVsnLatOfstTrk8 : 36|10@0- (0.125,0) [-64|63.875] "m"  EOCM_F_FO
 SG_ FwdVsnBrkLtStatTrk8 : 38|2@0+ (1,0) [0|3] ""  EOCM_F_FO
 SG_ FwdVsnTrnSigStatTr8 : 25|3@0+ (1,0) [0|7] ""  EOCM_F_FO
 SG_ FwdVsnObjSclChgTrk8 : 15|16@0- (0.0002,0) [-6.5536|6.5534] "pix/sec"  EOCM_F_FO
 SG_ FrtVsnBrstIDAddInfo8 : 7|2@0+ (1,0) [0|3] ""  EOCM_F_FO

BO_ 1095 F_Vision_Obj_Track_7_B: 8 VIS2_FO
 SG_ FwVsnCinCoutPotT7Rev : 5|2@0+ (1,0) [0|3] ""  EOCM_F_FO
 SG_ FwdVsnObjAgeTrk7 : 62|7@0+ (1,0) [0|127] ""  EOCM_F_FO
 SG_ FwdVsnLongVlctyTrk7 : 42|12@0- (0.0625,0) [-128|127.9375] "m/sec"  EOCM_F_FO
 SG_ FwdVsnLatOfstTrk7 : 36|10@0- (0.125,0) [-64|63.875] "m"  EOCM_F_FO
 SG_ FwdVsnBrkLtStatTrk7 : 38|2@0+ (1,0) [0|3] ""  EOCM_F_FO
 SG_ FwdVsnTrnSigStatTr7 : 25|3@0+ (1,0) [0|7] ""  EOCM_F_FO
 SG_ FwdVsnObjSclChgTrk7 : 15|16@0- (0.0002,0) [-6.5536|6.5534] "pix/sec"  EOCM_F_FO
 SG_ FrtVsnBrstIDAddInfo7 : 7|2@0+ (1,0) [0|3] ""  EOCM_F_FO

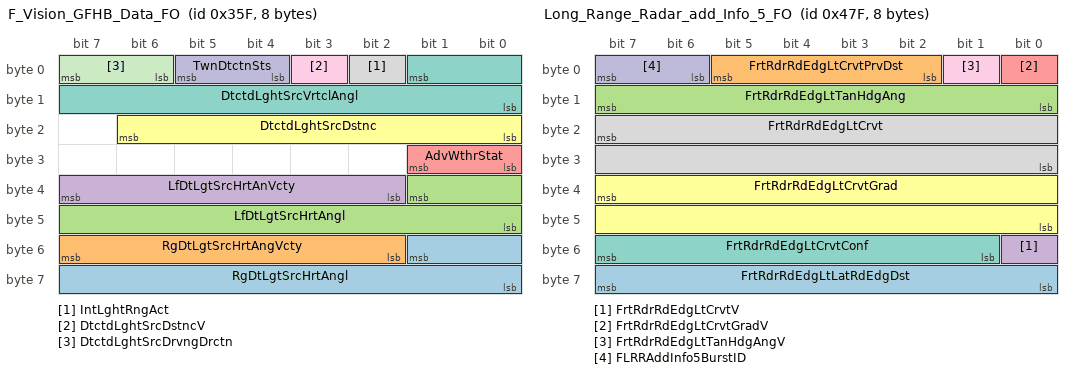
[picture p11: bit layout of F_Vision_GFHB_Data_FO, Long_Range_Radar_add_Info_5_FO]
BO_ 863 F_Vision_GFHB_Data_FO: 8 VIS2_FO
 SG_ RgDtLgtSrcHrtAngl : 49|10@0- (0.04,0) [-20.48|20.44] "deg"  EOCM_F_FO
 SG_ RgDtLgtSrcHrtAngVcty : 55|6@0- (1,0) [-32|31] "deg/sec"  EOCM_F_FO
 SG_ LfDtLgtSrcHrtAngl : 33|10@0- (0.04,0) [-20.48|20.44] "deg"  EOCM_F_FO
 SG_ LfDtLgtSrcHrtAnVcty : 39|6@0- (1,0) [-32|31] "deg/sec"  EOCM_F_FO
 SG_ AdvWthrStat : 25|2@0+ (1,0) [0|3] ""  EOCM_F_FO
 SG_ DtctdLghtSrcDstnc : 22|7@0+ (10,0) [0|1270] "m"  EOCM_F_FO
 SG_ DtctdLghtSrcVrtclAngl : 1|10@0- (0.04,0) [-20.48|20.44] "deg"  EOCM_F_FO
 SG_ IntLghtRngAct : 2|1@0+ (1,0) [0|1] ""  EOCM_F_FO
 SG_ DtctdLghtSrcDstncV : 3|1@0+ (1,0) [0|1] ""  EOCM_F_FO
 SG_ TwnDtctnSts : 5|2@0+ (1,0) [0|3] ""  EOCM_F_FO
 SG_ DtctdLghtSrcDrvngDrctn : 7|2@0+ (1,0) [0|3] ""  EOCM_F_FO

BO_ 862 LGT_ControlHighBeamGlare_FO: 2 VIS2_FO
 SG_ FwdCamSysOpStat : 10|3@0+ (1,0) [0|7] ""  EOCM_F_FO
 SG_ EnvIllum : 2|3@0+ (1,0) [0|7] ""  EOCM_F_FO
 SG_ RdTyp : 5|3@0+ (1,0) [0|7] ""  EOCM_F_FO
 SG_ AutoHgBmSts : 7|2@0+ (1,0) [0|3] ""  EOCM_F_FO

BO_ 1068 F_Vision_Obj_Track_6_B: 8 VIS2_FO
 SG_ FwVsnCinCoutPotT6Rev : 5|2@0+ (1,0) [0|3] ""  EOCM_F_FO
 SG_ FwdVsnObjAgeTrk6 : 62|7@0+ (1,0) [0|127] ""  EOCM_F_FO
 SG_ FwdVsnLongVlctyTrk6 : 42|12@0- (0.0625,0) [-128|127.9375] "m/sec"  EOCM_F_FO
 SG_ FwdVsnLatOfstTrk6 : 36|10@0- (0.125,0) [-64|63.875] "m"  EOCM_F_FO
 SG_ FwdVsnBrkLtStatTrk6 : 38|2@0+ (1,0) [0|3] ""  EOCM_F_FO
 SG_ FwdVsnTrnSigStatTr6 : 25|3@0+ (1,0) [0|7] ""  EOCM_F_FO
 SG_ FwdVsnObjSclChgTrk6 : 15|16@0- (0.0002,0) [-6.5536|6.5534] "pix/sec"  EOCM_F_FO
 SG_ FrtVsnBrstIDAddInfo6 : 7|2@0+ (1,0) [0|3] ""  EOCM_F_FO

BO_ 1067 F_Vision_Obj_Track_5_B: 8 VIS2_FO
 SG_ FwVsnCinCoutPotT5Rev : 5|2@0+ (1,0) [0|3] ""  EOCM_F_FO
 SG_ FwdVsnObjAgeTrk5 : 62|7@0+ (1,0) [0|127] ""  EOCM_F_FO
 SG_ FwdVsnLongVlctyTrk5 : 42|12@0- (0.0625,0) [-128|127.9375] "m/sec"  EOCM_F_FO
 SG_ FwdVsnLatOfstTrk5 : 36|10@0- (0.125,0) [-64|63.875] "m"  EOCM_F_FO
 SG_ FwdVsnBrkLtStatTrk5 : 38|2@0+ (1,0) [0|3] ""  EOCM_F_FO
 SG_ FwdVsnTrnSigStatTr5 : 25|3@0+ (1,0) [0|7] ""  EOCM_F_FO
 SG_ FwdVsnObjSclChgTrk5 : 15|16@0- (0.0002,0) [-6.5536|6.5534] "pix/sec"  EOCM_F_FO
 SG_ FrtVsnBrstIDAddInfo5 : 7|2@0+ (1,0) [0|3] ""  EOCM_F_FO

BO_ 1066 F_Vision_Obj_Track_4_B: 8 VIS2_FO
 SG_ FwVsnCinCoutPotT4Rev : 5|2@0+ (1,0) [0|3] ""  EOCM_F_FO
 SG_ FwdVsnObjAgeTrk4 : 62|7@0+ (1,0) [0|127] ""  EOCM_F_FO
 SG_ FwdVsnLongVlctyTrk4 : 42|12@0- (0.0625,0) [-128|127.9375] "m/sec"  EOCM_F_FO
 SG_ FwdVsnLatOfstTrk4 : 36|10@0- (0.125,0) [-64|63.875] "m"  EOCM_F_FO
 SG_ FwdVsnBrkLtStatTrk4 : 38|2@0+ (1,0) [0|3] ""  EOCM_F_FO
 SG_ FwdVsnTrnSigStatTr4 : 25|3@0+ (1,0) [0|7] ""  EOCM_F_FO
 SG_ FwdVsnObjSclChgTrk4 : 15|16@0- (0.0002,0) [-6.5536|6.5534] "pix/sec"  EOCM_F_FO
 SG_ FrtVsnBrstIDAddInfo4 : 7|2@0+ (1,0) [0|3] ""  EOCM_F_FO

BO_ 1065 F_Vision_Obj_Track_3_B: 8 VIS2_FO
 SG_ FwVsnCinCoutPotT3Rev : 5|2@0+ (1,0) [0|3] ""  EOCM_F_FO
 SG_ FwdVsnObjAgeTrk3 : 62|7@0+ (1,0) [0|127] ""  EOCM_F_FO
 SG_ FwdVsnLongVlctyTrk3 : 42|12@0- (0.0625,0) [-128|127.9375] "m/sec"  EOCM_F_FO
 SG_ FwdVsnLatOfstTrk3 : 36|10@0- (0.125,0) [-64|63.875] "m"  EOCM_F_FO
 SG_ FwdVsnBrkLtStatTrk3 : 38|2@0+ (1,0) [0|3] ""  EOCM_F_FO
 SG_ FwdVsnTrnSigStatTr3 : 25|3@0+ (1,0) [0|7] ""  EOCM_F_FO
 SG_ FwdVsnObjSclChgTrk3 : 15|16@0- (0.0002,0) [-6.5536|6.5534] "pix/sec"  EOCM_F_FO
 SG_ FrtVsnBrstIDAddInfo3 : 7|2@0+ (1,0) [0|3] ""  EOCM_F_FO

BO_ 1064 F_Vision_Obj_Track_2_B: 8 VIS2_FO
 SG_ FwVsnCinCoutPotT2Rev : 5|2@0+ (1,0) [0|3] ""  EOCM_F_FO
 SG_ FwdVsnObjAgeTrk2 : 62|7@0+ (1,0) [0|127] ""  EOCM_F_FO
 SG_ FwdVsnLongVlctyTrk2 : 42|12@0- (0.0625,0) [-128|127.9375] "m/sec"  EOCM_F_FO
 SG_ FwdVsnLatOfstTrk2 : 36|10@0- (0.125,0) [-64|63.875] "m"  EOCM_F_FO
 SG_ FwdVsnBrkLtStatTrk2 : 38|2@0+ (1,0) [0|3] ""  EOCM_F_FO
 SG_ FwdVsnTrnSigStatTr2 : 25|3@0+ (1,0) [0|7] ""  EOCM_F_FO
 SG_ FwdVsnObjSclChgTrk2 : 15|16@0- (0.0002,0) [-6.5536|6.5534] "pix/sec"  EOCM_F_FO
 SG_ FrtVsnBrstIDAddInfo2 : 7|2@0+ (1,0) [0|3] ""  EOCM_F_FO

BO_ 1063 F_Vision_Obj_Track_1_B: 8 VIS2_FO
 SG_ FwVsnCinCoutPotT1Rev : 5|2@0+ (1,0) [0|3] ""  EOCM_F_FO
 SG_ FwdVsnObjSclChgTrk1 : 15|16@0- (0.0002,0) [-6.5536|6.5534] "pix/sec"  EOCM_F_FO
 SG_ FwdVsnObjAgeTrk1 : 62|7@0+ (1,0) [0|127] ""  EOCM_F_FO
 SG_ FwdVsnLongVlctyTrk1 : 42|12@0- (0.0625,0) [-128|127.9375] "m/sec"  EOCM_F_FO
 SG_ FwdVsnLatOfstTrk1 : 36|10@0- (0.125,0) [-64|63.875] "m"  EOCM_F_FO
 SG_ FwdVsnBrkLtStatTrk1 : 38|2@0+ (1,0) [0|3] ""  EOCM_F_FO
 SG_ FwdVsnTrnSigStatTr1 : 25|3@0+ (1,0) [0|7] ""  EOCM_F_FO
 SG_ FrtVsnBrstIDAddInfo1 : 7|2@0+ (1,0) [0|3] ""  EOCM_F_FO

BO_ 1151 Long_Range_Radar_add_Info_5_FO: 8 LRR_FO
 SG_ FrtRdrRdEdgLtLatRdEdgDst : 63|8@0- (0.1,0) [-12.8|12.7] "m/m"  EOCM_F_FO
 SG_ FrtRdrRdEdgLtCrvtPrvDst : 5|4@0+ (10,0) [0|150] ""  EOCM_F_FO
 SG_ FrtRdrRdEdgLtTanHdgAng : 15|8@0- (0.002,0) [-0.256|0.254] "m/m"  EOCM_F_FO
 SG_ FrtRdrRdEdgLtCrvtV : 48|1@0+ (1,0) [0|1] ""  EOCM_F_FO
 SG_ FrtRdrRdEdgLtCrvtGradV : 0|1@0+ (1,0) [0|1] ""  EOCM_F_FO
 SG_ FrtRdrRdEdgLtCrvtGrad : 39|16@0- (5.96E-008,0) [-0.0019529728|0.0019529132] "1/(m*sec)"  EOCM_F_FO
 SG_ FrtRdrRdEdgLtCrvtConf : 55|7@0+ (0.7874016,0) [0|100.0000032] "%"  EOCM_F_FO
 SG_ FrtRdrRdEdgLtCrvt : 23|16@0- (9.53E-007,0) [-0.031227904|0.031226951] "1/m"  EOCM_F_FO
 SG_ FrtRdrRdEdgLtTanHdgAngV : 1|1@0+ (1,0) [0|1] ""  EOCM_F_FO
 SG_ FLRRAddInfo5BurstID : 7|2@0+ (1,0) [0|3] ""  EOCM_F_FO

BO_ 1150 Long_Range_Radar_add_Info_4_FO: 8 LRR_FO
 SG_ FrtRdrRdEdgRtLatRdEdgDst : 63|8@0- (0.1,0) [-12.8|12.7] "m/m"  EOCM_F_FO
 SG_ FrtRdrRdEdgRtCrvtPrvDst : 5|4@0+ (10,0) [0|150] ""  EOCM_F_FO
 SG_ FrtRdrRdEdgRtTanHdgAngV : 1|1@0+ (1,0) [0|1] ""  EOCM_F_FO
 SG_ FrtRdrRdEdgRtTanHdgAng : 15|8@0- (0.002,0) [-0.256|0.254] "m/m"  EOCM_F_FO
 SG_ FrtRdrRdEdgRtCrvtV : 48|1@0+ (1,0) [0|1] ""  EOCM_F_FO
 SG_ FrtRdrRdEdgRtCrvtGradV : 0|1@0+ (1,0) [0|1] ""  EOCM_F_FO
 SG_ FrtRdrRdEdgRtCrvtGrad : 39|16@0- (5.96E-008,0) [-0.0019529728|0.0019529132] "1/(m*sec)"  EOCM_F_FO
 SG_ FrtRdrRdEdgRtCrvtConf : 55|7@0+ (0.7874016,0) [0|100.0000032] "%"  EOCM_F_FO
 SG_ FrtRdrRdEdgRtCrvt : 23|16@0- (9.53E-007,0) [-0.031227904|0.031226951] "1/m"  EOCM_F_FO
 SG_ FLRRAddInfo4BurstID : 7|2@0+ (1,0) [0|3] ""  EOCM_F_FO

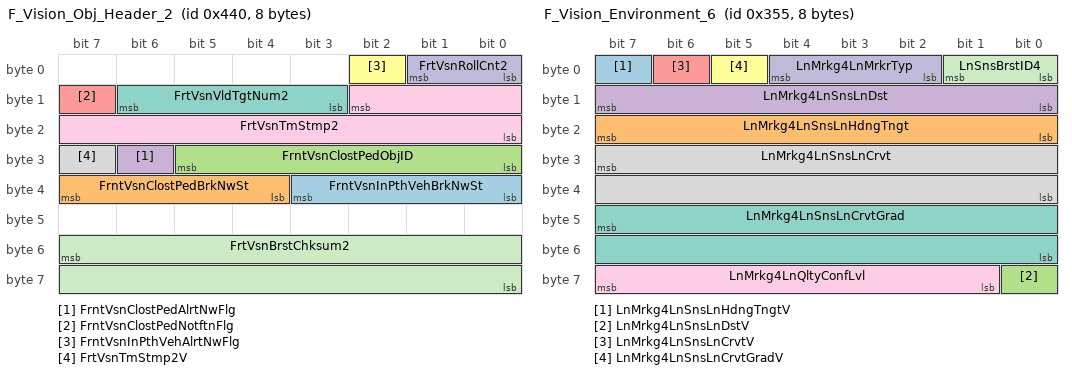
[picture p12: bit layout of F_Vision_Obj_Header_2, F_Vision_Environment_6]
BO_ 1088 F_Vision_Obj_Header_2: 8 VIS2_FO
 SG_ FrntVsnInPthVehBrkNwSt : 35|4@0+ (1,0) [0|15] ""  EOCM_F_FO
 SG_ FrntVsnClostPedBrkNwSt : 39|4@0+ (1,0) [0|15] ""  EOCM_F_FO
 SG_ FrntVsnClostPedObjID : 29|6@0+ (1,0) [0|63] ""  EOCM_F_FO
 SG_ FrntVsnClostPedAlrtNwFlg : 30|1@0+ (1,0) [0|1] ""  EOCM_F_FO
 SG_ FrntVsnClostPedNotftnFlg : 15|1@0+ (1,0) [0|1] ""  EOCM_F_FO
 SG_ FrntVsnInPthVehAlrtNwFlg : 2|1@0+ (1,0) [0|1] ""  EOCM_F_FO
 SG_ FrtVsnVldTgtNum2 : 14|4@0+ (1,0) [0|15] ""  EOCM_F_FO
 SG_ FrtVsnTmStmp2V : 31|1@0+ (1,0) [0|1] ""  EOCM_F_FO
 SG_ FrtVsnTmStmp2 : 10|11@0+ (1,0) [0|2047] ""  EOCM_F_FO
 SG_ FrtVsnRollCnt2 : 1|2@0+ (1,0) [0|3] ""  EOCM_F_FO
 SG_ FrtVsnBrstChksum2 : 55|16@0+ (1,0) [0|65535] ""  EOCM_F_FO

BO_ 854 F_Vision_Environment_7: 3 VIS2_FO
 SG_ FwdVsnCnstrctAreaDst : 13|4@0+ (10,0) [0|150] "m"  EOCM2A_IMX6_FO,EOCM2A_K2_FO,EOCM2A_K1_FO,EOCM2B_IMX6_FO,EOCM2B_K2_FO,EOCM2B_K1_FO,EOCM_F_FO
 SG_ FwdVsnCnstrctZnDet : 15|2@0+ (1,0) [0|3] ""  EOCM2A_IMX6_FO,EOCM2A_K2_FO,EOCM2A_K1_FO,EOCM2B_IMX6_FO,EOCM2B_K2_FO,EOCM2B_K1_FO,EOCM_F_FO
 SG_ FwdVsnEgoVehLnPos : 17|2@0+ (1,0) [0|3] ""  EOCM2A_IMX6_FO,EOCM2A_K2_FO,EOCM2A_K1_FO,EOCM2B_IMX6_FO,EOCM2B_K2_FO,EOCM2B_K1_FO,EOCM_F_FO
 SG_ FwdVsnRdTypDet : 9|2@0+ (1,0) [0|3] ""  EOCM2A_IMX6_FO,EOCM2A_K2_FO,EOCM2A_K1_FO,EOCM2B_IMX6_FO,EOCM2B_K2_FO,EOCM2B_K1_FO,EOCM_F_FO
 SG_ FwdVsnTunnlDetd : 23|2@0+ (1,0) [0|3] ""  EOCM2A_IMX6_FO,EOCM2A_K2_FO,EOCM2A_K1_FO,EOCM2B_IMX6_FO,EOCM2B_K2_FO,EOCM2B_K1_FO,EOCM_F_FO
 SG_ FwdVsnTunnlDst : 21|4@0+ (10,0) [0|150] "m"  EOCM2A_IMX6_FO,EOCM2A_K2_FO,EOCM2A_K1_FO,EOCM2B_IMX6_FO,EOCM2B_K2_FO,EOCM2B_K1_FO,EOCM_F_FO
 SG_ LnSnsBrstID5 : 1|2@0+ (1,0) [0|3] ""  EOCM2A_IMX6_FO,EOCM2A_K2_FO,EOCM2A_K1_FO,EOCM2B_IMX6_FO,EOCM2B_K2_FO,EOCM2B_K1_FO,EOCM_F_FO

BO_ 853 F_Vision_Environment_6: 8 VIS2_FO
 SG_ LnMrkg4LnSnsLnHdngTngtV : 7|1@0+ (1,0) [0|1] ""  EOCM2A_IMX6_FO,EOCM2A_K2_FO,EOCM2A_K1_FO,EOCM2B_IMX6_FO,EOCM2B_K2_FO,EOCM2B_K1_FO,EOCM_F_FO
 SG_ LnMrkg4LnSnsLnHdngTngt : 23|8@0- (0.002,0) [-0.256|0.254] "m/m"  EOCM2A_IMX6_FO,EOCM2A_K2_FO,EOCM2A_K1_FO,EOCM2B_IMX6_FO,EOCM2B_K2_FO,EOCM2B_K1_FO,EOCM_F_FO
 SG_ LnMrkg4LnSnsLnDstV : 56|1@0+ (1,0) [0|1] ""  EOCM2A_IMX6_FO,EOCM2A_K2_FO,EOCM2A_K1_FO,EOCM2B_IMX6_FO,EOCM2B_K2_FO,EOCM2B_K1_FO,EOCM_F_FO
 SG_ LnMrkg4LnSnsLnDst : 15|8@0- (0.1,0) [-12.8|12.7] "m"  EOCM2A_IMX6_FO,EOCM2A_K2_FO,EOCM2A_K1_FO,EOCM2B_IMX6_FO,EOCM2B_K2_FO,EOCM2B_K1_FO,EOCM_F_FO
 SG_ LnMrkg4LnSnsLnCrvtV : 6|1@0+ (1,0) [0|1] ""  EOCM2A_IMX6_FO,EOCM2A_K2_FO,EOCM2A_K1_FO,EOCM2B_IMX6_FO,EOCM2B_K2_FO,EOCM2B_K1_FO,EOCM_F_FO
 SG_ LnMrkg4LnSnsLnCrvtGradV : 5|1@0+ (1,0) [0|1] ""  EOCM2A_IMX6_FO,EOCM2A_K2_FO,EOCM2A_K1_FO,EOCM2B_IMX6_FO,EOCM2B_K2_FO,EOCM2B_K1_FO,EOCM_F_FO
 SG_ LnMrkg4LnSnsLnCrvtGrad : 47|16@0- (5.96E-008,0) [-0.0019529728|0.0019529132] "1/(m*sec)"  EOCM2A_IMX6_FO,EOCM2A_K2_FO,EOCM2A_K1_FO,EOCM2B_IMX6_FO,EOCM2B_K2_FO,EOCM2B_K1_FO,EOCM_F_FO
 SG_ LnMrkg4LnSnsLnCrvt : 31|16@0- (9.53E-007,0) [-0.031227904|0.031226951] "1/m"  EOCM2A_IMX6_FO,EOCM2A_K2_FO,EOCM2A_K1_FO,EOCM2B_IMX6_FO,EOCM2B_K2_FO,EOCM2B_K1_FO,EOCM_F_FO
 SG_ LnMrkg4LnQltyConfLvl : 63|7@0+ (0.7874016,0) [0|100.0000032] "%"  EOCM2A_IMX6_FO,EOCM2A_K2_FO,EOCM2A_K1_FO,EOCM2B_IMX6_FO,EOCM2B_K2_FO,EOCM2B_K1_FO,EOCM_F_FO
 SG_ LnMrkg4LnMrkrTyp : 4|3@0+ (1,0) [0|7] ""  EOCM2A_IMX6_FO,EOCM2A_K2_FO,EOCM2A_K1_FO,EOCM2B_IMX6_FO,EOCM2B_K2_FO,EOCM2B_K1_FO,EOCM_F_FO
 SG_ LnSnsBrstID4 : 1|2@0+ (1,0) [0|3] ""  EOCM2A_IMX6_FO,EOCM2A_K2_FO,EOCM2A_K1_FO,EOCM2B_IMX6_FO,EOCM2B_K2_FO,EOCM2B_K1_FO,EOCM_F_FO

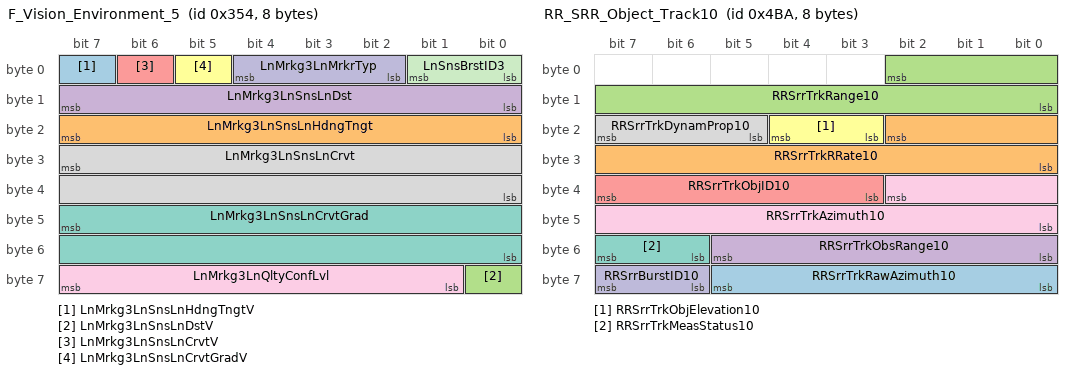
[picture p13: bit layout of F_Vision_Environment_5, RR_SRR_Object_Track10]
BO_ 852 F_Vision_Environment_5: 8 VIS2_FO
 SG_ LnMrkg3LnSnsLnHdngTngtV : 7|1@0+ (1,0) [0|1] ""  EOCM2A_IMX6_FO,EOCM2A_K2_FO,EOCM2A_K1_FO,EOCM2B_IMX6_FO,EOCM2B_K2_FO,EOCM2B_K1_FO,EOCM_F_FO
 SG_ LnMrkg3LnSnsLnHdngTngt : 23|8@0- (0.002,0) [-0.256|0.254] "m/m"  EOCM2A_IMX6_FO,EOCM2A_K2_FO,EOCM2A_K1_FO,EOCM2B_IMX6_FO,EOCM2B_K2_FO,EOCM2B_K1_FO,EOCM_F_FO
 SG_ LnMrkg3LnSnsLnDstV : 56|1@0+ (1,0) [0|1] ""  EOCM2A_IMX6_FO,EOCM2A_K2_FO,EOCM2A_K1_FO,EOCM2B_IMX6_FO,EOCM2B_K2_FO,EOCM2B_K1_FO,EOCM_F_FO
 SG_ LnMrkg3LnSnsLnDst : 15|8@0- (0.1,0) [-12.8|12.7] "m"  EOCM2A_IMX6_FO,EOCM2A_K2_FO,EOCM2A_K1_FO,EOCM2B_IMX6_FO,EOCM2B_K2_FO,EOCM2B_K1_FO,EOCM_F_FO
 SG_ LnMrkg3LnSnsLnCrvtV : 6|1@0+ (1,0) [0|1] ""  EOCM2A_IMX6_FO,EOCM2A_K2_FO,EOCM2A_K1_FO,EOCM2B_IMX6_FO,EOCM2B_K2_FO,EOCM2B_K1_FO,EOCM_F_FO
 SG_ LnMrkg3LnSnsLnCrvtGradV : 5|1@0+ (1,0) [0|1] ""  EOCM2A_IMX6_FO,EOCM2A_K2_FO,EOCM2A_K1_FO,EOCM2B_IMX6_FO,EOCM2B_K2_FO,EOCM2B_K1_FO,EOCM_F_FO
 SG_ LnMrkg3LnSnsLnCrvtGrad : 47|16@0- (5.96E-008,0) [-0.0019529728|0.0019529132] "1/(m*sec)"  EOCM2A_IMX6_FO,EOCM2A_K2_FO,EOCM2A_K1_FO,EOCM2B_IMX6_FO,EOCM2B_K2_FO,EOCM2B_K1_FO,EOCM_F_FO
 SG_ LnMrkg3LnSnsLnCrvt : 31|16@0- (9.53E-007,0) [-0.031227904|0.031226951] "1/m"  EOCM2A_IMX6_FO,EOCM2A_K2_FO,EOCM2A_K1_FO,EOCM2B_IMX6_FO,EOCM2B_K2_FO,EOCM2B_K1_FO,EOCM_F_FO
 SG_ LnMrkg3LnQltyConfLvl : 63|7@0+ (0.7874016,0) [0|100.0000032] "%"  EOCM2A_IMX6_FO,EOCM2A_K2_FO,EOCM2A_K1_FO,EOCM2B_IMX6_FO,EOCM2B_K2_FO,EOCM2B_K1_FO,EOCM_F_FO
 SG_ LnMrkg3LnMrkrTyp : 4|3@0+ (1,0) [0|7] ""  EOCM2A_IMX6_FO,EOCM2A_K2_FO,EOCM2A_K1_FO,EOCM2B_IMX6_FO,EOCM2B_K2_FO,EOCM2B_K1_FO,EOCM_F_FO
 SG_ LnSnsBrstID3 : 1|2@0+ (1,0) [0|3] ""  EOCM2A_IMX6_FO,EOCM2A_K2_FO,EOCM2A_K1_FO,EOCM2B_IMX6_FO,EOCM2B_K2_FO,EOCM2B_K1_FO,EOCM_F_FO

BO_ 602 USDT_Req_to_RRSRR: 8 TestTool_FO
 SG_ DgnInf : 7|64@0+ (1,0) [0|1.84467440737096E+019] ""  RRSRR_FO

BO_ 1626 USDT_Resp_From_RRSRR: 8 RRSRR_FO
 SG_ DgnInf_OBJ65A : 7|64@0+ (1,0) [0|1.84467440737096E+019] ""  TestTool_FO

BO_ 1370 UUDT_Resp_From_RRSRR: 8 RRSRR_FO
 SG_ DgnInf_OBJ55A : 7|64@0+ (1,0) [0|1.84467440737096E+019] ""  TestTool_FO

BO_ 1536 RR_SRR_Trace_data: 8 RRSRR_FO
 SG_ RRSRRYear : 7|8@0+ (1,0) [0|0] ""  EOCM_F_FO
 SG_ RRSRRSerialNmbr : 39|32@0+ (1,0) [0|0] ""  EOCM_F_FO
 SG_ RRSRRJulianDate : 15|24@0+ (1,0) [0|0] ""  EOCM_F_FO

BO_ 1210 RR_SRR_Object_Track10: 8 RRSRR_FO
 SG_ RRSrrTrkRawAzimuth10 : 61|6@0- (1,0) [-32|31] "deg"  EOCM_F_FO
 SG_ RRSrrTrkRRate10 : 18|11@0- (0.125,0) [-128|127.875] "m/s"  EOCM_F_FO
 SG_ RRSrrTrkRange10 : 2|11@0+ (0.02,0) [0|40.94] "m"  EOCM_F_FO
 SG_ RRSrrTrkObsRange10 : 53|6@0- (0.02,0) [-0.64|0.62] "m"  EOCM_F_FO
 SG_ RRSrrTrkObjID10 : 39|5@0+ (1,0) [0|31] ""  EOCM_F_FO
 SG_ RRSrrTrkObjElevation10 : 20|2@0+ (1,0) [0|3] ""  EOCM_F_FO
 SG_ RRSrrTrkMeasStatus10 : 55|2@0+ (1,0) [0|3] ""  EOCM_F_FO
 SG_ RRSrrTrkDynamProp10 : 23|3@0+ (1,0) [0|7] ""  EOCM_F_FO
 SG_ RRSrrTrkAzimuth10 : 34|11@0- (0.125,0) [-128|127.875] "deg"  EOCM_F_FO
 SG_ RRSrrBurstID10 : 63|2@0+ (1,0) [0|3] ""  EOCM_F_FO

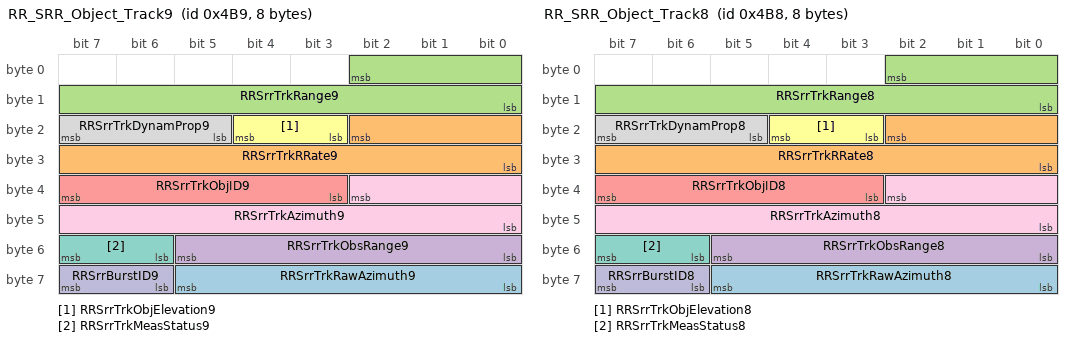
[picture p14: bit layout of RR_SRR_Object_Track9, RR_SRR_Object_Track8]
BO_ 1209 RR_SRR_Object_Track9: 8 RRSRR_FO
 SG_ RRSrrTrkRawAzimuth9 : 61|6@0- (1,0) [-32|31] "deg"  EOCM_F_FO
 SG_ RRSrrTrkRRate9 : 18|11@0- (0.125,0) [-128|127.875] "m/s"  EOCM_F_FO
 SG_ RRSrrTrkRange9 : 2|11@0+ (0.02,0) [0|40.94] "m"  EOCM_F_FO
 SG_ RRSrrTrkObsRange9 : 53|6@0- (0.02,0) [-0.64|0.62] "m"  EOCM_F_FO
 SG_ RRSrrTrkObjID9 : 39|5@0+ (1,0) [0|31] ""  EOCM_F_FO
 SG_ RRSrrTrkObjElevation9 : 20|2@0+ (1,0) [0|3] ""  EOCM_F_FO
 SG_ RRSrrTrkMeasStatus9 : 55|2@0+ (1,0) [0|3] ""  EOCM_F_FO
 SG_ RRSrrTrkDynamProp9 : 23|3@0+ (1,0) [0|7] ""  EOCM_F_FO
 SG_ RRSrrTrkAzimuth9 : 34|11@0- (0.125,0) [-128|127.875] "deg"  EOCM_F_FO
 SG_ RRSrrBurstID9 : 63|2@0+ (1,0) [0|3] ""  EOCM_F_FO

BO_ 1208 RR_SRR_Object_Track8: 8 RRSRR_FO
 SG_ RRSrrTrkRawAzimuth8 : 61|6@0- (1,0) [-32|31] "deg"  EOCM_F_FO
 SG_ RRSrrTrkRRate8 : 18|11@0- (0.125,0) [-128|127.875] "m/s"  EOCM_F_FO
 SG_ RRSrrTrkRange8 : 2|11@0+ (0.02,0) [0|40.94] "m"  EOCM_F_FO
 SG_ RRSrrTrkObsRange8 : 53|6@0- (0.02,0) [-0.64|0.62] "m"  EOCM_F_FO
 SG_ RRSrrTrkObjID8 : 39|5@0+ (1,0) [0|31] ""  EOCM_F_FO
 SG_ RRSrrTrkObjElevation8 : 20|2@0+ (1,0) [0|3] ""  EOCM_F_FO
 SG_ RRSrrTrkMeasStatus8 : 55|2@0+ (1,0) [0|3] ""  EOCM_F_FO
 SG_ RRSrrTrkDynamProp8 : 23|3@0+ (1,0) [0|7] ""  EOCM_F_FO
 SG_ RRSrrTrkAzimuth8 : 34|11@0- (0.125,0) [-128|127.875] "deg"  EOCM_F_FO
 SG_ RRSrrBurstID8 : 63|2@0+ (1,0) [0|3] ""  EOCM_F_FO

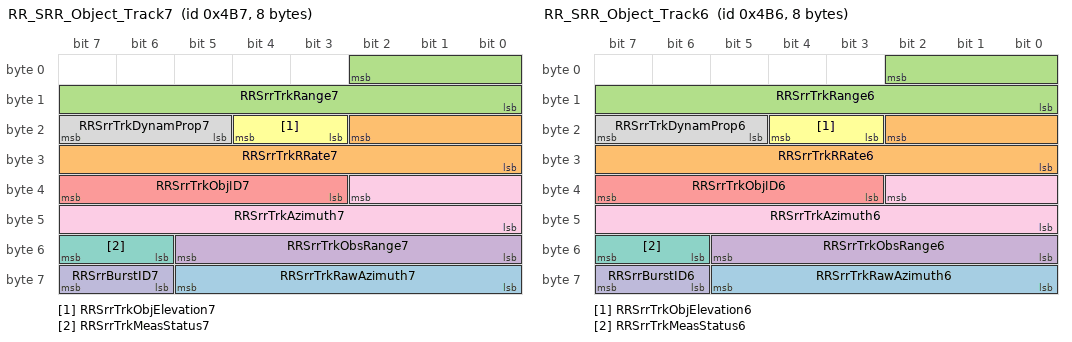
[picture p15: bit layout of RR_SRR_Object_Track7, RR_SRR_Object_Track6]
BO_ 1207 RR_SRR_Object_Track7: 8 RRSRR_FO
 SG_ RRSrrTrkRawAzimuth7 : 61|6@0- (1,0) [-32|31] "deg"  EOCM_F_FO
 SG_ RRSrrTrkRRate7 : 18|11@0- (0.125,0) [-128|127.875] "m/s"  EOCM_F_FO
 SG_ RRSrrTrkRange7 : 2|11@0+ (0.02,0) [0|40.94] "m"  EOCM_F_FO
 SG_ RRSrrTrkObsRange7 : 53|6@0- (0.02,0) [-0.64|0.62] "m"  EOCM_F_FO
 SG_ RRSrrTrkObjID7 : 39|5@0+ (1,0) [0|31] ""  EOCM_F_FO
 SG_ RRSrrTrkObjElevation7 : 20|2@0+ (1,0) [0|3] ""  EOCM_F_FO
 SG_ RRSrrTrkMeasStatus7 : 55|2@0+ (1,0) [0|3] ""  EOCM_F_FO
 SG_ RRSrrTrkDynamProp7 : 23|3@0+ (1,0) [0|7] ""  EOCM_F_FO
 SG_ RRSrrTrkAzimuth7 : 34|11@0- (0.125,0) [-128|127.875] "deg"  EOCM_F_FO
 SG_ RRSrrBurstID7 : 63|2@0+ (1,0) [0|3] ""  EOCM_F_FO

BO_ 1206 RR_SRR_Object_Track6: 8 RRSRR_FO
 SG_ RRSrrTrkRawAzimuth6 : 61|6@0- (1,0) [-32|31] "deg"  EOCM_F_FO
 SG_ RRSrrTrkRRate6 : 18|11@0- (0.125,0) [-128|127.875] "m/s"  EOCM_F_FO
 SG_ RRSrrTrkRange6 : 2|11@0+ (0.02,0) [0|40.94] "m"  EOCM_F_FO
 SG_ RRSrrTrkObsRange6 : 53|6@0- (0.02,0) [-0.64|0.62] "m"  EOCM_F_FO
 SG_ RRSrrTrkObjID6 : 39|5@0+ (1,0) [0|31] ""  EOCM_F_FO
 SG_ RRSrrTrkObjElevation6 : 20|2@0+ (1,0) [0|3] ""  EOCM_F_FO
 SG_ RRSrrTrkMeasStatus6 : 55|2@0+ (1,0) [0|3] ""  EOCM_F_FO
 SG_ RRSrrTrkDynamProp6 : 23|3@0+ (1,0) [0|7] ""  EOCM_F_FO
 SG_ RRSrrTrkAzimuth6 : 34|11@0- (0.125,0) [-128|127.875] "deg"  EOCM_F_FO
 SG_ RRSrrBurstID6 : 63|2@0+ (1,0) [0|3] ""  EOCM_F_FO

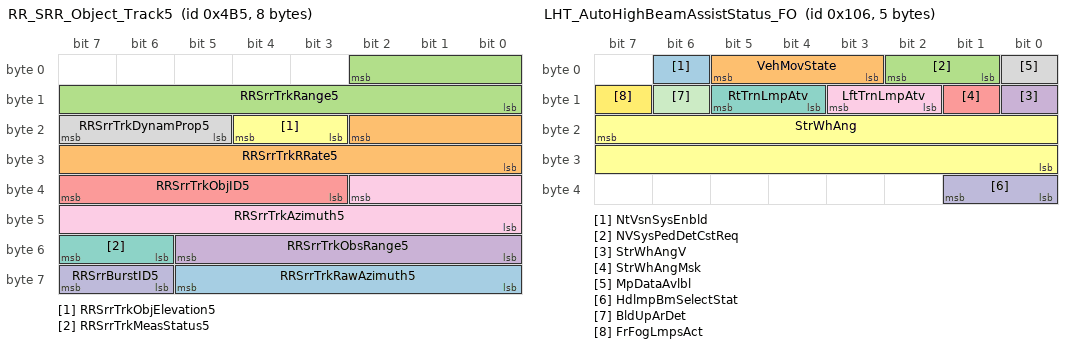
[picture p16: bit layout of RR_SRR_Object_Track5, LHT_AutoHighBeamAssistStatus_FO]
BO_ 1205 RR_SRR_Object_Track5: 8 RRSRR_FO
 SG_ RRSrrTrkRawAzimuth5 : 61|6@0- (1,0) [-32|31] "deg"  EOCM_F_FO
 SG_ RRSrrTrkRRate5 : 18|11@0- (0.125,0) [-128|127.875] "m/s"  EOCM_F_FO
 SG_ RRSrrTrkRange5 : 2|11@0+ (0.02,0) [0|40.94] "m"  EOCM_F_FO
 SG_ RRSrrTrkObsRange5 : 53|6@0- (0.02,0) [-0.64|0.62] "m"  EOCM_F_FO
 SG_ RRSrrTrkObjID5 : 39|5@0+ (1,0) [0|31] ""  EOCM_F_FO
 SG_ RRSrrTrkObjElevation5 : 20|2@0+ (1,0) [0|3] ""  EOCM_F_FO
 SG_ RRSrrTrkMeasStatus5 : 55|2@0+ (1,0) [0|3] ""  EOCM_F_FO
 SG_ RRSrrTrkDynamProp5 : 23|3@0+ (1,0) [0|7] ""  EOCM_F_FO
 SG_ RRSrrTrkAzimuth5 : 34|11@0- (0.125,0) [-128|127.875] "deg"  EOCM_F_FO
 SG_ RRSrrBurstID5 : 63|2@0+ (1,0) [0|3] ""  EOCM_F_FO

BO_ 262 LHT_AutoHighBeamAssistStatus_FO: 5 EOCM_F_FO
 SG_ NtVsnSysEnbld : 6|1@0+ (1,0) [0|1] ""  EOCM2B_IMX6_FO,EOCM2B_K2_FO,EOCM2B_K1_FO,NVS_FO
 SG_ VehMovState : 5|3@0+ (1,0) [0|7] ""  EOCM2B_IMX6_FO,EOCM2B_K2_FO,EOCM2B_K1_FO,NVS_FO
 SG_ NVSysPedDetCstReq : 2|2@0+ (1,0) [0|3] ""  EOCM2B_IMX6_FO,EOCM2B_K2_FO,EOCM2B_K1_FO,NVS_FO
 SG_ StrWhAngV : 8|1@0+ (1,0) [0|1] ""  EOCM2B_IMX6_FO,EOCM2B_K2_FO,EOCM2B_K1_FO,NVS_FO,VIS_FO
 SG_ StrWhAngMsk : 9|1@0+ (1,0) [0|1] ""  EOCM2B_IMX6_FO,EOCM2B_K2_FO,EOCM2B_K1_FO,VIS_FO
 SG_ StrWhAng : 23|16@0- (0.0625,0) [-2048|2047.9375] "deg"  EOCM2B_IMX6_FO,EOCM2B_K2_FO,EOCM2B_K1_FO,NVS_FO,VIS_FO
 SG_ RtTrnLmpAtv : 13|2@0+ (1,0) [0|3] ""  EOCM2B_IMX6_FO,EOCM2B_K2_FO,EOCM2B_K1_FO,VIS_FO
 SG_ MpDataAvlbl : 0|1@0+ (1,0) [0|1] ""  EOCM2B_IMX6_FO,EOCM2B_K2_FO,EOCM2B_K1_FO,VIS_FO
 SG_ LftTrnLmpAtv : 11|2@0+ (1,0) [0|3] ""  EOCM2B_IMX6_FO,EOCM2B_K2_FO,EOCM2B_K1_FO,VIS_FO
 SG_ HdlmpBmSelectStat : 33|2@0+ (1,0) [0|3] ""  EOCM2B_IMX6_FO,EOCM2B_K2_FO,EOCM2B_K1_FO,VIS_FO
 SG_ BldUpArDet : 14|1@0+ (1,0) [0|1] ""  EOCM2B_IMX6_FO,EOCM2B_K2_FO,EOCM2B_K1_FO,VIS_FO
 SG_ FrFogLmpsAct : 15|1@0+ (1,0) [0|1] ""  EOCM2B_IMX6_FO,EOCM2B_K2_FO,EOCM2B_K1_FO,NVS_FO,VIS_FO

BO_ 309 LHT_CameraObjConfirmation_FO: 1 VIS_FO
 SG_ HiBmRecmnd : 1|1@0+ (1,0) [0|1] ""  EOCM_F_FO
 SG_ CtLghtDet : 0|1@0+ (1,0) [0|1] ""  EOCM_F_FO

BO_ 2034 CCP_Data_Transmission_Object_FO: 8 VIS2_FO
 SG_ DgnInf : 7|64@0+ (1,0) [0|1.84467440737096E+019] ""  TestTool_FO

BO_ 2032 CCP_Command_Receive_Object_FO: 8 TestTool_FO
 SG_ DgnInf : 7|64@0+ (1,0) [0|1.84467440737096E+019] ""  VIS2_FO

BO_ 1362 F_Vis_Obj_Conf_CPS_1B: 8 EOCM_F_FO
 SG_ FObjConfCPSTrkObjectIDB : 7|6@0+ (1,0) [0|63] ""  VIS_FO
 SG_ CPSVisConfLonPos1 : 20|12@0- (0.125,0) [-256|255.875] "m"  VIS_FO
 SG_ CPSVisConfLatPos1 : 15|10@0- (0.125,0) [-64|63.875] "m"  VIS_FO
 SG_ CPSVisConfChecksum : 50|11@0+ (1,0) [0|2047] ""  VIS_FO
 SG_ FObjConfCPSTrkRangeRate : 45|11@0- (0.125,0) [-128|127.875] "m/s"  VIS_FO
 SG_ CPSConfTimeStamp : 24|11@0+ (1,0) [0|2047] "ms"  VIS_FO
 SG_ CPSConfTimeStampV : 21|1@0+ (1,0) [0|1] ""  VIS_FO
 SG_ FObjConfCPSRollingTrkCnt : 1|2@0+ (1,0) [0|3] ""  VIS_FO

BO_ 1413 TOS_ACC_IDS: 5 EOCM_F_FO
 SG_ TOS_ACC_IDSRollCnt : 7|2@0+ (1,0) [0|3] ""  Dummy_FO
 SG_ TOS_ACC_IDSFuncState : 5|2@0+ (1,0) [0|3] ""  Dummy_FO
 SG_ TOS_ACC_ID1 : 3|6@0+ (1,0) [0|63] ""  Dummy_FO
 SG_ TOS_ACC_ID2 : 13|6@0+ (1,0) [0|63] ""  Dummy_FO
 SG_ TOS_ACC_ID3 : 23|6@0+ (1,0) [0|63] ""  Dummy_FO
 SG_ TOS_ACC_ID4 : 17|6@0+ (1,0) [0|63] ""  Dummy_FO
 SG_ TOS_ACC_ID5 : 27|6@0+ (1,0) [0|63] ""  Dummy_FO
 SG_ TOS_ACC_ID6 : 37|6@0+ (1,0) [0|63] ""  Dummy_FO

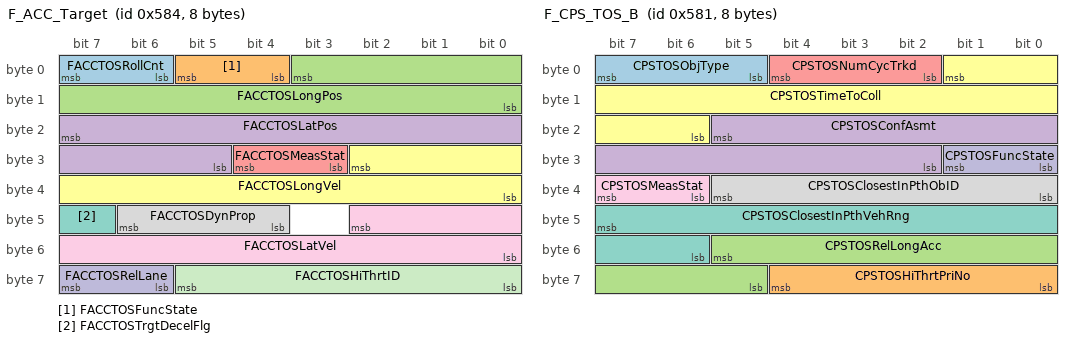
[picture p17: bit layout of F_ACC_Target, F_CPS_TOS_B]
BO_ 1412 F_ACC_Target: 8 EOCM_F_FO
 SG_ FACCTOSRollCnt : 7|2@0+ (1,0) [0|3] ""  Dummy_FO
 SG_ FACCTOSFuncState : 5|2@0+ (1,0) [0|3] ""  Dummy_FO
 SG_ FACCTOSLongPos : 3|12@0- (0.125,0) [-256|255.875] "m"  Dummy_FO
 SG_ FACCTOSLatPos : 23|11@0- (0.125,0) [-128|127.875] "m"  Dummy_FO
 SG_ FACCTOSMeasStat : 28|2@0+ (1,0) [0|3] ""  Dummy_FO
 SG_ FACCTOSLongVel : 26|11@0- (0.125,0) [-128|127.875] "m/s"  Dummy_FO
 SG_ FACCTOSTrgtDecelFlg : 47|1@0+ (1,0) [0|1] ""  Dummy_FO
 SG_ FACCTOSDynProp : 46|3@0+ (1,0) [0|7] ""  Dummy_FO
 SG_ FACCTOSLatVel : 42|11@0- (0.125,0) [-128|127.875] "m/s"  Dummy_FO
 SG_ FACCTOSRelLane : 63|2@0+ (1,0) [0|3] ""  Dummy_FO
 SG_ FACCTOSHiThrtID : 61|6@0+ (1,0) [0|63] ""  Dummy_FO

BO_ 1409 F_CPS_TOS_B: 8 EOCM_F_FO
 SG_ CPSTOSObjType : 7|3@0+ (1,0) [0|7] ""  Dummy_FO
 SG_ CPSTOSHiThrtPriNo : 60|5@0+ (1,0) [0|31] ""  Dummy_FO
 SG_ CPSTOSRelLongAcc : 53|9@0- (0.125,0) [-32|31.875] "m/s^2"  Dummy_FO
 SG_ CPSTOSConfAsmt : 21|12@0+ (1,0) [0|4095] ""  Dummy_FO
 SG_ CPSTOSNumCycTrkd : 4|3@0+ (1,0) [0|7] ""  Dummy_FO
 SG_ CPSTOSTimeToColl : 1|12@0+ (0.025,0) [0|102.375] "s"  Dummy_FO
 SG_ CPSTOSClosestInPthVehRng : 47|10@0+ (0.25,0) [0|255.75] "m"  Dummy_FO
 SG_ CPSTOSClosestInPthObID : 37|6@0+ (1,0) [0|63] "m"  Dummy_FO
 SG_ CPSTOSMeasStat : 39|2@0+ (1,0) [0|3] ""  Dummy_FO
 SG_ CPSTOSFuncState : 25|2@0+ (1,0) [0|3] ""  Dummy_FO

BO_ 1408 F_CPS_TOS_A: 8 EOCM_F_FO
 SG_ CPSTOSLongPos : 7|12@0- (0.125,0) [-256|255.875] "m"  Dummy_FO
 SG_ CPSTOSLatPos : 11|11@0- (0.125,0) [-128|127.875] "m"  Dummy_FO
 SG_ CPSTOSLongVel : 16|11@0- (0.125,0) [-128|127.875] "m/s"  Dummy_FO
 SG_ CPSTOSDynProp : 37|3@0+ (1,0) [0|7] ""  Dummy_FO
 SG_ CPSTOSLatVel : 34|11@0- (0.125,0) [-128|127.875] "m/s"  Dummy_FO
 SG_ CPSTOSARelLane : 63|2@0+ (1,0) [0|3] ""  Dummy_FO
 SG_ CPSTOSHiThrtID : 61|6@0+ (1,0) [0|63] ""  Dummy_FO
 SG_ CPSTOSHighestThreatObAsmt : 55|8@0+ (1,0) [0|255] ""  Dummy_FO

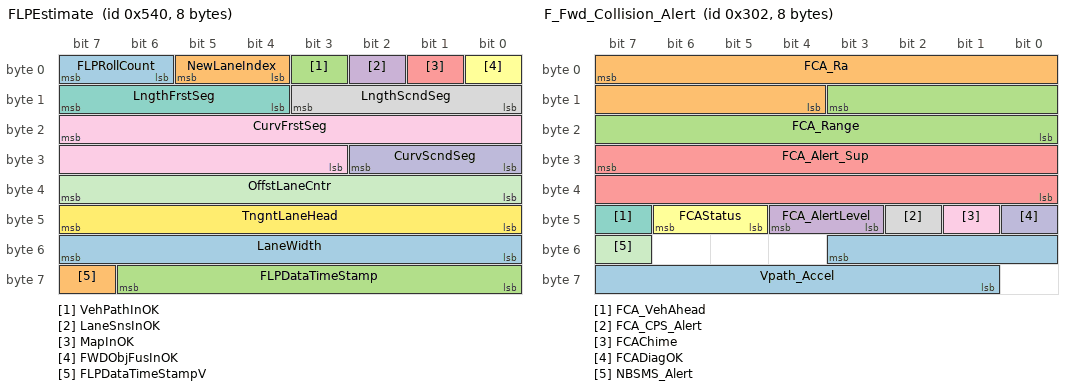
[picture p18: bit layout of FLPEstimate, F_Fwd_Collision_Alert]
BO_ 1344 FLPEstimate: 8 EOCM_F_FO
 SG_ FLPRollCount : 7|2@0+ (1,0) [0|3] ""  Dummy_FO
 SG_ NewLaneIndex : 5|2@0+ (1,0) [0|3] ""  Dummy_FO
 SG_ VehPathInOK : 3|1@0+ (1,0) [0|1] ""  Dummy_FO
 SG_ LaneSnsInOK : 2|1@0+ (1,0) [0|1] ""  Dummy_FO
 SG_ MapInOK : 1|1@0+ (1,0) [0|1] ""  Dummy_FO
 SG_ FWDObjFusInOK : 0|1@0+ (1,0) [0|1] ""  Dummy_FO
 SG_ LngthFrstSeg : 15|4@0+ (10,0) [0|150] "m"  Dummy_FO
 SG_ LngthScndSeg : 11|4@0+ (10,0) [0|150] "m"  Dummy_FO
 SG_ CurvFrstSeg : 23|13@0- (5E-005,0) [-0.2048|0.20475] "1/m"  Dummy_FO
 SG_ CurvScndSeg : 26|3@0- (0.001,0) [-0.004|0.003] "1/m"  Dummy_FO
 SG_ OffstLaneCntr : 39|8@0- (0.05,0) [-6.4|6.35] "m"  Dummy_FO
 SG_ TngntLaneHead : 47|8@0- (0.002,0) [-0.256|0.254] "m/m"  Dummy_FO
 SG_ LaneWidth : 55|8@0+ (0.05,0) [0|12.75] "m"  Dummy_FO
 SG_ FLPDataTimeStampV : 63|1@0+ (1,0) [0|1] ""  Dummy_FO
 SG_ FLPDataTimeStamp : 62|7@0+ (16,0) [0|2032] "ms"  Dummy_FO

BO_ 770 F_Fwd_Collision_Alert: 8 EOCM_F_FO
 SG_ Vpath_Accel : 51|11@0- (0.125,0) [-128|127.875] "m/s^2"  NVS_FO,Dummy_FO
 SG_ FCA_Ra : 7|12@0- (0.125,0) [-256|255.875] "m"  Dummy_FO
 SG_ FCA_Range : 11|12@0- (0.125,0) [-256|255.875] "m"  Dummy_FO
 SG_ FCA_AlertLevel : 44|2@0+ (1,0) [0|3] ""  Dummy_FO
 SG_ FCA_Alert_Sup : 31|16@0+ (1,0) [0|65535] ""  Dummy_FO
 SG_ FCAStatus : 46|2@0+ (1,0) [0|3] ""  Dummy_FO
 SG_ FCA_VehAhead : 47|1@0+ (1,0) [0|1] ""  Dummy_FO
 SG_ FCA_CPS_Alert : 42|1@0+ (1,0) [0|1] ""  Dummy_FO
 SG_ FCAChime : 41|1@0+ (1,0) [0|1] ""  Dummy_FO
 SG_ FCADiagOK : 40|1@0+ (1,0) [0|1] ""  Dummy_FO
 SG_ NBSMS_Alert : 55|1@0+ (1,0) [0|1] ""  Dummy_FO

BO_ 1601 USDT_Resp_From_VIS: 8 VIS_FO
 SG_ DgnInf_OBJ641 : 7|64@0+ (1,0) [0|1.84467440737096E+019] ""  TestTool_FO

BO_ 1606 USDT_Resp_From_RFSRR: 8 RFSRR_FO
 SG_ DgnInf_OBJ646 : 7|64@0+ (1,0) [0|1.84467440737096E+019] ""  TestTool_FO

BO_ 1603 USDT_Resp_From_LFSRR: 8 LFSRR_FO
 SG_ DgnInf_OBJ643 : 7|64@0+ (1,0) [0|1.84467440737096E+019] ""  TestTool_FO

BO_ 1602 USDT_Resp_From_LRR: 8 LRR_FO
 SG_ DgnInf_OBJ642 : 7|64@0+ (1,0) [0|1.84467440737096E+019] ""  TestTool_FO

BO_ 1625 USDT_Resp_From_RSRR: 8 RSRR_FO
 SG_ DgnInf_OBJ644 : 7|64@0+ (1,0) [0|1.84467440737096E+019] ""  TestTool_FO

BO_ 1611 USDT_Resp_From_FEOCM_FO: 8 EOCM_F_FO
 SG_ DgnInf_OBJ64B : 7|64@0+ (1,0) [0|1.84467440737096E+019] ""  TestTool_FO

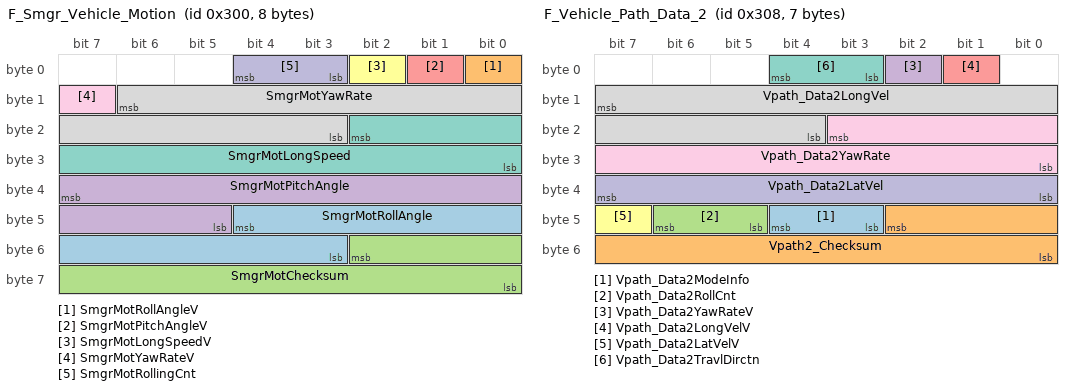
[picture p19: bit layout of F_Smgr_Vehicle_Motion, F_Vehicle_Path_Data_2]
BO_ 768 F_Smgr_Vehicle_Motion: 8 EOCM_F_FO
 SG_ SmgrMotRollAngle : 44|10@0- (0.1,0) [-51.2|51.1] "deg"  CIPM_FO,AMM_FO,EOCM2B_IMX6_FO,EOCM2B_K2_FO,EOCM2B_K1_FO,VIS_FO
 SG_ SmgrMotRollAngleV : 0|1@0+ (1,0) [0|1] ""  CIPM_FO,AMM_FO,EOCM2B_IMX6_FO,EOCM2B_K2_FO,EOCM2B_K1_FO,VIS_FO
 SG_ SmgrMotChecksum : 50|11@0+ (1,0) [0|2047] ""  CIPM_FO,AMM_FO,EOCM2B_IMX6_FO,EOCM2B_K2_FO,EOCM2B_K1_FO,VIS_FO
 SG_ SmgrMotPitchAngle : 39|11@0- (0.1,0) [-102.4|102.3] "deg"  CIPM_FO,NVS_FO,AMM_FO,EOCM2B_IMX6_FO,EOCM2B_K2_FO,EOCM2B_K1_FO,VIS_FO
 SG_ SmgrMotPitchAngleV : 1|1@0+ (1,0) [0|1] ""  CIPM_FO,NVS_FO,AMM_FO,EOCM2B_IMX6_FO,EOCM2B_K2_FO,EOCM2B_K1_FO,VIS_FO
 SG_ SmgrMotLongSpeedV : 2|1@0+ (1,0) [0|1] " "  CIPM_FO,AMM_FO,EOCM2B_IMX6_FO,EOCM2B_K2_FO,EOCM2B_K1_FO,VIS_FO
 SG_ SmgrMotLongSpeed : 18|11@0- (0.1,0) [-102.4|102.3] "m/s"  CIPM_FO,AMM_FO,EOCM2B_IMX6_FO,EOCM2B_K2_FO,EOCM2B_K1_FO,VIS_FO
 SG_ SmgrMotYawRate : 14|12@0- (0.05,0) [-102.4|102.35] "deg/s"  CIPM_FO,AMM_FO,EOCM2B_IMX6_FO,EOCM2B_K2_FO,EOCM2B_K1_FO,VIS_FO
 SG_ SmgrMotYawRateV : 15|1@0+ (1,0) [0|1] ""  CIPM_FO,AMM_FO,EOCM2B_IMX6_FO,EOCM2B_K2_FO,EOCM2B_K1_FO,VIS_FO
 SG_ SmgrMotRollingCnt : 4|2@0+ (1,0) [0|3] ""  CIPM_FO,AMM_FO,EOCM2B_IMX6_FO,EOCM2B_K2_FO,EOCM2B_K1_FO,VIS_FO

BO_ 1350 UUDT_Resp_From_RFSRR: 8 RFSRR_FO
 SG_ DgnInf_OBJ546 : 7|64@0+ (1,0) [0|1.84467440737096E+019] ""  TestTool_FO

BO_ 1369 UUDT_Resp_From_RSRR: 8 RSRR_FO
 SG_ DgnInf_OBJ544 : 7|64@0+ (1,0) [0|1.84467440737096E+019] ""  TestTool_FO

BO_ 1347 UUDT_Resp_From_LFSRR: 8 LFSRR_FO
 SG_ DgnInf_OBJ543 : 7|64@0+ (1,0) [0|1.84467440737096E+019] ""  TestTool_FO

BO_ 1346 UUDT_Resp_From_LRR: 8 LRR_FO
 SG_ DgnInf_OBJ542 : 7|64@0+ (1,0) [0|1.84467440737096E+019] ""  TestTool_FO

BO_ 1345 UUDT_Resp_From_VIS: 8 VIS_FO
 SG_ DgnInf_OBJ541 : 7|64@0+ (1,0) [0|1.84467440737096E+019] ""  TestTool_FO

BO_ 579 USDT_Req_to_LFSRR: 8 TestTool_FO
 SG_ DgnInf : 7|64@0+ (1,0) [0|1.84467440737096E+019] ""  LFSRR_FO

BO_ 577 USDT_Req_to_VIS: 8 TestTool_FO
 SG_ DgnInf : 7|64@0+ (1,0) [0|1.84467440737096E+019] ""  VIS_FO

BO_ 578 USDT_Req_to_LRR: 8 TestTool_FO
 SG_ DgnInf : 7|64@0+ (1,0) [0|1.84467440737096E+019] ""  LRR_FO

BO_ 582 USDT_Req_to_RFSRR: 8 TestTool_FO
 SG_ DgnInf : 7|64@0+ (1,0) [0|1.84467440737096E+019] ""  RFSRR_FO

BO_ 601 USDT_Req_to_RSRR: 8 TestTool_FO
 SG_ DgnInf : 7|64@0+ (1,0) [0|1.84467440737096E+019] ""  RSRR_FO

BO_ 1355 UUDT_Resp_From_FEOCM_FO: 8 EOCM_F_FO
 SG_ DgnInf_OBJ54B : 7|64@0+ (1,0) [0|1.84467440737096E+019] ""  TestTool_FO

BO_ 587 USDT_Req_to_FEOCM_obj: 8 TestTool_FO
 SG_ DgnInf : 7|64@0+ (1,0) [0|1.84467440737096E+019] ""  EOCM2A_K2_FO,EOCM_F_FO

BO_ 784 Body_Info_FOB: 6 EOCM_F_FO
 SG_ StrgColUpDwnPos : 39|8@0+ (1,0) [0|255] ""  DMS_FO
 SG_ CPMAPINFO4 : 47|1@0+ (1,0) [0|1] ""  DMS_FO
 SG_ StrgColInOutPos : 31|8@0+ (1,0) [0|255] ""  DMS_FO
 SG_ StrgColCommsFlt : 19|2@0+ (1,0) [0|3] ""  DMS_FO
 SG_ DrDoorOpenSwActV : 16|1@0+ (1,0) [0|1] ""  DMS_FO
 SG_ DrDoorOpenSwAct : 17|1@0+ (1,0) [0|1] ""  DMS_FO
 SG_ DrvWndPosStat : 22|3@0+ (1,0) [0|7] ""  CIPM_FO,DMS_FO,VIS2_FO,AMM_FO,EOCM2B_IMX6_FO,EOCM2B_K2_FO,EOCM2B_K1_FO
 SG_ InterLghtStat : 23|1@0+ (1,0) [0|1] ""  CIPM_FO,DMS_FO,VIS2_FO,AMM_FO,EOCM2B_IMX6_FO,EOCM2B_K2_FO,EOCM2B_K1_FO
 SG_ DrvrHndsOnWhlZn3 : 13|1@0+ (1,0) [0|1] ""  CIPM_FO,AMM_FO,DMS_FO,VIS2_FO,EOCM2B_IMX6_FO,EOCM2B_K2_FO,EOCM2B_K1_FO
 SG_ DrvrHndsOnWhlZn2 : 14|1@0+ (1,0) [0|1] ""  CIPM_FO,AMM_FO,EOCM2B_IMX6_FO,EOCM2B_K2_FO,EOCM2B_K1_FO,DMS_FO,VIS2_FO
 SG_ DrvrHndsOnWhlZn1 : 15|1@0+ (1,0) [0|1] ""  CIPM_FO,AMM_FO,EOCM2B_IMX6_FO,EOCM2B_K2_FO,EOCM2B_K1_FO,DMS_FO,VIS2_FO
 SG_ WSWshSwAtv : 11|1@0+ (1,0) [0|1] ""  CIPM_FO,EOCM2B_IMX6_FO,EOCM2B_K2_FO,EOCM2B_K1_FO,DMS_FO,AMM_FO,VIS_FO,VIS2_FO
 SG_ SysPwrMdV : 8|1@0+ (1,0) [0|1] ""  NVS_FO,RRSRR_FO,VIS_FO,RSRR_FO,RFSRR_FO,LRR_FO,LFSRR_FO,LRSRR_FO,CIPM_FO,_DOFIMU2_FO,_DOFIMU1_FO,DMS_FO,AMM_FO,EOCM2B_IMX6_FO,EOCM2B_K2_FO,EOCM2B_K1_FO,EOCM2A_IMX6_FO,EOCM2A_K2_FO,EOCM2A_K1_FO,VIS2_FO
 SG_ SysPwrMd : 10|2@0+ (1,0) [0|3] ""  NVS_FO,RRSRR_FO,VIS_FO,RSRR_FO,RFSRR_FO,LRR_FO,LFSRR_FO,LRSRR_FO,CIPM_FO,_DOFIMU2_FO,_DOFIMU1_FO,DMS_FO,AMM_FO,EOCM2B_IMX6_FO,EOCM2B_K2_FO,EOCM2B_K1_FO,EOCM2A_IMX6_FO,EOCM2A_K2_FO,EOCM2A_K1_FO,VIS2_FO
 SG_ WSWprAct : 2|1@0+ (1,0) [0|1] ""  CIPM_FO,EOCM2B_IMX6_FO,EOCM2B_K2_FO,EOCM2B_K1_FO,DMS_FO,AMM_FO,NVS_FO,VIS_FO,VIS2_FO
 SG_ RtLwBmFld : 4|1@0+ (1,0) [0|1] ""  CIPM_FO,EOCM2B_IMX6_FO,EOCM2B_K2_FO,EOCM2B_K1_FO,DMS_FO,AMM_FO,NVS_FO,VIS_FO,VIS2_FO
 SG_ OtsdAmbtLtLvlStatV : 5|1@0+ (1,0) [0|1] ""  CIPM_FO,EOCM2B_IMX6_FO,EOCM2B_K2_FO,EOCM2B_K1_FO,DMS_FO,AMM_FO,NVS_FO,VIS_FO,VIS2_FO
 SG_ OtsdAmbtLtLvlStat : 7|2@0+ (1,0) [0|3] ""  CIPM_FO,EOCM2B_IMX6_FO,EOCM2B_K2_FO,EOCM2B_K1_FO,DMS_FO,AMM_FO,NVS_FO,VIS_FO,VIS2_FO
 SG_ LowBmAct : 1|1@0+ (1,0) [0|1] ""  CIPM_FO,EOCM2B_IMX6_FO,EOCM2B_K2_FO,EOCM2B_K1_FO,DMS_FO,AMM_FO,NVS_FO,VIS_FO,VIS2_FO
 SG_ LftLwBmFld : 3|1@0+ (1,0) [0|1] ""  CIPM_FO,EOCM2B_IMX6_FO,EOCM2B_K2_FO,EOCM2B_K1_FO,DMS_FO,AMM_FO,NVS_FO,VIS_FO,VIS2_FO
 SG_ HighBmAct : 0|1@0+ (1,0) [0|1] ""  CIPM_FO,EOCM2B_IMX6_FO,EOCM2B_K2_FO,EOCM2B_K1_FO,DMS_FO,AMM_FO,NVS_FO,VIS_FO,VIS2_FO
 SG_ TrStLgMdAtv : 12|1@0+ (1,0) [0|1] ""  CIPM_FO,NVS_FO,RRSRR_FO,LRSRR_FO,_DOFIMU2_FO,_DOFIMU1_FO,DMS_FO,AMM_FO,EOCM2B_IMX6_FO,EOCM2B_K2_FO,EOCM2B_K1_FO,EOCM2A_IMX6_FO,EOCM2A_K2_FO,EOCM2A_K1_FO,LRR_FO,RFSRR_FO,LFSRR_FO,RSRR_FO,VIS_FO,VIS2_FO

BO_ 1539 RF_SRR_Trace_Data: 8 RFSRR_FO
 SG_ RFSRRYear : 7|8@0+ (1,0) [0|0] ""  EOCM_F_FO
 SG_ RFSRRSerialNmbr : 39|32@0+ (1,0) [0|0] ""  EOCM_F_FO
 SG_ RFSRRJulianDate : 15|24@0+ (1,0) [0|0] ""  EOCM_F_FO

BO_ 776 F_Vehicle_Path_Data_2: 7 EOCM_F_FO
 SG_ Vpath_Data2ModeInfo : 44|2@0+ (1,0) [0|3] ""  CIPM_FO,DMS_FO,AMM_FO,EOCM2B_IMX6_FO,EOCM2B_K2_FO,EOCM2B_K1_FO,VIS2_FO,RRSRR_FO,VIS_FO,RSRR_FO,RFSRR_FO,LRR_FO,LFSRR_FO
 SG_ Vpath2_Checksum : 42|11@0+ (1,0) [0|2047] ""  CIPM_FO,DMS_FO,AMM_FO,EOCM2B_IMX6_FO,EOCM2B_K2_FO,EOCM2B_K1_FO,VIS2_FO,RRSRR_FO,VIS_FO,RFSRR_FO,LFSRR_FO,RSRR_FO,LRR_FO
 SG_ Vpath_Data2RollCnt : 46|2@0+ (1,0) [0|3] ""  CIPM_FO,DMS_FO,AMM_FO,EOCM2B_IMX6_FO,EOCM2B_K2_FO,EOCM2B_K1_FO,VIS2_FO,RRSRR_FO,VIS_FO,RSRR_FO,RFSRR_FO,LRR_FO,LFSRR_FO
 SG_ Vpath_Data2YawRateV : 2|1@0+ (1,0) [0|1] ""  CIPM_FO,DMS_FO,AMM_FO,EOCM2B_IMX6_FO,EOCM2B_K2_FO,EOCM2B_K1_FO,VIS2_FO,NVS_FO,RRSRR_FO,VIS_FO,RSRR_FO,RFSRR_FO,LRR_FO,LFSRR_FO
 SG_ Vpath_Data2LongVelV : 1|1@0+ (1,0) [0|1] ""  CIPM_FO,DMS_FO,AMM_FO,EOCM2B_IMX6_FO,EOCM2B_K2_FO,EOCM2B_K1_FO,VIS2_FO,RRSRR_FO,NVS_FO,VIS_FO,RSRR_FO,RFSRR_FO,LRR_FO,LFSRR_FO
 SG_ Vpath_Data2LatVelV : 47|1@0+ (1,0) [0|1] ""  CIPM_FO,DMS_FO,AMM_FO,EOCM2B_IMX6_FO,EOCM2B_K2_FO,EOCM2B_K1_FO,VIS2_FO,RRSRR_FO,VIS_FO,RSRR_FO,RFSRR_FO,LRR_FO,LFSRR_FO
 SG_ Vpath_Data2TravlDirctn : 4|2@0+ (1,0) [0|3] ""  CIPM_FO,DMS_FO,AMM_FO,EOCM2B_IMX6_FO,EOCM2B_K2_FO,EOCM2B_K1_FO,VIS2_FO,RRSRR_FO,VIS_FO,RSRR_FO,RFSRR_FO,LRR_FO,LFSRR_FO
 SG_ Vpath_Data2LongVel : 15|12@0- (0.0625,0) [-128|127.9375] "m/s"  CIPM_FO,DMS_FO,AMM_FO,EOCM2B_IMX6_FO,EOCM2B_K2_FO,EOCM2B_K1_FO,VIS2_FO,RRSRR_FO,NVS_FO,VIS_FO,RSRR_FO,RFSRR_FO,LRR_FO,LFSRR_FO
 SG_ Vpath_Data2YawRate : 19|12@0- (0.0625,0) [-128|127.9375] "deg/s"  CIPM_FO,DMS_FO,AMM_FO,EOCM2B_IMX6_FO,EOCM2B_K2_FO,EOCM2B_K1_FO,VIS2_FO,NVS_FO,RRSRR_FO,VIS_FO,RSRR_FO,RFSRR_FO,LRR_FO,LFSRR_FO
 SG_ Vpath_Data2LatVel : 39|8@0- (0.05,0) [-6.4|6.35] "m/s"  CIPM_FO,DMS_FO,AMM_FO,EOCM2B_IMX6_FO,EOCM2B_K2_FO,EOCM2B_K1_FO,VIS2_FO,RRSRR_FO,VIS_FO,RSRR_FO,RFSRR_FO,LRR_FO,LFSRR_FO

BO_ 161 F_Master_Time_Sync: 7 EOCM_F_FO
 SG_ FTimeSyncMstrChksm : 35|12@0+ (1,0) [0|4095] ""  AMM_FO,CIPM_FO,EOCM2B_IMX6_FO,EOCM2B_K2_FO,EOCM2B_K1_FO,VIS2_FO,RRSRR_FO,VIS_FO,RSRR_FO,RFSRR_FO,LRR_FO,LFSRR_FO
 SG_ FTimeSyncMstrClock : 7|32@0+ (1,0) [0|4294967295] "ms"  CIPM_FO,AMM_FO,EOCM2B_IMX6_FO,EOCM2B_K2_FO,EOCM2B_K1_FO,VIS2_FO,RRSRR_FO,VIS_FO,RSRR_FO,RFSRR_FO,LRR_FO,LFSRR_FO
 SG_ SensorModeCmdLRR : 39|3@0+ (1,0) [0|7] ""  CIPM_FO,EOCM2B_IMX6_FO,EOCM2B_K2_FO,EOCM2B_K1_FO,VIS2_FO,RRSRR_FO,VIS_FO,RSRR_FO,RFSRR_FO,LRR_FO,LFSRR_FO
 SG_ SensorModeCmdSRR : 50|3@0+ (1,0) [0|7] ""  CIPM_FO,EOCM2B_IMX6_FO,EOCM2B_K2_FO,EOCM2B_K1_FO,VIS2_FO,RRSRR_FO,VIS_FO,RSRR_FO,RFSRR_FO,LRR_FO,LFSRR_FO
 SG_ SensorModeCmdFCamera : 53|3@0+ (1,0) [0|7] ""  CIPM_FO,EOCM2B_IMX6_FO,EOCM2B_K2_FO,EOCM2B_K1_FO,VIS2_FO,RRSRR_FO,VIS_FO,RSRR_FO,RFSRR_FO,LRR_FO,LFSRR_FO
 SG_ FTimeSyncMstrClockV : 36|1@0+ (1,0) [0|1] ""  CIPM_FO,AMM_FO,EOCM2B_IMX6_FO,EOCM2B_K2_FO,EOCM2B_K1_FO,VIS2_FO,RRSRR_FO,VIS_FO,RSRR_FO,LRR_FO,RFSRR_FO,LFSRR_FO
